VERSION ""

NS_ :

BS_:

BU_: PowertrainControlModule AtmosphericSensor SafetyRestraintSystem2 Aftertreatment_2_GasOutlet Aftertreatment_2_GasIntake DieselParticulateFilterControl Turbocharger SafetyRestraintSystem1 CabDisplay2 Aftertreatment_1_GasOutlet Aftertreatment_1_GasIntake OnBoardDataLogger OffBoardDiagnosticTool2 OffBoardDiagnosticTool1 FileServer ParkingBrakeController SeatController2 FanDriveController SteeringColumnUnit CommunicationUnitRadio CommunicationUnitSatellite CommunicationUnitCellular PropulsionBatteryCharger ChassisController2 ChassisController1 EngineValveControl AuxiliaryHeater2 AuxiliaryHeater1 ClutchUnit RampControl InformationSystem1 SuspensionSystemController2 OilSensor VehicleDynamicStability ExhaustEmissionController TransmissionDisplay2 TransmissionDisplay1 ClimateControl2 WaterPumpController RearAxleSteeringController LightingOperatorControl SeatController1 IgnitionController2 IgnitionController1 TirePressureController CabController2 CabController1 PneumaticSystemController SuspensionSystemController1 HydraulicPumpController EnduranceBrakingSystem RetarderExhaustEngine2 OnBoardDiagnosticUnit HeadwayController RetarderExhaustEngine1 CabDisplay1 ManagementComputer VirtualTerminal OffVehicleGateway PowerTakeOffFront HitchControl AuxiliaryValveControl BodyController TractorTrailerBridge1 StarterSystem ElectricalSystem VehicleSecurity VehicleNavigation AerodynamicControl ElectricalChargingSystem ClimateControl1 TripRecorder InstrumentCluster SuspensionDriveAxle2 SuspensionDriveAxle1 SuspensionSteerAxle SteeringController FuelSystem CruiseControl RetarderDriveline RetarderEngine BrakesDriveAxle2 BrakesDriveAxle1 BrakesSystemController BrakesSteerAxle AxleDrive2 AxleDrive1 AxleSteering PowerTakeOff ShiftConsoleSecondary ShiftConsolePrimary Transmission2 Transmission1 Engine2 Engine1

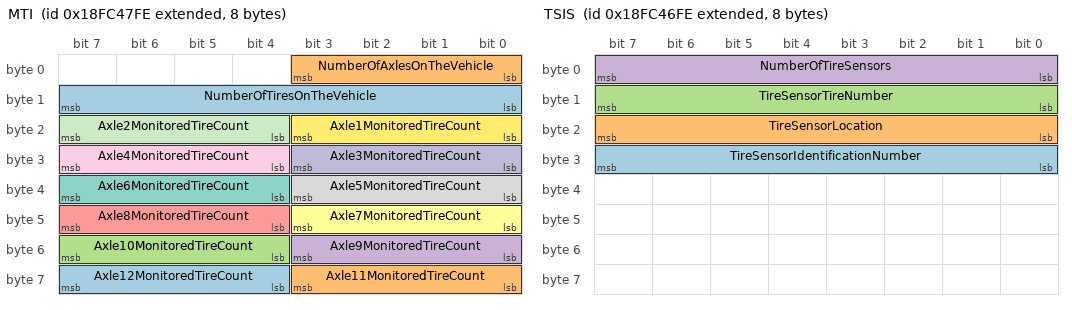
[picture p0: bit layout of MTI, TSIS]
BO_ 2566670334 MTI: 8 Vector__XXX
 SG_ Axle12MonitoredTireCount : 60|4@1+ (1,0) [0|13] "" Vector__XXX
 SG_ Axle11MonitoredTireCount : 56|4@1+ (1,0) [0|13] "" Vector__XXX
 SG_ Axle10MonitoredTireCount : 52|4@1+ (1,0) [0|13] "" Vector__XXX
 SG_ Axle9MonitoredTireCount : 48|4@1+ (1,0) [0|13] "" Vector__XXX
 SG_ Axle8MonitoredTireCount : 44|4@1+ (1,0) [0|13] "" Vector__XXX
 SG_ Axle7MonitoredTireCount : 40|4@1+ (1,0) [0|13] "" Vector__XXX
 SG_ Axle6MonitoredTireCount : 36|4@1+ (1,0) [0|13] "" Vector__XXX
 SG_ Axle5MonitoredTireCount : 32|4@1+ (1,0) [0|13] "" Vector__XXX
 SG_ Axle4MonitoredTireCount : 28|4@1+ (1,0) [0|13] "" Vector__XXX
 SG_ Axle3MonitoredTireCount : 24|4@1+ (1,0) [0|13] "" Vector__XXX
 SG_ Axle2MonitoredTireCount : 20|4@1+ (1,0) [0|13] "" Vector__XXX
 SG_ Axle1MonitoredTireCount : 16|4@1+ (1,0) [0|13] "" Vector__XXX
 SG_ NumberOfTiresOnTheVehicle : 8|8@1+ (1,0) [0|250] "" Vector__XXX
 SG_ NumberOfAxlesOnTheVehicle : 0|4@1+ (1,0) [0|13] "" Vector__XXX

BO_ 2566670078 TSIS: 8 Vector__XXX
 SG_ TireSensorIdentificationNumber : 24|8@1+ (1,0) [0|255] "" Vector__XXX
 SG_ TireSensorLocation : 16|8@1+ (1,0) [0|255] "" Vector__XXX
 SG_ TireSensorTireNumber : 8|8@1+ (1,0) [0|250] "" Vector__XXX
 SG_ NumberOfTireSensors : 0|8@1+ (1,0) [0|250] "" Vector__XXX

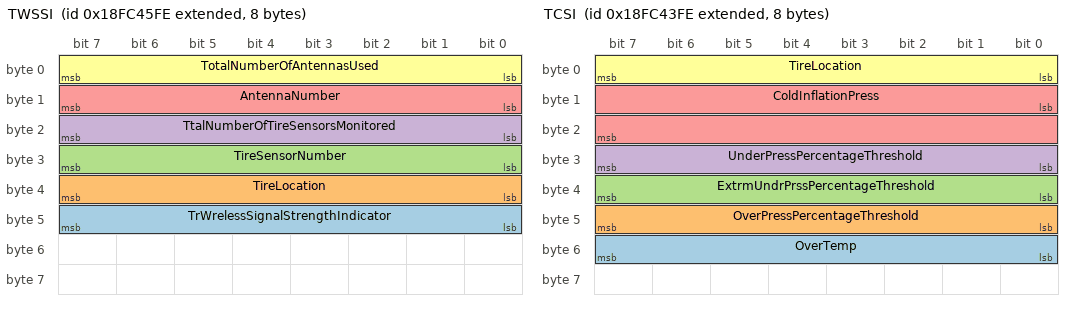
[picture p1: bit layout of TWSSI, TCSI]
BO_ 2566669822 TWSSI: 8 Vector__XXX
 SG_ TrWrelessSignalStrengthIndicator : 40|8@1+ (0.5,-125) [-125|0] "dBm" Vector__XXX
 SG_ TireLocation : 32|8@1+ (1,0) [0|0] "" Vector__XXX
 SG_ TireSensorNumber : 24|8@1+ (1,0) [0|250] "" Vector__XXX
 SG_ TtalNumberOfTireSensorsMonitored : 16|8@1+ (1,0) [0|250] "" Vector__XXX
 SG_ AntennaNumber : 8|8@1+ (1,0) [0|250] "" Vector__XXX
 SG_ TotalNumberOfAntennasUsed : 0|8@1+ (1,0) [0|250] "" Vector__XXX

BO_ 2566669310 TCSI: 8 Vector__XXX
 SG_ OverTemp : 48|8@1+ (1,-40) [-40|210] "캜" Vector__XXX
 SG_ OverPressPercentageThreshold : 40|8@1+ (0.5,0) [0|125] "%" Vector__XXX
 SG_ ExtrmUndrPrssPercentageThreshold : 32|8@1+ (0.5,0) [0|125] "%" Vector__XXX
 SG_ UnderPressPercentageThreshold : 24|8@1+ (0.5,0) [0|125] "%" Vector__XXX
 SG_ ColdInflationPress : 8|16@1+ (1,0) [0|64255] "kPa" Vector__XXX
 SG_ TireLocation : 0|8@1+ (1,0) [0|0] "" Vector__XXX

BO_ 2566669054 TIRE2: 8 Vector__XXX
 SG_ RequiredTirePress : 24|16@1+ (1,0) [0|64255] "kPa" Vector__XXX
 SG_ TirePress : 8|16@1+ (1,0) [0|64255] "kPa" Vector__XXX
 SG_ TireLocation : 0|8@1+ (1,0) [0|0] "" Vector__XXX

BO_ 2566668798 AF4: 8 Vector__XXX
 SG_ EngFl2InjctorMeteringRail1Press2 : 48|16@1+ (2,0) [0|128510] "kPa" Vector__XXX
 SG_ EngFel2InjectorMeteringRail2Temp : 40|8@1+ (1,-40) [-40|210] "캜" Vector__XXX
 SG_ EngFel2InjectorMeteringRail1Temp : 32|8@1+ (1,-40) [-40|210] "캜" Vector__XXX
 SG_ EngFl2InjectorMeteringRail2Press : 16|16@1+ (2,0) [0|128510] "kPa" Vector__XXX
 SG_ EngFl2InjectorMeteringRail1Press : 0|16@1+ (2,0) [0|128510] "kPa" Vector__XXX

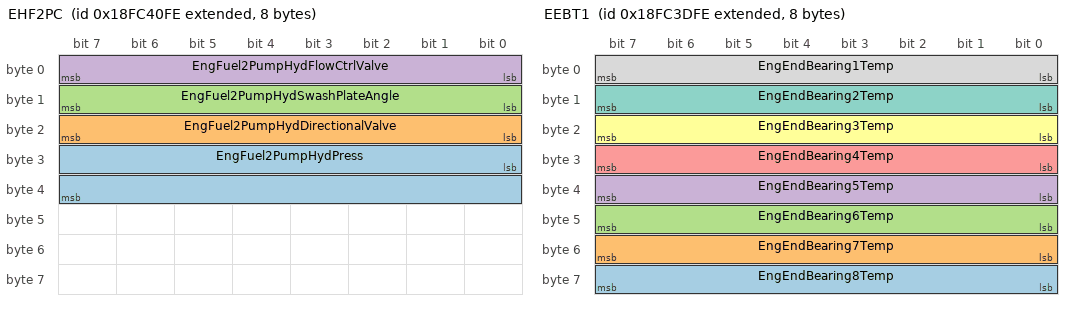
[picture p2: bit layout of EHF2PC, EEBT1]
BO_ 2566668542 EHF2PC: 8 Vector__XXX
 SG_ EngFuel2PumpHydPress : 24|16@1+ (2,0) [0|128510] "kPa" Vector__XXX
 SG_ EngFuel2PumpHydDirectionalValve : 16|8@1+ (0.4,0) [0|100] "%" Vector__XXX
 SG_ EngFuel2PumpHydSwashPlateAngle : 8|8@1+ (0.4,0) [0|100] "%" Vector__XXX
 SG_ EngFuel2PumpHydFlowCtrlValve : 0|8@1+ (0.4,0) [0|100] "%" Vector__XXX

BO_ 2566668286 ETCC2: 8 Vector__XXX
 SG_ EngStagedTurboSolenoidStatus : 0|8@1+ (0.4,0) [0|100] "%" Vector__XXX

BO_ 2566668030 HEDPI: 8 Vector__XXX
 SG_ HtExchngerDebrisPurgeApproaching : 2|2@1+ (1,0) [0|3] "" Vector__XXX
 SG_ HeatExchangerDebrisPurgeStatus : 0|2@1+ (1,0) [0|3] "" Vector__XXX

BO_ 2566667774 EEBT1: 8 Vector__XXX
 SG_ EngEndBearing8Temp : 56|8@1+ (1,-40) [-40|210] "캜" Vector__XXX
 SG_ EngEndBearing7Temp : 48|8@1+ (1,-40) [-40|210] "캜" Vector__XXX
 SG_ EngEndBearing6Temp : 40|8@1+ (1,-40) [-40|210] "캜" Vector__XXX
 SG_ EngEndBearing5Temp : 32|8@1+ (1,-40) [-40|210] "캜" Vector__XXX
 SG_ EngEndBearing4Temp : 24|8@1+ (1,-40) [-40|210] "캜" Vector__XXX
 SG_ EngEndBearing3Temp : 16|8@1+ (1,-40) [-40|210] "캜" Vector__XXX
 SG_ EngEndBearing2Temp : 8|8@1+ (1,-40) [-40|210] "캜" Vector__XXX
 SG_ EngEndBearing1Temp : 0|8@1+ (1,-40) [-40|210] "캜" Vector__XXX

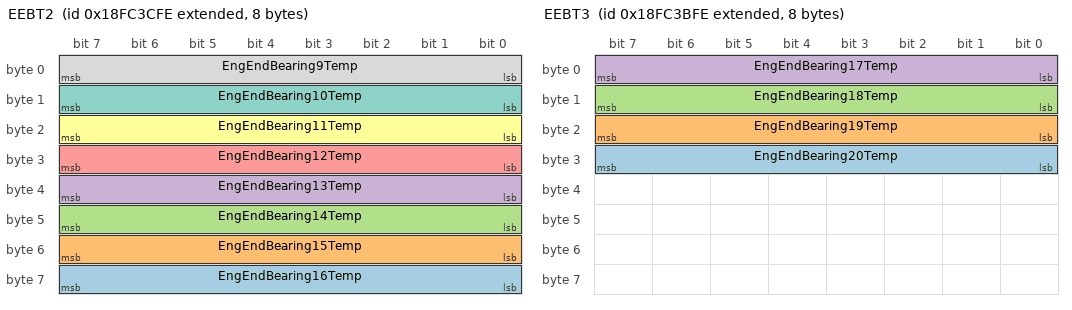
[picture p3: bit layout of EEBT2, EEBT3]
BO_ 2566667518 EEBT2: 8 Vector__XXX
 SG_ EngEndBearing16Temp : 56|8@1+ (1,-40) [-40|210] "캜" Vector__XXX
 SG_ EngEndBearing15Temp : 48|8@1+ (1,-40) [-40|210] "캜" Vector__XXX
 SG_ EngEndBearing14Temp : 40|8@1+ (1,-40) [-40|210] "캜" Vector__XXX
 SG_ EngEndBearing13Temp : 32|8@1+ (1,-40) [-40|210] "캜" Vector__XXX
 SG_ EngEndBearing12Temp : 24|8@1+ (1,-40) [-40|210] "캜" Vector__XXX
 SG_ EngEndBearing11Temp : 16|8@1+ (1,-40) [-40|210] "캜" Vector__XXX
 SG_ EngEndBearing10Temp : 8|8@1+ (1,-40) [-40|210] "캜" Vector__XXX
 SG_ EngEndBearing9Temp : 0|8@1+ (1,-40) [-40|210] "캜" Vector__XXX

BO_ 2566667262 EEBT3: 8 Vector__XXX
 SG_ EngEndBearing20Temp : 24|8@1+ (1,-40) [-40|210] "캜" Vector__XXX
 SG_ EngEndBearing19Temp : 16|8@1+ (1,-40) [-40|210] "캜" Vector__XXX
 SG_ EngEndBearing18Temp : 8|8@1+ (1,-40) [-40|210] "캜" Vector__XXX
 SG_ EngEndBearing17Temp : 0|8@1+ (1,-40) [-40|210] "캜" Vector__XXX

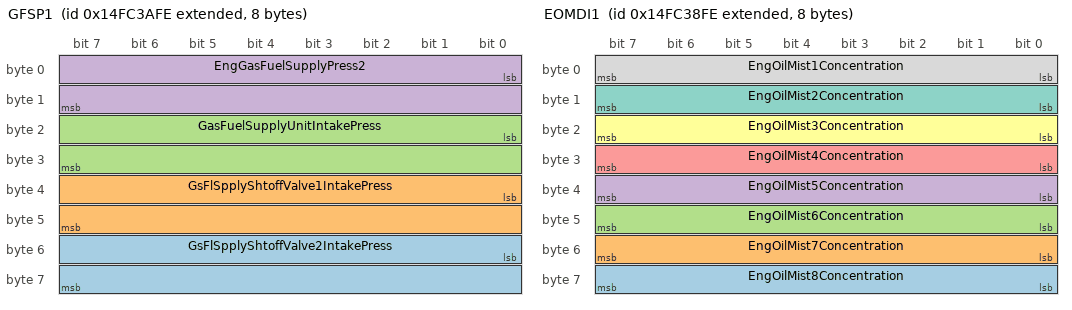
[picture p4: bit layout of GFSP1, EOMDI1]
BO_ 2499558142 GFSP1: 8 Vector__XXX
 SG_ GsFlSpplyShtoffValve2IntakePress : 48|16@1+ (0.5,0) [0|32127.5] "kPa" Vector__XXX
 SG_ GsFlSpplyShtoffValve1IntakePress : 32|16@1+ (0.5,0) [0|32127.5] "kPa" Vector__XXX
 SG_ GasFuelSupplyUnitIntakePress : 16|16@1+ (0.5,0) [0|32127.5] "kPa" Vector__XXX
 SG_ EngGasFuelSupplyPress2 : 0|16@1+ (0.5,0) [0|32127.5] "kPa" Vector__XXX

BO_ 2499557886 GFSP2: 8 Vector__XXX
 SG_ PlantInertGasSupplyOutletPress : 16|16@1+ (0.5,0) [0|32127.5] "kPa" Vector__XXX
 SG_ PlantGasFuelSupplyOutletPress : 0|16@1+ (0.5,0) [0|32127.5] "kPa" Vector__XXX

BO_ 2499557630 EOMDI1: 8 Vector__XXX
 SG_ EngOilMist8Concentration : 56|8@1+ (1,0) [0|250] "%" Vector__XXX
 SG_ EngOilMist7Concentration : 48|8@1+ (1,0) [0|250] "%" Vector__XXX
 SG_ EngOilMist6Concentration : 40|8@1+ (1,0) [0|250] "%" Vector__XXX
 SG_ EngOilMist5Concentration : 32|8@1+ (1,0) [0|250] "%" Vector__XXX
 SG_ EngOilMist4Concentration : 24|8@1+ (1,0) [0|250] "%" Vector__XXX
 SG_ EngOilMist3Concentration : 16|8@1+ (1,0) [0|250] "%" Vector__XXX
 SG_ EngOilMist2Concentration : 8|8@1+ (1,0) [0|250] "%" Vector__XXX
 SG_ EngOilMist1Concentration : 0|8@1+ (1,0) [0|250] "%" Vector__XXX

BO_ 2499557374 EOMDI2: 8 Vector__XXX
 SG_ EngOilMist10Concentration : 8|8@1+ (1,0) [0|250] "%" Vector__XXX
 SG_ EngOilMist9Concentration : 0|8@1+ (1,0) [0|250] "%" Vector__XXX

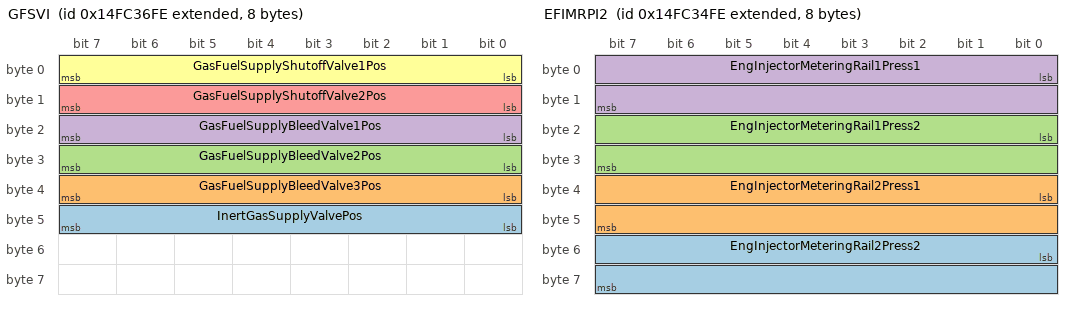
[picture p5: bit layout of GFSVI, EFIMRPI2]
BO_ 2499557118 GFSVI: 8 Vector__XXX
 SG_ InertGasSupplyValvePos : 40|8@1+ (0.4,0) [0|100] "%" Vector__XXX
 SG_ GasFuelSupplyBleedValve3Pos : 32|8@1+ (0.4,0) [0|100] "%" Vector__XXX
 SG_ GasFuelSupplyBleedValve2Pos : 24|8@1+ (0.4,0) [0|100] "%" Vector__XXX
 SG_ GasFuelSupplyBleedValve1Pos : 16|8@1+ (0.4,0) [0|100] "%" Vector__XXX
 SG_ GasFuelSupplyShutoffValve2Pos : 8|8@1+ (0.4,0) [0|100] "%" Vector__XXX
 SG_ GasFuelSupplyShutoffValve1Pos : 0|8@1+ (0.4,0) [0|100] "%" Vector__XXX

BO_ 2566665726 AT2P1I: 8 Vector__XXX
 SG_ TwoMotorSpd : 8|16@1+ (0.5,0) [0|32127.5] "rpm" Vector__XXX
 SG_ Htr : 0|8@1+ (0.4,0) [0|100] "%" Vector__XXX

BO_ 2499556606 EFIMRPI2: 8 Vector__XXX
 SG_ EngInjectorMeteringRail2Press2 : 48|16@1+ (5,0) [0|321275] "kPa" Vector__XXX
 SG_ EngInjectorMeteringRail2Press1 : 32|16@1+ (5,0) [0|321275] "kPa" Vector__XXX
 SG_ EngInjectorMeteringRail1Press2 : 16|16@1+ (5,0) [0|321275] "kPa" Vector__XXX
 SG_ EngInjectorMeteringRail1Press1 : 0|16@1+ (5,0) [0|321275] "kPa" Vector__XXX

BO_ 2499556350 EFIMRPI3: 8 Vector__XXX
 SG_ EngInjctrMtringRail2DesiredPress : 16|16@1+ (5,0) [0|321275] "kPa" Vector__XXX
 SG_ EngInjctrMtringRail1DesiredPress : 0|16@1+ (5,0) [0|321275] "kPa" Vector__XXX

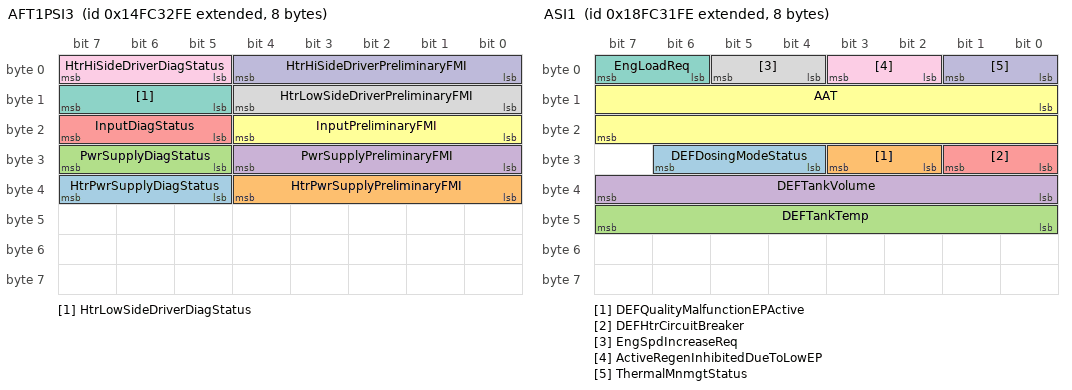
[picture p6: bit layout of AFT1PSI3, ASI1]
BO_ 2499556094 AFT1PSI3: 8 Vector__XXX
 SG_ HtrPwrSupplyDiagStatus : 37|3@1+ (1,0) [0|7] "" Vector__XXX
 SG_ HtrPwrSupplyPreliminaryFMI : 32|5@1+ (1,0) [0|31] "" Vector__XXX
 SG_ PwrSupplyDiagStatus : 29|3@1+ (1,0) [0|7] "" Vector__XXX
 SG_ PwrSupplyPreliminaryFMI : 24|5@1+ (1,0) [0|31] "" Vector__XXX
 SG_ InputDiagStatus : 21|3@1+ (1,0) [0|7] "" Vector__XXX
 SG_ InputPreliminaryFMI : 16|5@1+ (1,0) [0|31] "" Vector__XXX
 SG_ HtrLowSideDriverDiagStatus : 13|3@1+ (1,0) [0|7] "" Vector__XXX
 SG_ HtrLowSideDriverPreliminaryFMI : 8|5@1+ (1,0) [0|31] "" Vector__XXX
 SG_ HtrHiSideDriverDiagStatus : 5|3@1+ (1,0) [0|7] "" Vector__XXX
 SG_ HtrHiSideDriverPreliminaryFMI : 0|5@1+ (1,0) [0|31] "" Vector__XXX

BO_ 2566664702 ASI1: 8 Vector__XXX
 SG_ DEFDosingModeStatus : 28|3@1+ (1,0) [0|7] "" Vector__XXX
 SG_ DEFQualityMalfunctionEPActive : 26|2@1+ (1,0) [0|3] "" Vector__XXX
 SG_ DEFTankTemp : 40|8@1+ (1,-40) [-40|210] "캜" Vector__XXX
 SG_ DEFTankVolume : 32|8@1+ (0.4,0) [0|100] "%" Vector__XXX
 SG_ DEFHtrCircuitBreaker : 24|2@1+ (1,0) [0|3] "" Vector__XXX
 SG_ AAT : 8|16@1+ (0.03125,-273) [-273|1734.96875] "캜" Vector__XXX
 SG_ EngLoadReq : 6|2@1+ (1,0) [0|3] "" Vector__XXX
 SG_ EngSpdIncreaseReq : 4|2@1+ (1,0) [0|3] "" Vector__XXX
 SG_ ActiveRegenInhibitedDueToLowEP : 2|2@1+ (1,0) [0|3] "" Vector__XXX
 SG_ ThermalMnmgtStatus : 0|2@1+ (1,0) [0|3] "" Vector__XXX

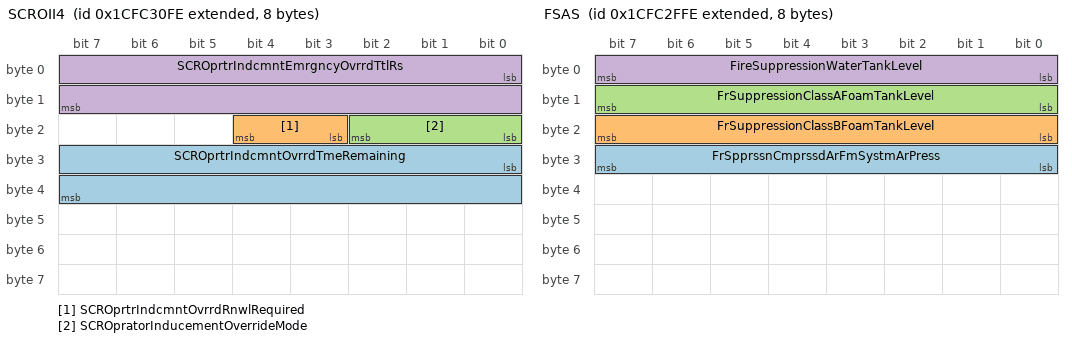
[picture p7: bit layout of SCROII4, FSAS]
BO_ 2633773310 SCROII4: 8 Vector__XXX
 SG_ SCROprtrIndcmntOvrrdTmeRemaining : 24|16@1+ (1,0) [0|64255] "min" Vector__XXX
 SG_ SCROprtrIndcmntOvrrdRnwlRequired : 19|2@1+ (1,0) [0|3] "" Vector__XXX
 SG_ SCROpratorInducementOverrideMode : 16|3@1+ (1,0) [0|7] "" Vector__XXX
 SG_ SCROprtrIndcmntEmrgncyOvrrdTtlRs : 0|16@1+ (1,0) [0|64255] "" Vector__XXX

BO_ 2633773054 FSAS: 8 Vector__XXX
 SG_ FrSpprssnCmprssdArFmSystmArPress : 24|8@1+ (8,0) [0|2000] "kPa" Vector__XXX
 SG_ FrSuppressionClassBFoamTankLevel : 16|8@1+ (0.4,0) [0|100] "%" Vector__XXX
 SG_ FrSuppressionClassAFoamTankLevel : 8|8@1+ (0.4,0) [0|100] "%" Vector__XXX
 SG_ FireSuppressionWaterTankLevel : 0|8@1+ (0.4,0) [0|100] "%" Vector__XXX

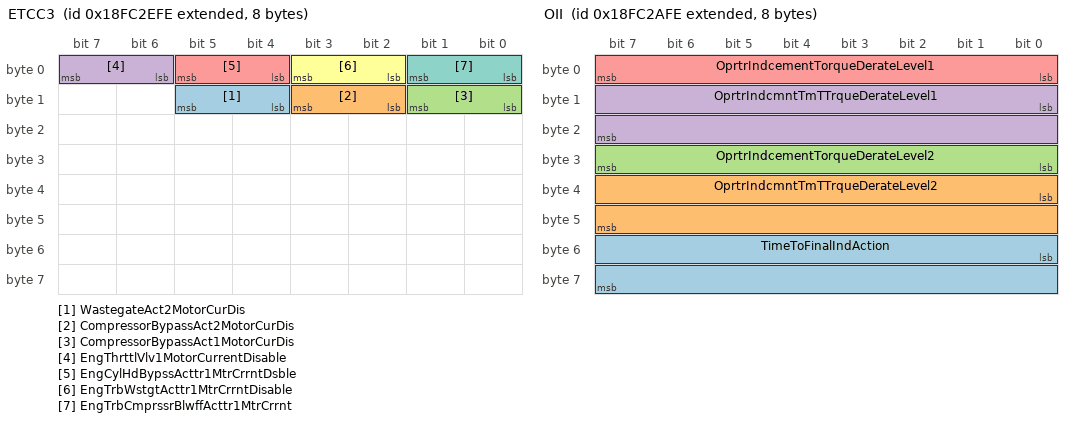
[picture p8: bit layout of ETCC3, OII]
BO_ 2566663934 ETCC3: 8 Vector__XXX
 SG_ WastegateAct2MotorCurDis : 12|2@1+ (1,0) [0|3] "" Vector__XXX
 SG_ CompressorBypassAct2MotorCurDis : 10|2@1+ (1,0) [0|3] "" Vector__XXX
 SG_ CompressorBypassAct1MotorCurDis : 8|2@1+ (1,0) [0|3] "" Vector__XXX
 SG_ EngThrttlVlv1MotorCurrentDisable : 6|2@1+ (1,0) [0|3] "" Vector__XXX
 SG_ EngCylHdBypssActtr1MtrCrrntDsble : 4|2@1+ (1,0) [0|3] "" Vector__XXX
 SG_ EngTrbWstgtActtr1MtrCrrntDisable : 2|2@1+ (1,0) [0|3] "" Vector__XXX
 SG_ EngTrbCmprssrBlwffActtr1MtrCrrnt : 0|2@1+ (1,0) [0|3] "" Vector__XXX

BO_ 2566663678 AF5: 8 Vector__XXX
 SG_ EngFl2InjectorMeteringRail1Temp2 : 32|8@1+ (1,-40) [-40|210] "캜" Vector__XXX
 SG_ LNGTank2VaporPress : 16|16@1+ (0.1,0) [0|6425.5] "kPa" Vector__XXX
 SG_ LNGTank1VaporPress : 0|16@1+ (0.1,0) [0|6425.5] "kPa" Vector__XXX

BO_ 2566663422 BCLC: 8 Vector__XXX
 SG_ TrlrBrkClprLnngClranceAxle5Right : 38|2@1+ (1,0) [0|3] "" Vector__XXX
 SG_ TrlrBrkClprLnngClaranceAxle5Left : 36|2@1+ (1,0) [0|3] "" Vector__XXX
 SG_ TrlrBrkClprLnngClranceAxle4Right : 34|2@1+ (1,0) [0|3] "" Vector__XXX
 SG_ TrlrBrkClprLnngClaranceAxle4Left : 32|2@1+ (1,0) [0|3] "" Vector__XXX
 SG_ TrlrBrkClprLnngClranceAxle3Right : 30|2@1+ (1,0) [0|3] "" Vector__XXX
 SG_ TrlrBrkClprLnngClaranceAxle3Left : 28|2@1+ (1,0) [0|3] "" Vector__XXX
 SG_ TrlrBrkClprLnngClranceAxle2Right : 26|2@1+ (1,0) [0|3] "" Vector__XXX
 SG_ TrlrBrkClprLnngClaranceAxle2Left : 24|2@1+ (1,0) [0|3] "" Vector__XXX
 SG_ TrlrBrkClprLnngClranceAxle1Right : 22|2@1+ (1,0) [0|3] "" Vector__XXX
 SG_ TrlrBrkClprLnngClaranceAxle1Left : 20|2@1+ (1,0) [0|3] "" Vector__XXX
 SG_ TrctrBrkClprLnngClrnceAxle5Right : 18|2@1+ (1,0) [0|3] "" Vector__XXX
 SG_ TrctrBrkClprLnngClranceAxle5Left : 16|2@1+ (1,0) [0|3] "" Vector__XXX
 SG_ TrctrBrkClprLnngClrnceAxle4Right : 14|2@1+ (1,0) [0|3] "" Vector__XXX
 SG_ TrctrBrkClprLnngClranceAxle4Left : 12|2@1+ (1,0) [0|3] "" Vector__XXX
 SG_ TrctrBrkClprLnngClrnceAxle3Right : 10|2@1+ (1,0) [0|3] "" Vector__XXX
 SG_ TrctrBrkClprLnngClranceAxle3Left : 8|2@1+ (1,0) [0|3] "" Vector__XXX
 SG_ TrctrBrkClprLnngClrnceAxle2Right : 6|2@1+ (1,0) [0|3] "" Vector__XXX
 SG_ TrctrBrkClprLnngClranceAxle2Left : 4|2@1+ (1,0) [0|3] "" Vector__XXX
 SG_ TrctrBrkClprLnngClrnceAxle1Right : 2|2@1+ (1,0) [0|3] "" Vector__XXX
 SG_ TrctrBrkClprLnngClranceAxle1Left : 0|2@1+ (1,0) [0|3] "" Vector__XXX

BO_ 2566663166 CCVS4: 8 Vector__XXX
 SG_ EngExtlIdleReqFeedback : 32|2@1+ (1,0) [0|3] "" Vector__XXX
 SG_ CruiseCtrlAdjustedMaxSpeed : 16|16@1+ (0.00390625,0) [0|250.996] "km/h" Vector__XXX
 SG_ AppliedVehicleSpeedLimit : 0|16@1+ (0.00390625,0) [0|250.996] "km/h" Vector__XXX

BO_ 2566662910 OII: 8 Vector__XXX
 SG_ TimeToFinalIndAction : 48|16@1+ (1,0) [0|64255] "min" Vector__XXX
 SG_ OprtrIndcmntTmTTrqueDerateLevel2 : 32|16@1+ (1,0) [0|64255] "min" Vector__XXX
 SG_ OprtrIndcementTorqueDerateLevel2 : 24|8@1+ (1,0) [0|250] "%" Vector__XXX
 SG_ OprtrIndcmntTmTTrqueDerateLevel1 : 8|16@1+ (1,0) [0|64255] "min" Vector__XXX
 SG_ OprtrIndcementTorqueDerateLevel1 : 0|8@1+ (1,0) [0|250] "%" Vector__XXX

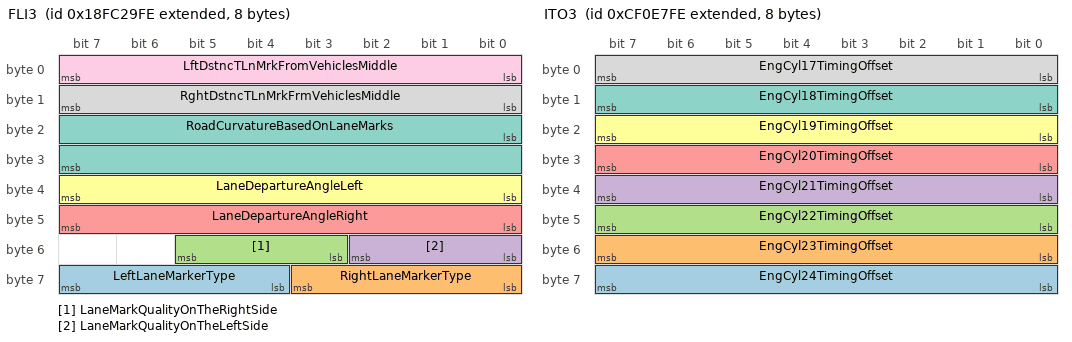
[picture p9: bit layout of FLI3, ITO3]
BO_ 2566662654 FLI3: 8 Vector__XXX
 SG_ LeftLaneMarkerType : 60|4@1+ (1,0) [0|15] "" Vector__XXX
 SG_ RightLaneMarkerType : 56|4@1+ (1,0) [0|15] "" Vector__XXX
 SG_ LaneMarkQualityOnTheRightSide : 51|3@1+ (1,0) [0|7] "" Vector__XXX
 SG_ LaneMarkQualityOnTheLeftSide : 48|3@1+ (1,0) [0|7] "" Vector__XXX
 SG_ LaneDepartureAngleRight : 40|8@1+ (0.1,-12.5) [-12.5|12.5] "deg" Vector__XXX
 SG_ LaneDepartureAngleLeft : 32|8@1+ (0.1,-12.5) [-12.5|12.5] "deg" Vector__XXX
 SG_ RoadCurvatureBasedOnLaneMarks : 16|16@1+ (0.0078125,-250) [-250|251.992] "1/km" Vector__XXX
 SG_ RghtDstncTLnMrkFrmVehiclesMiddle : 8|8@1+ (0.02,0) [0|5] "m" Vector__XXX
 SG_ LftDstncTLnMrkFromVehiclesMiddle : 0|8@1+ (0.02,0) [0|5] "m" Vector__XXX

BO_ 2566662142 A1DEFI2: 8 Vector__XXX
 SG_ Ctrl2Temp : 8|8@1+ (1,-40) [-40|210] "캜" Vector__XXX
 SG_ Ctrl1Temp : 0|8@1+ (1,-40) [-40|210] "캜" Vector__XXX

BO_ 2566661630 AT1T1I2: 8 Vector__XXX
 SG_ Htr2 : 16|8@1+ (0.4,0) [0|100] "%" Vector__XXX
 SG_ Temp2 : 8|8@1+ (1,-40) [-40|210] "캜" Vector__XXX
 SG_ Volume2 : 0|8@1+ (0.4,0) [0|100] "%" Vector__XXX

BO_ 2566661374 AT2T1I2: 8 Vector__XXX
 SG_ Htr2 : 16|8@1+ (0.4,0) [0|100] "%" Vector__XXX
 SG_ Temp2 : 8|8@1+ (1,-40) [-40|210] "캜" Vector__XXX
 SG_ Volume2 : 0|8@1+ (0.4,0) [0|100] "%" Vector__XXX

BO_ 2364598270 ITO3: 8 Vector__XXX
 SG_ EngCyl24TimingOffset : 56|8@1+ (0.1,-12.5) [-12.5|12.5] "deg" Vector__XXX
 SG_ EngCyl23TimingOffset : 48|8@1+ (0.1,-12.5) [-12.5|12.5] "deg" Vector__XXX
 SG_ EngCyl22TimingOffset : 40|8@1+ (0.1,-12.5) [-12.5|12.5] "deg" Vector__XXX
 SG_ EngCyl21TimingOffset : 32|8@1+ (0.1,-12.5) [-12.5|12.5] "deg" Vector__XXX
 SG_ EngCyl20TimingOffset : 24|8@1+ (0.1,-12.5) [-12.5|12.5] "deg" Vector__XXX
 SG_ EngCyl19TimingOffset : 16|8@1+ (0.1,-12.5) [-12.5|12.5] "deg" Vector__XXX
 SG_ EngCyl18TimingOffset : 8|8@1+ (0.1,-12.5) [-12.5|12.5] "deg" Vector__XXX
 SG_ EngCyl17TimingOffset : 0|8@1+ (0.1,-12.5) [-12.5|12.5] "deg" Vector__XXX

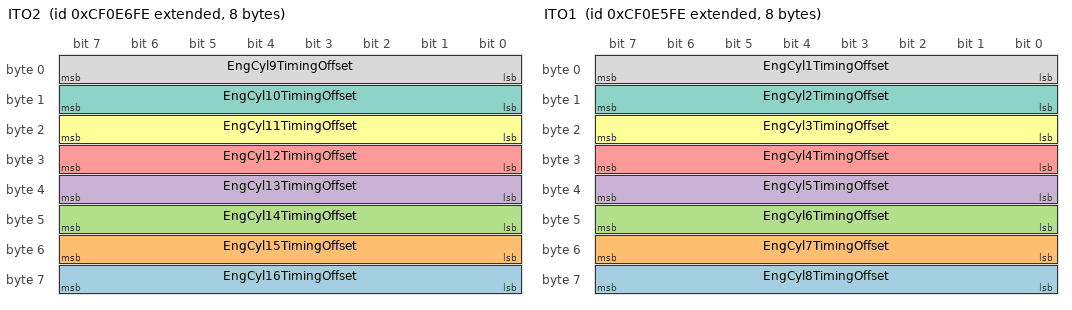
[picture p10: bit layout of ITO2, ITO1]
BO_ 2364598014 ITO2: 8 Vector__XXX
 SG_ EngCyl16TimingOffset : 56|8@1+ (0.1,-12.5) [-12.5|12.5] "deg" Vector__XXX
 SG_ EngCyl15TimingOffset : 48|8@1+ (0.1,-12.5) [-12.5|12.5] "deg" Vector__XXX
 SG_ EngCyl14TimingOffset : 40|8@1+ (0.1,-12.5) [-12.5|12.5] "deg" Vector__XXX
 SG_ EngCyl13TimingOffset : 32|8@1+ (0.1,-12.5) [-12.5|12.5] "deg" Vector__XXX
 SG_ EngCyl12TimingOffset : 24|8@1+ (0.1,-12.5) [-12.5|12.5] "deg" Vector__XXX
 SG_ EngCyl11TimingOffset : 16|8@1+ (0.1,-12.5) [-12.5|12.5] "deg" Vector__XXX
 SG_ EngCyl10TimingOffset : 8|8@1+ (0.1,-12.5) [-12.5|12.5] "deg" Vector__XXX
 SG_ EngCyl9TimingOffset : 0|8@1+ (0.1,-12.5) [-12.5|12.5] "deg" Vector__XXX

BO_ 2364597758 ITO1: 8 Vector__XXX
 SG_ EngCyl8TimingOffset : 56|8@1+ (0.1,-12.5) [-12.5|12.5] "deg" Vector__XXX
 SG_ EngCyl7TimingOffset : 48|8@1+ (0.1,-12.5) [-12.5|12.5] "deg" Vector__XXX
 SG_ EngCyl6TimingOffset : 40|8@1+ (0.1,-12.5) [-12.5|12.5] "deg" Vector__XXX
 SG_ EngCyl5TimingOffset : 32|8@1+ (0.1,-12.5) [-12.5|12.5] "deg" Vector__XXX
 SG_ EngCyl4TimingOffset : 24|8@1+ (0.1,-12.5) [-12.5|12.5] "deg" Vector__XXX
 SG_ EngCyl3TimingOffset : 16|8@1+ (0.1,-12.5) [-12.5|12.5] "deg" Vector__XXX
 SG_ EngCyl2TimingOffset : 8|8@1+ (0.1,-12.5) [-12.5|12.5] "deg" Vector__XXX
 SG_ EngCyl1TimingOffset : 0|8@1+ (0.1,-12.5) [-12.5|12.5] "deg" Vector__XXX

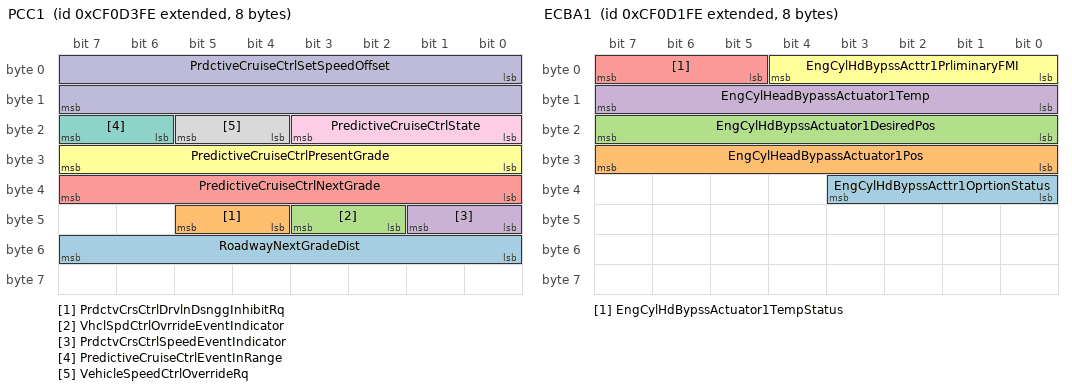
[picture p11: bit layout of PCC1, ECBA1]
BO_ 2364593150 PCC1: 8 Vector__XXX
 SG_ RoadwayNextGradeDist : 48|8@1+ (25,0) [0|6250] "m" Vector__XXX
 SG_ PrdctvCrsCtrlDrvlnDsnggInhibitRq : 44|2@1+ (1,0) [0|3] "" Vector__XXX
 SG_ VhclSpdCtrlOvrrideEventIndicator : 42|2@1+ (1,0) [0|3] "" Vector__XXX
 SG_ PrdctvCrsCtrlSpeedEventIndicator : 40|2@1+ (1,0) [0|3] "" Vector__XXX
 SG_ PredictiveCruiseCtrlNextGrade : 32|8@1+ (0.125,-16) [-16|15.25] "%" Vector__XXX
 SG_ PredictiveCruiseCtrlPresentGrade : 24|8@1+ (0.125,-16) [-16|15.25] "%" Vector__XXX
 SG_ PredictiveCruiseCtrlEventInRange : 22|2@1+ (1,0) [0|3] "" Vector__XXX
 SG_ VehicleSpeedCtrlOverrideRq : 20|2@1+ (1,0) [0|3] "" Vector__XXX
 SG_ PredictiveCruiseCtrlState : 16|4@1+ (1,0) [0|15] "" Vector__XXX
 SG_ PrdctiveCruiseCtrlSetSpeedOffset : 0|16@1+ (0.00390625,-125) [-125|125.996] "km/h" Vector__XXX

BO_ 2364592894 EEC18: 8 Vector__XXX
 SG_ ExhGasRestrictionVlvPos : 32|16@1+ (0.0025,0) [0|160.6375] "%" Vector__XXX
 SG_ InAirSourceVlv : 16|2@1+ (1,0) [0|3] "" Vector__XXX
 SG_ EngCylHeadBypassActuator1Cmd : 0|16@1+ (0.0025,0) [0|160.6375] "%" Vector__XXX

BO_ 2364592638 ECBA1: 8 Vector__XXX
 SG_ EngCylHdBypssActtr1OprtionStatus : 32|4@1+ (1,0) [0|15] "" Vector__XXX
 SG_ EngCylHeadBypassActuator1Pos : 24|8@1+ (0.4,0) [0|100] "%" Vector__XXX
 SG_ EngCylHdBypssActuator1DesiredPos : 16|8@1+ (0.4,0) [0|100] "%" Vector__XXX
 SG_ EngCylHeadBypassActuator1Temp : 8|8@1+ (1,-40) [-40|210] "캜" Vector__XXX
 SG_ EngCylHdBypssActuator1TempStatus : 5|3@1+ (1,0) [0|7] "" Vector__XXX
 SG_ EngCylHdBypssActtr1PrliminaryFMI : 0|5@1+ (1,0) [0|31] "" Vector__XXX

BO_ 2364592382 ECCR: 8 Vector__XXX
 SG_ EngCyl24ExcludeFromCombustionRq : 54|2@1+ (1,0) [0|3] "" Vector__XXX
 SG_ EngCyl23ExcludeFromCombustionRq : 52|2@1+ (1,0) [0|3] "" Vector__XXX
 SG_ EngCyl22ExcludeFromCombustionRq : 50|2@1+ (1,0) [0|3] "" Vector__XXX
 SG_ EngCyl21ExcludeFromCombustionRq : 48|2@1+ (1,0) [0|3] "" Vector__XXX
 SG_ EngCyl20ExcludeFromCombustionRq : 46|2@1+ (1,0) [0|3] "" Vector__XXX
 SG_ EngCyl19ExcludeFromCombustionRq : 44|2@1+ (1,0) [0|3] "" Vector__XXX
 SG_ EngCyl18ExcludeFromCombustionRq : 42|2@1+ (1,0) [0|3] "" Vector__XXX
 SG_ EngCyl17ExcludeFromCombustionRq : 40|2@1+ (1,0) [0|3] "" Vector__XXX
 SG_ EngCyl16ExcludeFromCombustionRq : 38|2@1+ (1,0) [0|3] "" Vector__XXX
 SG_ EngCyl15ExcludeFromCombustionRq : 36|2@1+ (1,0) [0|3] "" Vector__XXX
 SG_ EngCyl14ExcludeFromCombustionRq : 34|2@1+ (1,0) [0|3] "" Vector__XXX
 SG_ EngCyl13ExcludeFromCombustionRq : 32|2@1+ (1,0) [0|3] "" Vector__XXX
 SG_ EngCyl12ExcludeFromCombustionRq : 30|2@1+ (1,0) [0|3] "" Vector__XXX
 SG_ EngCyl11ExcludeFromCombustionRq : 28|2@1+ (1,0) [0|3] "" Vector__XXX
 SG_ EngCyl10ExcludeFromCombustionRq : 26|2@1+ (1,0) [0|3] "" Vector__XXX
 SG_ EngCyl9ExcludeFromCombustionRq : 24|2@1+ (1,0) [0|3] "" Vector__XXX
 SG_ EngCyl8ExcludeFromCombustionRq : 22|2@1+ (1,0) [0|3] "" Vector__XXX
 SG_ EngCyl7ExcludeFromCombustionRq : 20|2@1+ (1,0) [0|3] "" Vector__XXX
 SG_ EngCyl6ExcludeFromCombustionRq : 18|2@1+ (1,0) [0|3] "" Vector__XXX
 SG_ EngCyl5ExcludeFromCombustionRq : 16|2@1+ (1,0) [0|3] "" Vector__XXX
 SG_ EngCyl4ExcludeFromCombustionRq : 14|2@1+ (1,0) [0|3] "" Vector__XXX
 SG_ EngCyl3ExcludeFromCombustionRq : 12|2@1+ (1,0) [0|3] "" Vector__XXX
 SG_ EngCyl2ExcludeFromCombustionRq : 10|2@1+ (1,0) [0|3] "" Vector__XXX
 SG_ EngCyl1ExcludeFromCombustionRq : 8|2@1+ (1,0) [0|3] "" Vector__XXX
 SG_ NmbrOfEngCylndrsTExcldFrmCmbston : 0|8@1+ (1,0) [0|24] "" Vector__XXX

BO_ 2364567294 FPAC: 8 Vector__XXX
 SG_ EngFlInjctnPump2FuelCtrlValveCmd : 16|16@1+ (0.0025,0) [0|100] "%" Vector__XXX
 SG_ EngFlInjctnPump1FuelCtrlValveCmd : 0|16@1+ (0.0025,0) [0|100] "%" Vector__XXX

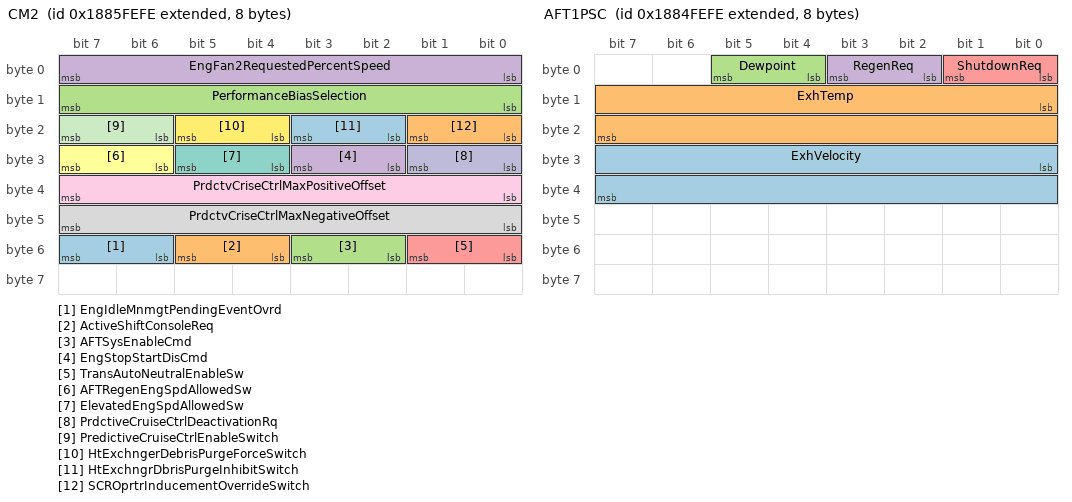
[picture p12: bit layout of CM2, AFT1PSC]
BO_ 2558918398 CM2: 8 Vector__XXX
 SG_ EngIdleMnmgtPendingEventOvrd : 54|2@1+ (1,0) [0|3] "" Vector__XXX
 SG_ ActiveShiftConsoleReq : 52|2@1+ (1,0) [0|3] "" Vector__XXX
 SG_ AFTSysEnableCmd : 50|2@1+ (1,0) [0|3] "" Vector__XXX
 SG_ EngStopStartDisCmd : 26|2@1+ (1,0) [0|3] "" Vector__XXX
 SG_ TransAutoNeutralEnableSw : 48|2@1+ (1,0) [0|3] "" Vector__XXX
 SG_ AFTRegenEngSpdAllowedSw : 30|2@1+ (1,0) [0|3] "" Vector__XXX
 SG_ ElevatedEngSpdAllowedSw : 28|2@1+ (1,0) [0|3] "" Vector__XXX
 SG_ PrdctvCriseCtrlMaxNegativeOffset : 40|8@1+ (0.125,-31.25) [-31.25|0] "km/h" Vector__XXX
 SG_ PrdctvCriseCtrlMaxPositiveOffset : 32|8@1+ (0.125,0) [0|31.25] "km/h" Vector__XXX
 SG_ PrdctiveCruiseCtrlDeactivationRq : 24|2@1+ (1,0) [0|3] "" Vector__XXX
 SG_ PredictiveCruiseCtrlEnableSwitch : 22|2@1+ (1,0) [0|3] "" Vector__XXX
 SG_ HtExchngerDebrisPurgeForceSwitch : 20|2@1+ (1,0) [0|3] "" Vector__XXX
 SG_ HtExchngrDbrisPurgeInhibitSwitch : 18|2@1+ (1,0) [0|3] "" Vector__XXX
 SG_ SCROprtrInducementOverrideSwitch : 16|2@1+ (1,0) [0|3] "" Vector__XXX
 SG_ PerformanceBiasSelection : 8|8@1+ (0.4,0) [0|100] "%" Vector__XXX
 SG_ EngFan2RequestedPercentSpeed : 0|8@1+ (0.4,0) [0|100] "%" Vector__XXX

BO_ 2558852862 AFT1PSC: 8 Vector__XXX
 SG_ ExhVelocity : 24|16@1+ (0.00390625,0) [0|250.996] "km/h" Vector__XXX
 SG_ ExhTemp : 8|16@1+ (0.03125,-273) [-273|1734.96875] "캜" Vector__XXX
 SG_ Dewpoint : 4|2@1+ (1,0) [0|3] "" Vector__XXX
 SG_ RegenReq : 2|2@1+ (1,0) [0|3] "" Vector__XXX
 SG_ ShutdownReq : 0|2@1+ (1,0) [0|3] "" Vector__XXX

BO_ 2558787326 PCIC: 8 Vector__XXX
 SG_ PayloadCorrectionFactorCmd : 24|8@1+ (1,-125) [-125|125] "%" Vector__XXX
 SG_ PayloadCalibCommandedWeight : 8|16@1+ (2,0) [0|128510] "kg" Vector__XXX
 SG_ PayloadCalibSetPointCmd : 0|4@1+ (1,0) [0|15] "" Vector__XXX

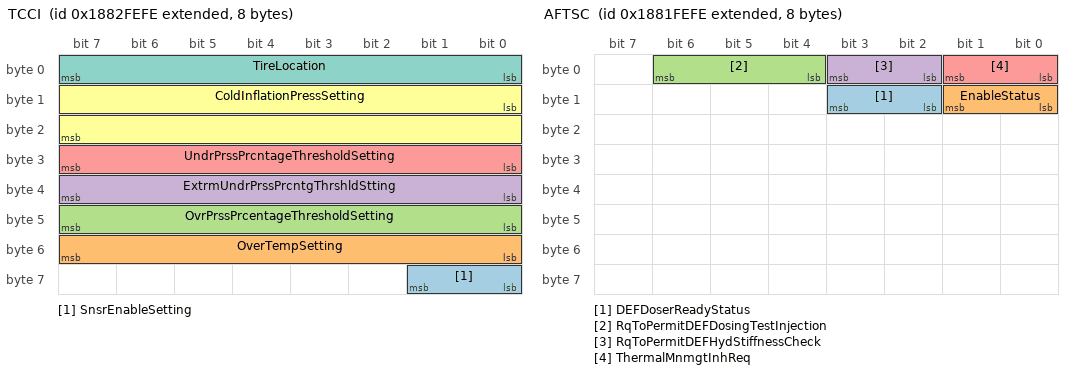
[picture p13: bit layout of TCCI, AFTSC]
BO_ 2558721790 TCCI: 8 Vector__XXX
 SG_ SnsrEnableSetting : 56|2@1+ (1,0) [0|3] "" Vector__XXX
 SG_ OverTempSetting : 48|8@1+ (1,-40) [-40|210] "캜" Vector__XXX
 SG_ OvrPrssPrcentageThresholdSetting : 40|8@1+ (0.5,0) [0|125] "%" Vector__XXX
 SG_ ExtrmUndrPrssPrcntgThrshldStting : 32|8@1+ (0.5,0) [0|125] "%" Vector__XXX
 SG_ UndrPrssPrcntageThresholdSetting : 24|8@1+ (0.5,0) [0|125] "%" Vector__XXX
 SG_ ColdInflationPressSetting : 8|16@1+ (1,0) [0|64255] "kPa" Vector__XXX
 SG_ TireLocation : 0|8@1+ (1,0) [0|0] "" Vector__XXX

BO_ 2558656254 AFTSC: 8 Vector__XXX
 SG_ DEFDoserReadyStatus : 10|2@1+ (1,0) [0|3] "" Vector__XXX
 SG_ EnableStatus : 8|2@1+ (1,0) [0|3] "" Vector__XXX
 SG_ RqToPermitDEFDosingTestInjection : 4|3@1+ (1,0) [0|7] "" Vector__XXX
 SG_ RqToPermitDEFHydStiffnessCheck : 2|2@1+ (1,0) [0|3] "" Vector__XXX
 SG_ ThermalMnmgtInhReq : 0|2@1+ (1,0) [0|3] "" Vector__XXX

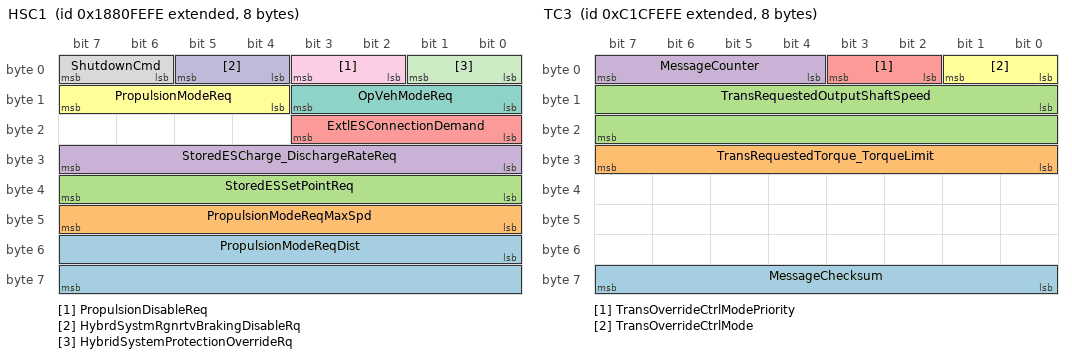
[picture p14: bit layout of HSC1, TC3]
BO_ 2558590718 HSC1: 8 Vector__XXX
 SG_ PropulsionModeReqDist : 48|16@1+ (0.03125,0) [0|2007.96875] "km" Vector__XXX
 SG_ PropulsionModeReqMaxSpd : 40|8@1+ (1,0) [0|250] "km/h" Vector__XXX
 SG_ StoredESSetPointReq : 32|8@1+ (0.4,0) [0|100] "%" Vector__XXX
 SG_ StoredESCharge_DischargeRateReq : 24|8@1+ (0.4,0) [0|100] "%" Vector__XXX
 SG_ ExtlESConnectionDemand : 16|4@1+ (1,0) [0|15] "" Vector__XXX
 SG_ PropulsionModeReq : 12|4@1+ (1,0) [0|15] "" Vector__XXX
 SG_ OpVehModeReq : 8|4@1+ (1,0) [0|15] "" Vector__XXX
 SG_ ShutdownCmd : 6|2@1+ (1,0) [0|3] "" Vector__XXX
 SG_ PropulsionDisableReq : 2|2@1+ (1,0) [0|3] "" Vector__XXX
 SG_ HybrdSystmRgnrtvBrakingDisableRq : 4|2@1+ (1,0) [0|3] "" Vector__XXX
 SG_ HybridSystemProtectionOverrideRq : 0|2@1+ (1,0) [0|3] "" Vector__XXX

BO_ 2350776062 EIC: 8 Vector__XXX
 SG_ EngTimingAdvance : 0|16@1+ (0.0078125,-200) [-200|301.99] "deg" Vector__XXX

BO_ 2350710526 TC3: 8 Vector__XXX
 SG_ MessageChecksum : 56|8@1+ (1,0) [0|255] "" Vector__XXX
 SG_ TransRequestedTorque_TorqueLimit : 24|8@1+ (1,-125) [-125|125] "%" Vector__XXX
 SG_ TransRequestedOutputShaftSpeed : 8|16@1+ (0.25,-8031.75) [-8031.375|8031.375] "rpm" Vector__XXX
 SG_ MessageCounter : 4|4@1+ (1,0) [0|15] "" Vector__XXX
 SG_ TransOverrideCtrlModePriority : 2|2@1+ (1,0) [0|3] "" Vector__XXX
 SG_ TransOverrideCtrlMode : 0|2@1+ (1,0) [0|3] "" Vector__XXX

BO_ 2582642430 PropA2: 8 Vector__XXX
 SG_ ManufacturerSpecificInformation : 0|64@1+ (1,0) [0|0] "" Vector__XXX

BO_ 2566836734 DM09: 8 Vector__XXX

BO_ 2566801918 GBSD: 8 Vector__XXX
 SG_ GroundBasedDirection : 56|2@1+ (1,0) [0|0] "" Vector__XXX
 SG_ GroundBasedImplementDistance : 16|32@1+ (1,0) [0|0] "" Vector__XXX
 SG_ GroundBasedImplementSpeed : 0|16@1+ (1,0) [0|0] "" Vector__XXX

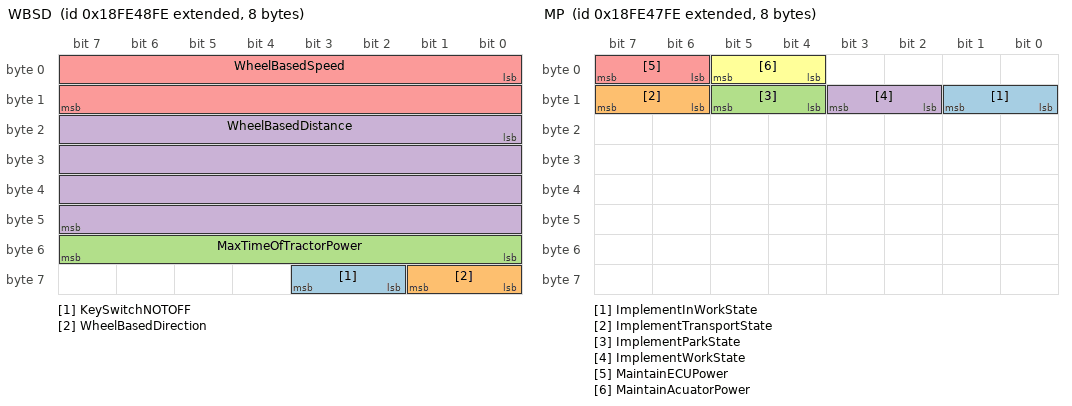
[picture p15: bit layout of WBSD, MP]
BO_ 2566801662 WBSD: 8 Vector__XXX
 SG_ KeySwitchNOTOFF : 58|2@1+ (1,0) [0|0] "" Vector__XXX
 SG_ WheelBasedDirection : 56|2@1+ (1,0) [0|0] "" Vector__XXX
 SG_ MaxTimeOfTractorPower : 48|8@1+ (1,0) [0|0] "" Vector__XXX
 SG_ WheelBasedDistance : 16|32@1+ (1,0) [0|0] "" Vector__XXX
 SG_ WheelBasedSpeed : 0|16@1+ (1,0) [0|0] "" Vector__XXX

BO_ 2566801406 MP: 8 Vector__XXX
 SG_ ImplementInWorkState : 8|2@1+ (1,0) [0|0] "" Vector__XXX
 SG_ ImplementTransportState : 14|2@1+ (1,0) [0|0] "" Vector__XXX
 SG_ ImplementParkState : 12|2@1+ (1,0) [0|0] "" Vector__XXX
 SG_ ImplementWorkState : 10|2@1+ (1,0) [0|0] "" Vector__XXX
 SG_ MaintainECUPower : 6|2@1+ (1,0) [0|0] "" Vector__XXX
 SG_ MaintainAcuatorPower : 4|2@1+ (1,0) [0|0] "" Vector__XXX

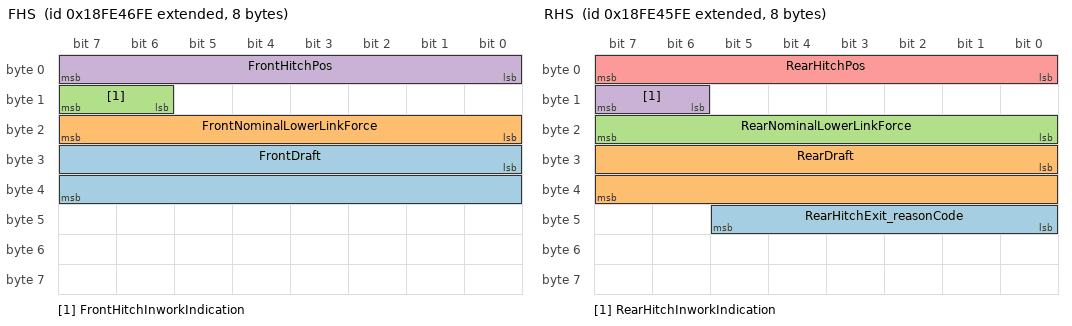
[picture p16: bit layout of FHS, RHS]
BO_ 2566801150 FHS: 8 Vector__XXX
 SG_ FrontDraft : 24|16@1+ (1,0) [0|0] "" Vector__XXX
 SG_ FrontNominalLowerLinkForce : 16|8@1+ (1,0) [0|0] "" Vector__XXX
 SG_ FrontHitchInworkIndication : 14|2@1+ (1,0) [0|0] "" Vector__XXX
 SG_ FrontHitchPos : 0|8@1+ (1,0) [0|0] "" Vector__XXX

BO_ 2566800894 RHS: 8 Vector__XXX
 SG_ RearHitchExit_reasonCode : 40|6@1+ (1,0) [0|0] "" Vector__XXX
 SG_ RearDraft : 24|16@1+ (1,0) [0|0] "" Vector__XXX
 SG_ RearNominalLowerLinkForce : 16|8@1+ (1,0) [0|0] "" Vector__XXX
 SG_ RearHitchInworkIndication : 14|2@1+ (1,0) [0|0] "" Vector__XXX
 SG_ RearHitchPos : 0|8@1+ (1,0) [0|0] "" Vector__XXX

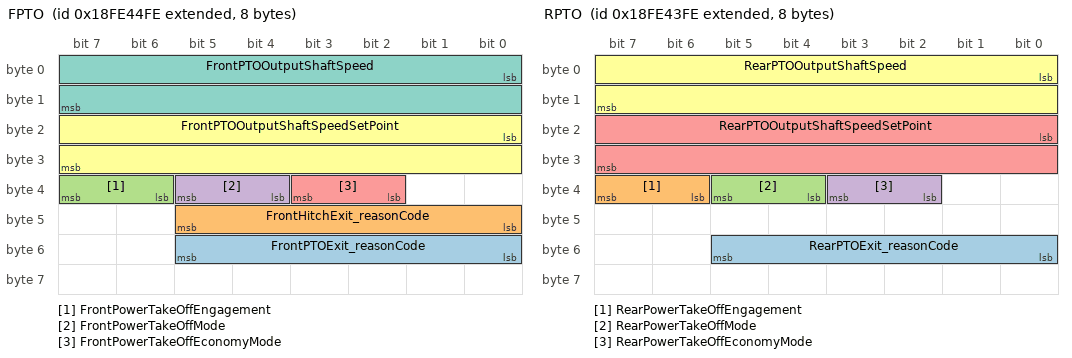
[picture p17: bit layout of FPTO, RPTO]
BO_ 2566800638 FPTO: 8 Vector__XXX
 SG_ FrontPTOExit_reasonCode : 48|6@1+ (1,0) [0|0] "" Vector__XXX
 SG_ FrontHitchExit_reasonCode : 40|6@1+ (1,0) [0|0] "" Vector__XXX
 SG_ FrontPowerTakeOffEngagement : 38|2@1+ (1,0) [0|0] "" Vector__XXX
 SG_ FrontPowerTakeOffMode : 36|2@1+ (1,0) [0|0] "" Vector__XXX
 SG_ FrontPowerTakeOffEconomyMode : 34|2@1+ (1,0) [0|0] "" Vector__XXX
 SG_ FrontPTOOutputShaftSpeedSetPoint : 16|16@1+ (1,0) [0|0] "" Vector__XXX
 SG_ FrontPTOOutputShaftSpeed : 0|16@1+ (1,0) [0|0] "" Vector__XXX

BO_ 2566800382 RPTO: 8 Vector__XXX
 SG_ RearPTOExit_reasonCode : 48|6@1+ (1,0) [0|0] "" Vector__XXX
 SG_ RearPowerTakeOffEngagement : 38|2@1+ (1,0) [0|0] "" Vector__XXX
 SG_ RearPowerTakeOffMode : 36|2@1+ (1,0) [0|0] "" Vector__XXX
 SG_ RearPowerTakeOffEconomyMode : 34|2@1+ (1,0) [0|0] "" Vector__XXX
 SG_ RearPTOOutputShaftSpeedSetPoint : 16|16@1+ (1,0) [0|0] "" Vector__XXX
 SG_ RearPTOOutputShaftSpeed : 0|16@1+ (1,0) [0|0] "" Vector__XXX

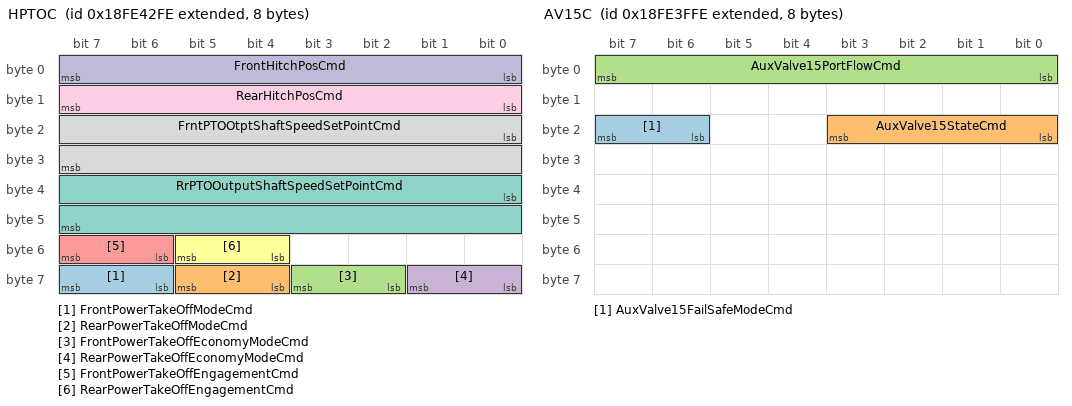
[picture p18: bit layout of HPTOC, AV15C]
BO_ 2566800126 HPTOC: 8 Vector__XXX
 SG_ FrontPowerTakeOffModeCmd : 62|2@1+ (1,0) [0|0] "" Vector__XXX
 SG_ RearPowerTakeOffModeCmd : 60|2@1+ (1,0) [0|0] "" Vector__XXX
 SG_ FrontPowerTakeOffEconomyModeCmd : 58|2@1+ (1,0) [0|0] "" Vector__XXX
 SG_ RearPowerTakeOffEconomyModeCmd : 56|2@1+ (1,0) [0|0] "" Vector__XXX
 SG_ FrontPowerTakeOffEngagementCmd : 54|2@1+ (1,0) [0|0] "" Vector__XXX
 SG_ RearPowerTakeOffEngagementCmd : 52|2@1+ (1,0) [0|0] "" Vector__XXX
 SG_ RrPTOOutputShaftSpeedSetPointCmd : 32|16@1+ (1,0) [0|0] "" Vector__XXX
 SG_ FrntPTOOtptShaftSpeedSetPointCmd : 16|16@1+ (1,0) [0|0] "" Vector__XXX
 SG_ RearHitchPosCmd : 8|8@1+ (1,0) [0|0] "" Vector__XXX
 SG_ FrontHitchPosCmd : 0|8@1+ (1,0) [0|0] "" Vector__XXX

BO_ 2566799358 AV15C: 8 Vector__XXX
 SG_ AuxValve15FailSafeModeCmd : 22|2@1+ (1,0) [0|0] "" Vector__XXX
 SG_ AuxValve15StateCmd : 16|4@1+ (1,0) [0|0] "" Vector__XXX
 SG_ AuxValve15PortFlowCmd : 0|8@1+ (1,0) [0|0] "" Vector__XXX

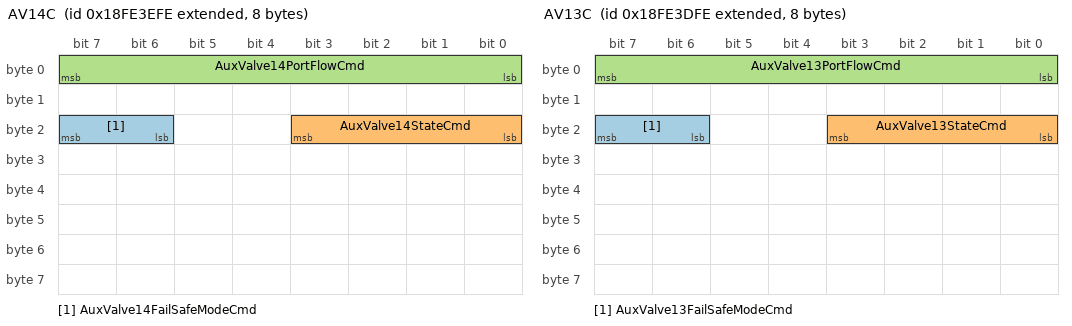
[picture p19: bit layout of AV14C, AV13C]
BO_ 2566799102 AV14C: 8 Vector__XXX
 SG_ AuxValve14FailSafeModeCmd : 22|2@1+ (1,0) [0|0] "" Vector__XXX
 SG_ AuxValve14StateCmd : 16|4@1+ (1,0) [0|0] "" Vector__XXX
 SG_ AuxValve14PortFlowCmd : 0|8@1+ (1,0) [0|0] "" Vector__XXX

BO_ 2566798846 AV13C: 8 Vector__XXX
 SG_ AuxValve13FailSafeModeCmd : 22|2@1+ (1,0) [0|0] "" Vector__XXX
 SG_ AuxValve13StateCmd : 16|4@1+ (1,0) [0|0] "" Vector__XXX
 SG_ AuxValve13PortFlowCmd : 0|8@1+ (1,0) [0|0] "" Vector__XXX

BO_ 2566798590 AV12C: 8 Vector__XXX
 SG_ AuxValve12FailSafeModeCmd : 22|2@1+ (1,0) [0|0] "" Vector__XXX
 SG_ AuxValve12StateCmd : 16|4@1+ (1,0) [0|0] "" Vector__XXX
 SG_ AuxValve12PortFlowCmd : 0|8@1+ (1,0) [0|0] "" Vector__XXX

BO_ 2566798334 AV11C: 8 Vector__XXX
 SG_ AuxValve11FailSafeModeCmd : 22|2@1+ (1,0) [0|0] "" Vector__XXX
 SG_ AuxValve11StateCmd : 16|4@1+ (1,0) [0|0] "" Vector__XXX
 SG_ AuxValve11PortFlowCmd : 0|8@1+ (1,0) [0|0] "" Vector__XXX

BO_ 2566798078 AV10C: 8 Vector__XXX
 SG_ AuxValve10FailSafeModeCmd : 22|2@1+ (1,0) [0|0] "" Vector__XXX
 SG_ AuxValve10StateCmd : 16|4@1+ (1,0) [0|0] "" Vector__XXX
 SG_ AuxValve10PortFlowCmd : 0|8@1+ (1,0) [0|0] "" Vector__XXX

BO_ 2566797822 AV09C: 8 Vector__XXX
 SG_ AuxValve9FailSafeModeCmd : 22|2@1+ (1,0) [0|0] "" Vector__XXX
 SG_ AuxValve9StateCmd : 16|4@1+ (1,0) [0|0] "" Vector__XXX
 SG_ AuxValve9PortFlowCmd : 0|8@1+ (1,0) [0|0] "" Vector__XXX

BO_ 2566797566 AV08C: 8 Vector__XXX
 SG_ AuxValve8FailSafeModeCmd : 22|2@1+ (1,0) [0|0] "" Vector__XXX
 SG_ AuxValve8StateCmd : 16|4@1+ (1,0) [0|0] "" Vector__XXX
 SG_ AuxValve8PortFlowCmd : 0|8@1+ (1,0) [0|0] "" Vector__XXX

CM_ BO_ 2566670334 "Monitored Tire Information
Used by the tire monitoring system to report the number of tires, number of axles and number of tires on each axle it is monitoring on a specific vehicle. The axle number increments from front to rear of the vehicle per ...";
CM_ SG_ 2566670334 Axle12MonitoredTireCount "The number of tires on Axle 12 which are monitored by the tire monitor controller. The axle number increments from front to rear of the vehicle when facing the vehicle in the forward vehicle travel orientation. If the axle is not monitored by the ...";
CM_ SG_ 2566670334 Axle11MonitoredTireCount "The number of tires on Axle 11 which are monitored by the tire monitor controller. The axle number increments from front to rear of the vehicle when facing the vehicle in the forward vehicle travel orientation. If the axle is not monitored by the ...";
CM_ SG_ 2566670334 Axle10MonitoredTireCount "The number of tires on Axle 10 which are monitored by the tire monitor controller. The axle number increments from front to rear of the vehicle when facing the vehicle in the forward vehicle travel orientation. If the axle is not monitored by the ...";
CM_ SG_ 2566670334 Axle9MonitoredTireCount "The number of tires on Axle 9 which are monitored by the tire monitor controller. The axle number increments from front to rear of the vehicle when facing the vehicle in the forward vehicle travel orientation. If the axle is not monitored by the ...";
CM_ SG_ 2566670334 Axle8MonitoredTireCount "The number of tires on Axle 8 which are monitored by the tire monitor controller. The axle number increments from front to rear of the vehicle when facing the vehicle in the forward vehicle travel orientation. If the axle is not monitored by the ...";
CM_ SG_ 2566670334 Axle7MonitoredTireCount "The number of tires on Axle 7 which are monitored by the tire monitor controller. The axle number increments from front to rear of the vehicle when facing the vehicle in the forward vehicle travel orientation. If the axle is not monitored by the ...";
CM_ SG_ 2566670334 Axle6MonitoredTireCount "The number of tires on Axle 6 which are monitored by the tire monitor controller. The axle number increments from front to rear of the vehicle when facing the vehicle in the forward vehicle travel orientation. If the axle is not monitored by the ...";
CM_ SG_ 2566670334 Axle5MonitoredTireCount "The number of tires on Axle 5 which are monitored by the tire monitor controller. The axle number increments from front to rear of the vehicle when facing the vehicle in the forward vehicle travel orientation. If the axle is not monitored by the ...";
CM_ SG_ 2566670334 Axle4MonitoredTireCount "The number of tires on Axle 4 which are monitored by the tire monitor controller. The axle number increments from front to rear of the vehicle when facing the vehicle in the forward vehicle travel orientation. If the axle is not monitored by the ...";
CM_ SG_ 2566670334 Axle3MonitoredTireCount "The number of tires on Axle 3 which are monitored by the tire monitor controller. The axle number increments from front to rear of the vehicle when facing the vehicle in the forward vehicle travel orientation. If the axle is not monitored by the ...";
CM_ SG_ 2566670334 Axle2MonitoredTireCount "The number of tires on Axle 2 which are monitored by the tire monitor controller. The axle number increments from front to rear of the vehicle when facing the vehicle in the forward vehicle travel orientation. If the axle is not monitored by the ...";
CM_ SG_ 2566670334 Axle1MonitoredTireCount "The number of tires on Axle 1 which are monitored by the tire monitor controller. The axle number increments from front to rear of the vehicle when facing the vehicle in the forward vehicle travel orientation. If the axle is not monitored by the ...";
CM_ SG_ 2566670334 NumberOfTiresOnTheVehicle "The total number of tires monitored for tire parameters. A maximum of 250 tires is defined.";
CM_ SG_ 2566670334 NumberOfAxlesOnTheVehicle "The number of axles monitored for tire parameters. A maximum of 12 axles is defined.";
CM_ BO_ 2566670078 "Tire Sensor Identification Status
The tire sensor identification number for each monitored tire.
Since there are multiple tire sensors to report, the message format will be a,b,c,d,b,c,d,b,c,d,b,c,d,...etc. where
a = Number of Tire Sensors
b = ...";
CM_ SG_ 2566670078 TireSensorIdentificationNumber "The identification number of the tire specified in the tire number (SPN 6964) or tire location (SPN 6965).";
CM_ SG_ 2566670078 TireSensorLocation "The location of monitored tire that corresponds with the Tire Sensor Identification Number (SPN 6966). In order to specify the monitored tire by tire number, use the Tire Number SPN 6964.
The high order 4 bits indicate the vehicle axle position of ...";
CM_ SG_ 2566670078 TireSensorTireNumber "The number of the monitored tire that corresponds with the Tire Sensor Identification Number (SPN 6966).  In order to specify the monitored tire by location, use the Tire Location SPN 6965.

The value 0xFF indicates this SPN is not used.";
CM_ SG_ 2566670078 NumberOfTireSensors "Total count of monitored tire sensor identification numbers represented in this instance of the parameter group.";
CM_ BO_ 2566669822 "Tire Wireless Signal Strength Indicator
The tire wireless signal strength indicator for each monitored tire. If there are multiple tire sensors with multiple antennas to report, the message format will be ...";
CM_ SG_ 2566669822 TrWrelessSignalStrengthIndicator "The wireless signal strength between the tire pressure sensor and the specified antenna, for the tire specified in the tire sensor number or tire sensor Location.";
CM_ SG_ 2566669822 TireLocation "The location of monitored tire on the vehicle.
The high order 4 bits indicate the vehicle axle position of the tire sensor, counting front to back on the vehicle, with the value 0 representing the front axle on the vehicle.
The low order 4 bits ...";
CM_ SG_ 2566669822 TireSensorNumber "The number of the monitored tire sensor that corresponds with the tire wireless signal strength indicator. The location of the numbered tire is reported in the tire sensor location SPN (SPN 6965). The value 0xFF indicates this SPN is not used.";
CM_ SG_ 2566669822 TtalNumberOfTireSensorsMonitored "Total number of tire sensors monitored for the specified antenna in this instance of the parameter group.";
CM_ SG_ 2566669822 AntennaNumber "Number of the antenna used to communicate signal strength of a group of sensors.  If a single antenna is used this will default to 0x01. When multiple antennas are used, the first antenna will have a value of 1, 2nd antenna will be 2, 3rd antenna ...";
CM_ SG_ 2566669822 TotalNumberOfAntennasUsed "Total count of antennas used in the specified vehicle system.";
CM_ BO_ 2566669310 "Tire Configuration Status Information
Details the attributes for the tire monitoring configuration status of the tires.
NOTE � Multiple instances of this message will be required to transmit data for all tire locations.  When reporting data for ...";
CM_ SG_ 2566669310 OverTemp "The temperature above which the over temperature alert will trigger.";
CM_ SG_ 2566669310 OverPressPercentageThreshold "The percentage deviation from the set cold inflation pressure, for the over tire pressure alert.";
CM_ SG_ 2566669310 ExtrmUndrPrssPercentageThreshold "The percentage deviation from the set cold inflation pressure, for the extreme under tire pressure alert.";
CM_ SG_ 2566669310 UnderPressPercentageThreshold "The percentage deviation from the set cold inflation pressure, for the under tire pressure alert.";
CM_ SG_ 2566669310 ColdInflationPress "The cold inflation pressure of the tire. Cold inflation pressure is the default/reference inflation pressure suggested by the manufacturer for a specific tire.";
CM_ SG_ 2566669310 TireLocation "The location of monitored tire on the vehicle.
The high order 4 bits indicate the vehicle axle position of the tire sensor, counting front to back on the vehicle, with the value 0 representing the front axle on the vehicle.
The low order 4 bits ...";
CM_ BO_ 2566669054 "Tire Condition Message 2
Tire Condition Message 2
NOTE � Multiple instances of this message will be required to transmit data for all tire locations.  When reporting data for multiple tire locations, each successive message, which provides data ...";
CM_ SG_ 2566669054 RequiredTirePress "The required tire pressure at which air is contained in cavity formed by tire and rim.

This pressure of the tire is compensated to meet the specific physical environmental conditions (temperature) of the vehicle.";
CM_ SG_ 2566669054 TirePress "Pressure at which air is contained in cavity formed by tire and rim. See SPN 241 for alternate tire pressure with a lower range and coarser resolution.";
CM_ SG_ 2566669054 TireLocation "Identifies which tire is associated with the parametric data in PGN 64578. Refer to SPN 929 for further details and examples. The low order 4 bits represent a position number, counting left to right when facing in the direction of normal vehicle ...";
CM_ BO_ 2566668798 "Alternate Fuel 4";
CM_ SG_ 2566668798 EngFl2InjctorMeteringRail1Press2 "The second pressure of fuel 2 measured by first rail pressure sensor in the primary, or first, metering rail as delivered from the supply pump to the injector metering intake.";
CM_ SG_ 2566668798 EngFel2InjectorMeteringRail2Temp "The temperature of fuel 2 measured by first rail temperature sensor in the metering rail 2 as delivered from the supply pump to the injector metering intake.";
CM_ SG_ 2566668798 EngFel2InjectorMeteringRail1Temp "The temperature of fuel 2 measured by first rail temperature sensor in the primary, or first, metering rail as delivered from the supply pump to the injector metering intake.";
CM_ SG_ 2566668798 EngFl2InjectorMeteringRail2Press "The pressure of fuel 2 measured by first rail pressure sensor in the metering rail 2 as delivered from the supply pump to the injector metering intake.";
CM_ SG_ 2566668798 EngFl2InjectorMeteringRail1Press "The pressure of fuel 2 measured by first rail pressure sensor in the primary, or first, metering rail as delivered from the supply pump to the injector metering intake.";
CM_ BO_ 2566668542 "Engine Hydraulic Fuel 2 Pump Status
Hydraulically driven engine fuel 2 pump messages.";
CM_ SG_ 2566668542 EngFuel2PumpHydPress "Hydraulic pressure in the lines of the hydraulically driven fuel 2 pump.";
CM_ SG_ 2566668542 EngFuel2PumpHydDirectionalValve "Position of hydraulic directional valve to control application of hydraulic oil flow.  0% is no flow to the appliance; 100% is full flow to the appliance.";
CM_ SG_ 2566668542 EngFuel2PumpHydSwashPlateAngle "Position of hydraulic swash plate angle within hydraulic pump.  0% represents the lowest possible flow, 100% represents the maximum flow.";
CM_ SG_ 2566668542 EngFuel2PumpHydFlowCtrlValve "Position of hydraulic pump flow control valve opening; 0% = fully closed, 100% = fully open.";
CM_ BO_ 2566668286 "Engine Turbocharger Control 2
This PGN contains information on turbocharger commands.";
CM_ SG_ 2566668286 EngStagedTurboSolenoidStatus "Current state of the staged turbocharger solenoid, normalized to percent, 0% represents not actuated and 100% represents fully actuated.";
CM_ BO_ 2566668030 "Heat Exchanger Debris Purge Information
Contains information about purging debris from the heat exchanger.";
CM_ SG_ 2566668030 HtExchngerDebrisPurgeApproaching "Status signal which indicates that purging the debris from the heat exchanger is imminent.

00     Not approaching
01     Approaching
10     SAE reserved
11     Not available";
CM_ SG_ 2566668030 HeatExchangerDebrisPurgeStatus "Indicates whether the system is currently purging debris from the heat exchanger.

00    Inactive
01    Active
10    SAE reserved
11    Not available";
CM_ BO_ 2566667774 "Engine End Bearing Temperature 1
Used to transmit temperature values at end bearings for connecting rods in the engine cylinder";
CM_ SG_ 2566667774 EngEndBearing8Temp "Temperature of end bearing of the connecting rod for cylinder 8 on the engine";
CM_ SG_ 2566667774 EngEndBearing7Temp "Temperature of end bearing of the connecting rod for cylinder 7 on the engine";
CM_ SG_ 2566667774 EngEndBearing6Temp "Temperature of end bearing of the connecting rod for cylinder 6 on the engine";
CM_ SG_ 2566667774 EngEndBearing5Temp "Temperature of end bearing of the connecting rod for cylinder 5 on the engine";
CM_ SG_ 2566667774 EngEndBearing4Temp "Temperature of end bearing of the connecting rod for cylinder 4 on the engine";
CM_ SG_ 2566667774 EngEndBearing3Temp "Temperature of end bearing of the connecting rod for cylinder 3 on the engine";
CM_ SG_ 2566667774 EngEndBearing2Temp "Temperature of end bearing of the connecting rod for cylinder 2 on the engine";
CM_ SG_ 2566667774 EngEndBearing1Temp "Temperature of end bearing of the connecting rod for cylinder 1 on the engine";
CM_ BO_ 2566667518 "Engine End Bearing Temperature 2
Used to transmit temperature values at end bearings for connecting rods in the engine cylinder";
CM_ SG_ 2566667518 EngEndBearing16Temp "Temperature of end bearing of the connecting rod for cylinder 16 on the engine";
CM_ SG_ 2566667518 EngEndBearing15Temp "Temperature of end bearing of the connecting rod for cylinder 15 on the engine";
CM_ SG_ 2566667518 EngEndBearing14Temp "Temperature of end bearing of the connecting rod for cylinder 14 on the engine";
CM_ SG_ 2566667518 EngEndBearing13Temp "Temperature of end bearing of the connecting rod for cylinder 13 on the engine";
CM_ SG_ 2566667518 EngEndBearing12Temp "Temperature of end bearing of the connecting rod for cylinder 12 on the engine";
CM_ SG_ 2566667518 EngEndBearing11Temp "Temperature of end bearing of the connecting rod for cylinder 11 on the engine";
CM_ SG_ 2566667518 EngEndBearing10Temp "Temperature of end bearing of the connecting rod for cylinder 10 on the engine";
CM_ SG_ 2566667518 EngEndBearing9Temp "Temperature of end bearing of the connecting rod for cylinder 9 on the engine";
CM_ BO_ 2566667262 "Engine End Bearing Temperature 3
Used to transmit temperature values at end bearings for connecting rods in the engine cylinder";
CM_ SG_ 2566667262 EngEndBearing20Temp "Temperature of end bearing of the connecting rod for cylinder 20 on the engine";
CM_ SG_ 2566667262 EngEndBearing19Temp "Temperature of end bearing of the connecting rod for cylinder 19 on the engine";
CM_ SG_ 2566667262 EngEndBearing18Temp "Temperature of end bearing of the connecting rod for cylinder 18 on the engine";
CM_ SG_ 2566667262 EngEndBearing17Temp "Temperature of end bearing of the connecting rod for cylinder 17 on the engine";
CM_ BO_ 2499558142 "Gaseous Fuel Supply Pressure 1
Used to transmit information on pressures at various points of Gaseous fuel supplied to the engine.";
CM_ SG_ 2499558142 GsFlSpplyShtoffValve2IntakePress "Pressure of gaseous fuel supply measured at shutoff valve 2 in gaseous fuel supply unit. Shutoff valves are used to regulate gaseous fuel supply to engine.";
CM_ SG_ 2499558142 GsFlSpplyShtoffValve1IntakePress "Pressure of gaseous fuel supply measured at shutoff valve 1 in gaseous fuel supply unit. Shutoff valves are used to regulate gaseous fuel supply to engine.";
CM_ SG_ 2499558142 GasFuelSupplyUnitIntakePress "Pressure of gaseous fuel supply measured at the intake of gaseous fuel supply unit. Gaseous fuel valve unit contains block and bleed valves to regulate the flow of gaseous fuel from the plant to engine.

Gas Supply Unit Intake Pressure";
CM_ SG_ 2499558142 EngGasFuelSupplyPress2 "Second gage pressure measurement of gaseous fuel supply to fuel metering device. If only one sensor is used for gas supply pressure measurement, use SPN 159 instead.";
CM_ BO_ 2499557886 "Gaseous Fuel Supply Pressure 2
Used to transmit information on pressures at various points of Gaseous fuel supplied to the engine.";
CM_ SG_ 2499557886 PlantInertGasSupplyOutletPress "Pressure of the purge gas supplied to the engine. Inert gas is used to remove gaseous fuel build-up in the engines and in the fuel supply lines when gaseous fuel is not in operation.";
CM_ SG_ 2499557886 PlantGasFuelSupplyOutletPress "Pressure of the gaseous fuel supplied from the plant room for one or more engines.  Based on the application, plant room will contain fuel tank for gas, vaporizer and heater and cooler compartments.";
CM_ BO_ 2499557630 "Engine Oil Mist Detection Information 1
Used to transmit oil mist information determined by the engine monitoring system";
CM_ SG_ 2499557630 EngOilMist8Concentration "Percentage of detected oil mist in compartment 8 compared to the lower explosion limit (LEL). 100% means the measured value is on the lower explosion limit,whereas 0% means no detected oil mist in the air.";
CM_ SG_ 2499557630 EngOilMist7Concentration "Percentage of detected oil mist in compartment 7 compared to the lower explosion limit (LEL). 100% means the measured value is on the lower explosion limit,whereas 0% means no detected oil mist in the air.";
CM_ SG_ 2499557630 EngOilMist6Concentration "Percentage of detected oil mist in compartment 6 compared to the lower explosion limit (LEL). 100% means the measured value is on the lower explosion limit,whereas 0% means no detected oil mist in the air.";
CM_ SG_ 2499557630 EngOilMist5Concentration "Percentage of detected oil mist in compartment 5 compared to the lower explosion limit (LEL). 100% means the measured value is on the lower explosion limit,whereas 0% means no detected oil mist in the air.";
CM_ SG_ 2499557630 EngOilMist4Concentration "Percentage of detected oil mist in compartment 4 compared to the lower explosion limit (LEL). 100% means the measured value is on the lower explosion limit,whereas 0% means no detected oil mist in the air.";
CM_ SG_ 2499557630 EngOilMist3Concentration "Percentage of detected oil mist in compartment 3 compared to the lower explosion limit (LEL). 100% means the measured value is on the lower explosion limit,whereas 0% means no detected oil mist in the air.";
CM_ SG_ 2499557630 EngOilMist2Concentration "Percentage of detected oil mist in compartment 2 compared to the lower explosion limit (LEL). 100% means the measured value is on the lower explosion limit,whereas 0% means no detected oil mist in the air.";
CM_ SG_ 2499557630 EngOilMist1Concentration "Percentage of detected oil mist in compartment 1 compared to the lower explosion limit (LEL). 100% means the measured value is on the lower explosion limit, whereas 0% means no detected oil mist in the air. This measurement is typically taken in ...";
CM_ BO_ 2499557374 "Engine Oil Mist Detection Information 2
Used to transmit oil mist information determined by the engine monitoring system";
CM_ SG_ 2499557374 EngOilMist10Concentration "Percentage of detected oil mist in compartment 10 compared to the lower explosion limit (LEL). 100% means the measured value is on the lower explosion limit,whereas 0% means no detected oil mist in the air.";
CM_ SG_ 2499557374 EngOilMist9Concentration "Percentage of detected oil mist in compartment 9 compared to the lower explosion limit (LEL). 100% means the measured value is on the lower explosion limit,whereas 0% means no detected oil mist in the air.";
CM_ BO_ 2499557118 "Gaseous Fuel Supply Valve Information
Used to transmit information on valves on the gaseous fuel supply lines.";
CM_ SG_ 2499557118 InertGasSupplyValvePos "Position of inert gas supply valve used to control the flow of inert gas into the engine to purge the system.

0% represents valve fully closed and 100% represents valve fully open.";
CM_ SG_ 2499557118 GasFuelSupplyBleedValve3Pos "Position of bleed valve 3, which is used to control the flow of gaseous fuel through the fuel supply unit. 0% represents valve fully closed and 100% represents valve fully open.";
CM_ SG_ 2499557118 GasFuelSupplyBleedValve2Pos "Position of bleed valve 2, which is used to control the flow of gaseous fuel through the fuel supply unit. 0% represents valve fully closed and 100% represents valve fully open.";
CM_ SG_ 2499557118 GasFuelSupplyBleedValve1Pos "Position of bleed valve 1, which is used to control the flow of gaseous fuel through the fuel supply unit. 0% represents valve fully closed and 100% represents valve fully open.";
CM_ SG_ 2499557118 GasFuelSupplyShutoffValve2Pos "Position of shutoff valve 2, which is used to control the flow of gaseous fuel through the fuel supply unit. 0% represents valve fully closed and 100% represents valve fully open.";
CM_ SG_ 2499557118 GasFuelSupplyShutoffValve1Pos "Position of shutoff valve 1, which is used to control the flow of gaseous fuel through the fuel supply unit. 0% represents valve fully closed and 100% represents valve fully open.";
CM_ BO_ 2566665726 "Aftertreatment 2 Diesel Exhaust Fluid Pump 1 Information
Contains information on diesel exhaust fluid pumps for aftertreatment system 2.";
CM_ SG_ 2566665726 TwoMotorSpd "Rotational speed of the motor driving the second pump for the diesel exhaust fluid used in aftertreatment system 2 (exhaust bank 2).";
CM_ SG_ 2566665726 Htr "Percentage of heating applied to the aftertreatment 2 diesel exhaust fluid pump heater.  A value of 0% means no heating applied, a value of 100% means full heating applied. The diesel exhaust fluid pump heater warms the diesel exhaust fluid in the ...";
CM_ BO_ 2499556606 "Engine Fuel Injector Metering Rail Pressure Information 2
Transmits the rail pressure information as measured by different rail pressure sensors.";
CM_ SG_ 2499556606 EngInjectorMeteringRail2Press2 "The pressure of fuel measured by second rail pressure sensor in the metering rail 2 as delivered from the supply pump to the injector metering intake.";
CM_ SG_ 2499556606 EngInjectorMeteringRail2Press1 "The pressure of fuel measured by first rail pressure sensor in the metering rail 2 as delivered from the supply pump to the injector metering intake.";
CM_ SG_ 2499556606 EngInjectorMeteringRail1Press2 "The pressure of fuel measured by the second rail pressure sensor in the primary, or first, metering rail as delivered from the supply pump to the injector metering intake.";
CM_ SG_ 2499556606 EngInjectorMeteringRail1Press1 "The pressure of fuel measured by first rail pressure sensor in the primary, or first, metering rail as delivered from the supply pump to the injector metering intake.";
CM_ BO_ 2499556350 "Engine Fuel Injector Metering Rail Pressure Information 3
Transmits rail pressure information.";
CM_ SG_ 2499556350 EngInjctrMtringRail2DesiredPress "The desired pressure of fuel in metering rail 2 as delivered from the supply pump to the injector metering intake.";
CM_ SG_ 2499556350 EngInjctrMtringRail1DesiredPress "The desired pressure of fuel in the primary, or first, metering rail as delivered from the supply pump to the injector metering intake.";
CM_ BO_ 2499556094 "Aftertreatment 1 Particulate Sensor Information 3
This message contains information for the particulate sensor in bank 1 of a 2 bank system or the particulate sensor in a single bank system.";
CM_ SG_ 2499556094 HtrPwrSupplyDiagStatus "The value of this parameter is not retained when power is removed from the particulate sensor.
000 - Tests monitored continuously. There are no enable or pause conditions. See Aftertreatment 1 Particulate Sensor Heater Power Supply Preliminary FMI ...";
CM_ SG_ 2499556094 HtrPwrSupplyPreliminaryFMI "Used to identify the applicable J1939-73 FMI detected in the aftertreatment particulate sensor heater power supply by the manufacturer뭩 sensor control software in exhaust bank 1.  In the case of multiple failures the most severe is communicated.
A ...";
CM_ SG_ 2499556094 PwrSupplyDiagStatus "The value of this parameter is not retained when power is removed from the particulate sensor.
000 - Tests monitored continuously. There are no enable or pause conditions. See Aftertreatment 1 Particulate Sensor Power Supply Preliminary FMI (SPN ...";
CM_ SG_ 2499556094 PwrSupplyPreliminaryFMI "Used to identify the applicable J1939-73 FMI detected in the aftertreatment particulate sensor power supply by the manufacturer뭩 sensor control software in exhaust bank 1. In the case of multiple failures the most severe is communicated.
A value ...";
CM_ SG_ 2499556094 InputDiagStatus "The value of this parameter is not retained when power is removed from the particulate sensor.
000 - Tests monitored continuously. There are no enable or pause conditions. See Aftertreatment 1 Particulate Sensor Input Preliminary FMI (SPN 7325) for ...";
CM_ SG_ 2499556094 InputPreliminaryFMI "Used to identify the applicable J1939-73 FMI detected in the aftertreatment particulate sensor input by the manufacturer뭩 sensor control software in exhaust bank 1. In the case of multiple failures the most severe is communicated.
A value of 31 is ...";
CM_ SG_ 2499556094 HtrLowSideDriverDiagStatus "The value of this parameter is not retained when power is removed from the particulate sensor.
000 - Tests monitored continuously. There are no enable or pause conditions. See Aftertreatment 1 Particulate Sensor Heater Low Side Driver Preliminary ...";
CM_ SG_ 2499556094 HtrLowSideDriverPreliminaryFMI "Used to identify the applicable J1939-73 FMI detected in the aftertreatment particulate sensor heater high side driver by the manufacturer뭩 sensor control software in exhaust bank 1. In the case of multiple failures the most severe is communicated.
 ...";
CM_ SG_ 2499556094 HtrHiSideDriverDiagStatus "The value of this parameter is not retained when power is removed from the particulate sensor.
000 - Tests monitored continuously. There are no enable or pause conditions. See Aftertreatment 1 Particulate Sensor Heater High Side Driver Preliminary ...";
CM_ SG_ 2499556094 HtrHiSideDriverPreliminaryFMI "Used to identify the applicable J1939-73 FMI detected in the aftertreatment particulate sensor heater high side driver by the manufacturer뭩 sensor control software in exhaust bank 1. In the case of multiple failures the most severe is communicated.
 ...";
CM_ BO_ 2566664702 "Aftertreatment System Information 1
The state of the aftertreatment system.";
CM_ SG_ 2566664702 DEFDosingModeStatus "Indicates that the aftertreatment system is dosing in standard or reduced mode.
Standard indicates that the system will dose at maximum capacity where the reduced mode will dose at minimum capacity  (e.g., IMO 3 to IMO 2 in Marine Applications).
 ...";
CM_ SG_ 2566664702 DEFQualityMalfunctionEPActive "This parameter is used to notify the operator that a DEF Quality and DEF Level evaluation period, also known as a judgement period, is currently active.
The judgement period is required by the Japanese Ministry of Land, Interior, and Transport ...";
CM_ SG_ 2566664702 DEFTankTemp "The derived diesel exhaust fluid tank temperature in applications with multiple temperature sensors in a single tank. The SPN data will be derived from all temperature sensors in the tank.
Note: This SPN can be derived from any of the ...";
CM_ SG_ 2566664702 DEFTankVolume "The derived diesel exhaust fluid tank volume in applications with multiple level sensors in a single tank. The SPN data will be derived from all level sensors in the tank.
Note: This SPN can be derived from any of the aftertreatment tank level ...";
CM_ SG_ 2566664702 DEFHtrCircuitBreaker "The status of the circuit breaker that is used to heat the diesel exhaust fluid.

00 off
01 on
10 error
11 not available";
CM_ SG_ 2566664702 AAT "Temperature of ambient air near the aftertreatment components such as DEF tank and DEF lines.";
CM_ SG_ 2566664702 EngLoadReq "Indicates whether the aftertreatment desires engine load to be applied. This is meant to notify the operator that the aftertreatment is requesting engine load for thermal purposes.
The operator is expected to add load to the engine to satisfy this ...";
CM_ SG_ 2566664702 EngSpdIncreaseReq "Indicates whether the aftertreatment desires engine speed control in order to increase the engine speed. This is meant to notify the operator that the aftertreatment is requesting an increase in engine speed for thermal purposes.
The operator is ...";
CM_ SG_ 2566664702 ActiveRegenInhibitedDueToLowEP "The state of aftertreatment active regeneration inhibition due to low exhaust pressure.
Aftertreatment Regeneration is a process of increasing the temperature at the exhaust and thereby removing the deposits on aftertreatment components such as DPF ...";
CM_ SG_ 2566664702 ThermalMnmgtStatus "Indicates whether Aftertreatment Thermal Management process is active.
Aftertreatment Thermal Management indicates that the exhaust temperatures have been controlled for the normal functioning of the aftertreatment system - This is not just limited ...";
CM_ BO_ 2633773310 "SCR Operator Inducement Information 4
Contains parameters that are related to SCR inducement.";
CM_ SG_ 2633773310 SCROprtrIndcmntOvrrdTmeRemaining "Used to indicate the time remaining during an operator inducement override event.  When an operator inducement is active this parameter indicates the remaining time that the currently active operator inducement may be overridden.
See also SPN 6878 ...";
CM_ SG_ 2633773310 SCROprtrIndcmntOvrrdRnwlRequired "Indicates the required operator inducement override renewal state.

00 = Not Required
01 = Required
10 = Error
11 = Not Available";
CM_ SG_ 2633773310 SCROpratorInducementOverrideMode "Indicates the functional mode of SCR operator inducement override.
000          Not Available
001          Available - Not Active
010          Active
011          Active Extended
100          Expired
101-110  Not Defined
111          Not ...";
CM_ SG_ 2633773310 SCROprtrIndcmntEmrgncyOvrrdTtlRs "The total number of times the feature, which allows the operator to override the inducement strategies (as described in SPN 6880) during emergencies, such as hurricanes, has been reset.

This counter can not be reset.";
CM_ BO_ 2633773054 "Fire Suppression Agent Status
Represents the status of various agents used for fire
suppression and solutions.";
CM_ SG_ 2633773054 FrSpprssnCmprssdArFmSystmArPress "Compressed Air Foam System (CAFS) air compressor pressure.";
CM_ SG_ 2633773054 FrSuppressionClassBFoamTankLevel "Liquid level of the Class-B foam agent tank.";
CM_ SG_ 2633773054 FrSuppressionClassAFoamTankLevel "Liquid level of the Class-A foam agent tank.";
CM_ SG_ 2633773054 FireSuppressionWaterTankLevel "Liquid level of the fire apparatus water tank.";
CM_ BO_ 2566663934 "Engine Turbocharger Control 3
Contains command signals to Turbocharger Compressor Blowoff, Wastegate, Cylinder Head Bypass
and Throttle Valve actuators.";
CM_ SG_ 2566663934 WastegateAct2MotorCurDis "Command to disable power to motor in wastegate actuator 2 to prevent unnecessary load on the component.

00 - Do Not Disable
01 - Disable
10 - Reserved
11 - Don't Care/Take No Action";
CM_ SG_ 2566663934 CompressorBypassAct2MotorCurDis "Command to disable power to motor in bypass actuator 2 to prevent unnecessary load on the component.

00 - Do Not Disable
01 - Disable
10 - Reserved
11 - Don't Care/Take No Action";
CM_ SG_ 2566663934 CompressorBypassAct1MotorCurDis "Command to disable power to motor in bypass actuator 1 to prevent unnecessary load on the component.

00 - Do Not Disable
01 - Disable
10 - Reserved
11 - Don't Care/Take No Action";
CM_ SG_ 2566663934 EngThrttlVlv1MotorCurrentDisable "Command to disable power to motor in the actuator to prevent unnecessary load on the component.

00 - Do Not Disable
01 - Disable
10 - Reserved
11 - Don't Care/Take No Action";
CM_ SG_ 2566663934 EngCylHdBypssActtr1MtrCrrntDsble "Command to disable power to motor in the actuator to prevent unnecessary load on the component.

00 - Do Not Disable
01 - Disable
10 - Reserved
11 - Don't Care/Take No Action";
CM_ SG_ 2566663934 EngTrbWstgtActtr1MtrCrrntDisable "Command to disable power to motor in the actuator to prevent unnecessary load on the component.

00 - Do Not Disable
01 - Disable
10 - Reserved
11 - Don't Care/Take No Action";
CM_ SG_ 2566663934 EngTrbCmprssrBlwffActtr1MtrCrrnt "Command to disable power to motor in the actuator to prevent unnecessary load on the component.

00 - Do Not Disable
01 - Disable
10 - Reserved
11 - Don't Care/Take No Action";
CM_ BO_ 2566663678 "Alternate Fuel 5
Information on alternate fuel.";
CM_ SG_ 2566663678 EngFl2InjectorMeteringRail1Temp2 "The second temperature of fuel 2 measured by first rail temperature sensor in the primary, or first, metering rail as delivered from the supply pump to the injector metering intake.";
CM_ SG_ 2566663678 LNGTank2VaporPress "Gage pressure of the vapor in the second tank in a multi-tank system.";
CM_ SG_ 2566663678 LNGTank1VaporPress "Gage pressure of the vapor in the first tank in a multi-tank system (or unique tank if single-tank system).";
CM_ BO_ 2566663422 "Brake Caliper Lining Clearance
Refers to disc brake caliper lining clearance condition.";
CM_ SG_ 2566663422 TrlrBrkClprLnngClranceAxle5Right "Brake caliper lining clearance for right brake on trailer axle 5.

00 - Caliper lining clearance is adequate
01 - Caliper lining clearance is low
10 - Error
11 - Not available / not applicable";
CM_ SG_ 2566663422 TrlrBrkClprLnngClaranceAxle5Left "Brake caliper lining clearance for left brake on trailer axle 5.

00 - Caliper lining clearance is adequate
01 - Caliper lining clearance is low
10 - Error
11 - Not available / not applicable";
CM_ SG_ 2566663422 TrlrBrkClprLnngClranceAxle4Right "Brake caliper lining clearance for right brake on trailer axle 4.

00 - Caliper lining clearance is adequate
01 - Caliper lining clearance is low
10 - Error
11 - Not available / not applicable";
CM_ SG_ 2566663422 TrlrBrkClprLnngClaranceAxle4Left "Brake caliper lining clearance for left brake on trailer axle 4.

00 - Caliper lining clearance is adequate
01 - Caliper lining clearance is low
10 - Error
11 - Not available / not applicable";
CM_ SG_ 2566663422 TrlrBrkClprLnngClranceAxle3Right "Brake caliper lining clearance for right brake on trailer axle 3.

00 - Caliper lining clearance is adequate
01 - Caliper lining clearance is low
10 - Error
11 - Not available / not applicable";
CM_ SG_ 2566663422 TrlrBrkClprLnngClaranceAxle3Left "Brake caliper lining clearance for left brake on trailer axle 3.

00 - Caliper lining clearance is adequate
01 - Caliper lining clearance is low
10 - Error
11 - Not available / not applicable";
CM_ SG_ 2566663422 TrlrBrkClprLnngClranceAxle2Right "Brake caliper lining clearance for right brake on trailer axle 2.

00 - Caliper lining clearance is adequate
01 - Caliper lining clearance is low
10 - Error
11 - Not available / not applicable";
CM_ SG_ 2566663422 TrlrBrkClprLnngClaranceAxle2Left "Brake caliper lining clearance for left brake on trailer axle 2.

00 - Caliper lining clearance is adequate
01 - Caliper lining clearance is low
10 - Error
11 - Not available / not applicable";
CM_ SG_ 2566663422 TrlrBrkClprLnngClranceAxle1Right "Brake caliper lining clearance for right brake on trailer axle 1.

00 - Caliper lining clearance is adequate
01 - Caliper lining clearance is low
10 - Error
11 - Not available / not applicable";
CM_ SG_ 2566663422 TrlrBrkClprLnngClaranceAxle1Left "Brake caliper lining clearance for left brake on trailer axle 1.

00 - Caliper lining clearance is adequate
01 - Caliper lining clearance is low
10 - Error
11 - Not available / not applicable";
CM_ SG_ 2566663422 TrctrBrkClprLnngClrnceAxle5Right "Brake caliper lining clearance for right brake on tractor axle 5.

00 - Caliper lining clearance is adequate
01 - Caliper lining clearance is low
10 - Error
11 - Not available / not applicable";
CM_ SG_ 2566663422 TrctrBrkClprLnngClranceAxle5Left "Brake caliper lining clearance for left brake on tractor axle 5.

00 - Caliper lining clearance is adequate
01 - Caliper lining clearance is low
10 - Error
11 - Not available / not applicable";
CM_ SG_ 2566663422 TrctrBrkClprLnngClrnceAxle4Right "Brake caliper lining clearance for right brake on tractor axle 4.

00 - Caliper lining clearance is adequate
01 - Caliper lining clearance is low
10 - Error
11 - Not available / not applicable";
CM_ SG_ 2566663422 TrctrBrkClprLnngClranceAxle4Left "Brake caliper lining clearance for left brake on tractor axle 4.

00 - Caliper lining clearance is adequate
01 - Caliper lining clearance is low
10 - Error
11 - Not available / not applicable";
CM_ SG_ 2566663422 TrctrBrkClprLnngClrnceAxle3Right "Brake caliper lining clearance for right brake on tractor axle 3.

00 - Caliper lining clearance is adequate
01 - Caliper lining clearance is low
10 - Error
11 - Not available / not applicable";
CM_ SG_ 2566663422 TrctrBrkClprLnngClranceAxle3Left "Brake caliper lining clearance for left brake on tractor axle 3.

00 - Caliper lining clearance is adequate
01 - Caliper lining clearance is low
10 - Error
11 - Not available / not applicable";
CM_ SG_ 2566663422 TrctrBrkClprLnngClrnceAxle2Right "Brake caliper lining clearance for right brake on tractor axle 2.

00 - Caliper lining clearance is adequate
01 - Caliper lining clearance is low
10 - Error
11 - Not available / not applicable";
CM_ SG_ 2566663422 TrctrBrkClprLnngClranceAxle2Left "Brake caliper lining clearance for left brake on tractor axle 2.

00 - Caliper lining clearance is adequate
01 - Caliper lining clearance is low
10 - Error
11 - Not available / not applicable";
CM_ SG_ 2566663422 TrctrBrkClprLnngClrnceAxle1Right "Brake caliper lining clearance for right brake on tractor axle 1.

00 - Caliper lining clearance is adequate
01 - Caliper lining clearance is low
10 - Error
11 - Not available / not applicable";
CM_ SG_ 2566663422 TrctrBrkClprLnngClranceAxle1Left "Brake caliper lining clearance for left brake on tractor axle 1.

00 - Caliper lining clearance is adequate
01 - Caliper lining clearance is low
10 - Error
11 - Not available / not applicable";
CM_ BO_ 2566663166 "Cruise Control / Vehicle Speed 4
Cruise Control / Vehicle Speed 4";
CM_ SG_ 2566663166 EngExtlIdleReqFeedback "Indicates that the engine is altering the idle speed due to a request from an external source. 

00 - No Idle Alteration Active - standard idle speed
01 - Idle Alteration Active
10 - Error
11 - Not available";
CM_ SG_ 2566663166 CruiseCtrlAdjustedMaxSpeed "Present maximum vehicle velocity at which cruise can be set. This parameter is expected to change during run-time due to functionality that could influence the behavior of the cruise control algorithm. This functionality may include, but is not ...";
CM_ SG_ 2566663166 AppliedVehicleSpeedLimit "The vehicle speed limit in effect.

See SPN 2595 for alternate resolution.

Note:  If a maximum vehicle speed limit is not selected, then the first byte of this parameter will be equal to 0xFB.";
CM_ BO_ 2566662910 "Operator Inducement Information
Contains parameters related to operator inducement.";
CM_ SG_ 2566662910 TimeToFinalIndAction "Indicates the time until the inducement strategy enforces the final level of engine emissions operator inducement. The final level of inducement can include derating the engine, shutting down the engine, or restricting the engine to low idle.
When ...";
CM_ SG_ 2566662910 OprtrIndcmntTmTTrqueDerateLevel2 "This parameter provides the time until Operator Inducement Torque Derate Level 2 (SPN 7427) is activated.
When operator inducement is not active or if a second level of derate does not exist, then this parameter will be set to 0xFB00. For systems ...";
CM_ SG_ 2566662910 OprtrIndcementTorqueDerateLevel2 "This is the second torque derate that will be applied to the engine operation due to operator inducement. The torque derate level indicated in this parameter will be applied when the value in Operator Inducement Time to Torque Derate Level 2 (SPN ...";
CM_ SG_ 2566662910 OprtrIndcmntTmTTrqueDerateLevel1 "This parameter provides the time until Operator Inducement Torque Derate Level 1 (SPN 7425) is activated.
When operator inducement is not active, this parameter will be set to 0xFB00. For systems where SPN 5246 or SPN 5826 are supported, operator ...";
CM_ SG_ 2566662910 OprtrIndcementTorqueDerateLevel1 "This is the first torque derate that will be applied to the engine operation due to operator inducement.  The torque derate indicated in this parameter will be active when the value in Operator Inducement Time to Torque Derate Level 1 (SPN 7426) has ...";
CM_ BO_ 2566662654 "Forward Lane Image 3
Forward Lane Image message 3 for computing results outside the optical sensor (e.g., data fusion)";
CM_ SG_ 2566662654 LeftLaneMarkerType "Indicates the type of lane marker detected by the Forward Lane Imager on the left side.
0000 -  Processing or not identified
0001 -  Solid
0010 -  Road edge
0011 -  Dashed
0100 -  Double lane marker
0101 -  Raised lane marker (e.g. Bott's ...";
CM_ SG_ 2566662654 RightLaneMarkerType "Indicates the type of lane marker detected by the Forward Lane Imager on the right side.
0000 -  Processing or not identified
0001 -  Solid
0010 -  Road edge
0011 -  Dashed
0100 -  Double lane marker
0101 -  Raised lane marker (e.g. Bott's ...";
CM_ SG_ 2566662654 LaneMarkQualityOnTheRightSide "The quality of the nearest lane mark on the right side of the vehicle.
000 = no lane marks detected
001 = low reliablity of detected lane marks
010 = good reliablity of detected lane marks
011 = perfect recognition of lane marks
100 - 101 = ...";
CM_ SG_ 2566662654 LaneMarkQualityOnTheLeftSide "The quality of the nearest lane mark on the left side of the vehicle.
000 = no lane marks detected
001 = low reliablity of detected lane marks
010 = good reliablity of detected lane marks
011 = perfect recognition of lane marks
100 - 101 = ...";
CM_ SG_ 2566662654 LaneDepartureAngleRight "Angle between right lane mark and vehicle driving direction. The angle is positive while vehicle is moving towards the lane marks, and negative if not. Measured values outside the limits are represented by signal value 251.
Parameter specific ...";
CM_ SG_ 2566662654 LaneDepartureAngleLeft "Angle between left lane mark and vehicle driving direction. The angle is positive while vehicle is moving towards the lane marks, and negative if not. Measured values outside the limits are represented by signal value 251.
Parameter specific values ...";
CM_ SG_ 2566662654 RoadCurvatureBasedOnLaneMarks "The road curvature parameter is based on lane marks as measured by the FLI.  It is the mean value of the road curvature of the lane marks on the left and right side of the lane. In case one of the lane mark is not recognized anymore, the value is ...";
CM_ SG_ 2566662654 RghtDstncTLnMrkFrmVehiclesMiddle "Distance between middle of the vehicle front and the inner/left edge of the nearest lane mark on the right side as measured from the Forward Lane Imager. The value represents the lane width at camera position. Measured values greater than 5 m ...";
CM_ SG_ 2566662654 LftDstncTLnMrkFromVehiclesMiddle "Distance between middle of the vehicle front and the inner/right edge of the nearest lane mark on the left side as measured from the Forward Lane Imager. The value represents the lane width at camera position. Measured values greater than 5 m ...";
CM_ BO_ 2566662142 "Aftertreatment 1 Diesel Exhaust Fluid Information 2
Sensor Information which measures temperature, concentration, and conductivity of the diesel exhaust fluid of the aftertreatment 1 system.";
CM_ SG_ 2566662142 Ctrl2Temp "Temperature of the diesel exhaust fluid at the aftertreatment 1 diesel exhaust fluid controller 2.";
CM_ SG_ 2566662142 Ctrl1Temp "Temperature of the diesel exhaust fluid at the aftertreatment 1 diesel exhaust fluid controller.
For controllers that have more exhaust emissions control functions than only diesel exhaust fluid control, see SPN 5486 - exhaust emission control ECU ...";
CM_ BO_ 2566661630 "Aftertreatment 1 Diesel Exhaust Fluid Tank 1 Information 2
Contains information on various tank levels";
CM_ SG_ 2566661630 Htr2 "Percentage of heating applied to the second diesel exhaust fluid tank heater on aftertreatment 1. A value of 0% means no heating applied, a value of 100% means full heating applied. The diesel exhaust fluid tank heater warms the diesel exhaust fluid ...";
CM_ SG_ 2566661630 Temp2 "The second temperature of aftertreatment 1 diesel exhaust fluid in the storage tank.";
CM_ SG_ 2566661630 Volume2 "Second measurement of the ratio of volume of diesel exhaust fluid to the total volume of the diesel exhaust fluid storage container for aftertreatment system 1 (exhaust bank 1).  0% is empty and 100% is full.  See SPN 1761 and SPN 3517 for alternate ...";
CM_ BO_ 2566661374 "Aftertreatment 2 Diesel Exhaust Fluid Tank 1 Information 2
This message contains diesel exhaust fluid tank 1 information for aftertreatment system 2 (or bank 2).  The first tank for the aftertreatment sytem is primary reagent storage tank.";
CM_ SG_ 2566661374 Htr2 "Percentage of heating applied to the second diesel exhaust fluid tank heater on aftertreatment 2. A value of 0% means no heating applied, a value of 100% means full heating applied. The diesel exhaust fluid tank heater warms the diesel exhaust fluid ...";
CM_ SG_ 2566661374 Temp2 "The second temperature of aftertreatment 2 diesel exhaust fluid in the storage tank.";
CM_ SG_ 2566661374 Volume2 "Second measurement of the ratio of volume of diesel exhaust fluid to the total volume of the diesel exhaust fluid storage container for aftertreatment system 2 (exhaust bank 2).  0% is empty and 100% is full.  See SPN 4426 and SPN 4428 for alternate ...";
CM_ BO_ 2364598270 "Engine Ignition Timing Offset 3
This PGN contains timing offsets for cylinders 17-24.

These timing offsets are relative to the commanded engine timing advance (SPN 7355).";
CM_ SG_ 2364598270 EngCyl24TimingOffset "The ignition timing offset for Cylinder 24 from the engine timing advance (SPN 7355) as a command to the ignition control module. Positive values command an increasingly advanced timing.";
CM_ SG_ 2364598270 EngCyl23TimingOffset "The ignition timing offset for Cylinder 23 from the engine timing advance (SPN 7355) as a command to the ignition control module. Positive values command an increasingly advanced timing.";
CM_ SG_ 2364598270 EngCyl22TimingOffset "The ignition timing offset for Cylinder 22 from the engine timing advance (SPN 7355) as a command to the ignition control module. Positive values command an increasingly advanced timing.";
CM_ SG_ 2364598270 EngCyl21TimingOffset "The ignition timing offset for Cylinder 21 from the engine timing advance (SPN 7355) as a command to the ignition control module. Positive values command an increasingly advanced timing.";
CM_ SG_ 2364598270 EngCyl20TimingOffset "The ignition timing offset for Cylinder 20 from the engine timing advance (SPN 7355) as a command to the ignition control module. Positive values command an increasingly advanced timing.";
CM_ SG_ 2364598270 EngCyl19TimingOffset "The ignition timing offset for Cylinder 19 from the engine timing advance (SPN 7355) as a command to the ignition control module. Positive values command an increasingly advanced timing.";
CM_ SG_ 2364598270 EngCyl18TimingOffset "The ignition timing offset for Cylinder 18 from the engine timing advance (SPN 7355) as a command to the ignition control module. Positive values command an increasingly advanced timing.";
CM_ SG_ 2364598270 EngCyl17TimingOffset "The ignition timing offset for Cylinder 17 from the engine timing advance (SPN 7355) as a command to the ignition control module. Positive values command an increasingly advanced timing.";
CM_ BO_ 2364598014 "Engine Ignition Timing Offset 2
This PGN contains timing offsets for cylinders 9-16.

These timing offsets are relative to the commanded engine timing advance (SPN 7355).";
CM_ SG_ 2364598014 EngCyl16TimingOffset "The ignition timing offset for Cylinder 16 from the engine timing advance (SPN 7355) as a command to the ignition control module. Positive values command an increasingly advanced timing.";
CM_ SG_ 2364598014 EngCyl15TimingOffset "The ignition timing offset for Cylinder 15 from the engine timing advance (SPN 7355) as a command to the ignition control module. Positive values command an increasingly advanced timing.";
CM_ SG_ 2364598014 EngCyl14TimingOffset "The ignition timing offset for Cylinder 14 from the engine timing advance (SPN 7355) as a command to the ignition control module. Positive values command an increasingly advanced timing.";
CM_ SG_ 2364598014 EngCyl13TimingOffset "The ignition timing offset for Cylinder 13 from the engine timing advance (SPN 7355) as a command to the ignition control module. Positive values command an increasingly advanced timing.";
CM_ SG_ 2364598014 EngCyl12TimingOffset "The ignition timing offset for Cylinder 12 from the engine timing advance (SPN 7355) as a command to the ignition control module. Positive values command an increasingly advanced timing.";
CM_ SG_ 2364598014 EngCyl11TimingOffset "The ignition timing offset for Cylinder 11 from the engine timing advance (SPN 7355) as a command to the ignition control module. Positive values command an increasingly advanced timing.";
CM_ SG_ 2364598014 EngCyl10TimingOffset "The ignition timing offset for Cylinder 10 from the engine timing advance (SPN 7355) as a command to the ignition control module. Positive values command an increasingly advanced timing.";
CM_ SG_ 2364598014 EngCyl9TimingOffset "The ignition timing offset for Cylinder 9 from the engine timing advance (SPN 7355) as a command to the ignition control module. Positive values command an increasingly advanced timing.";
CM_ BO_ 2364597758 "Engine Ignition Timing Offset 1
This PGN contains timing offsets for cylinders 1-8.

These timing offsets are relative to the commanded engine timing advance (SPN 7355).";
CM_ SG_ 2364597758 EngCyl8TimingOffset "The ignition timing offset for Cylinder 8 from the engine timing advance (SPN 7355) as a command to the ignition control module. Positive values command an increasingly advanced timing.";
CM_ SG_ 2364597758 EngCyl7TimingOffset "The ignition timing offset for Cylinder 7 from the engine timing advance (SPN 7355) as a command to the ignition control module. Positive values command an increasingly advanced timing.";
CM_ SG_ 2364597758 EngCyl6TimingOffset "The ignition timing offset for Cylinder 6 from the engine timing advance (SPN 7355) as a command to the ignition control module. Positive values command an increasingly advanced timing.";
CM_ SG_ 2364597758 EngCyl5TimingOffset "The ignition timing offset for Cylinder 5 from the engine timing advance (SPN 7355) as a command to the ignition control module. Positive values command an increasingly advanced timing.";
CM_ SG_ 2364597758 EngCyl4TimingOffset "The ignition timing offset for Cylinder 4 from the engine timing advance (SPN 7355) as a command to the ignition control module. Positive values command an increasingly advanced timing.";
CM_ SG_ 2364597758 EngCyl3TimingOffset "The ignition timing offset for Cylinder 3 from the engine timing advance (SPN 7355) as a command to the ignition control module. Positive values command an increasingly advanced timing.";
CM_ SG_ 2364597758 EngCyl2TimingOffset "The ignition timing offset for Cylinder 2 from the engine timing advance (SPN 7355) as a command to the ignition control module. Positive values command an increasingly advanced timing.";
CM_ SG_ 2364597758 EngCyl1TimingOffset "The ignition timing offset for Cylinder 1 from the engine timing advance (SPN 7355) as a command to the ignition control module. Positive values command an increasingly advanced timing.";
CM_ BO_ 2364593150 "Predictive Cruise Control 1
Contains parameters related to predictive cruise control and roadway. Predictive cruise control is the process of varying the set point used by the cruise control algorithm based on external factors (e.g., anticipated ...";
CM_ SG_ 2364593150 RoadwayNextGradeDist "The distance from the current vehicle position to the grade indicated in SPN 7433.";
CM_ SG_ 2364593150 PrdctvCrsCtrlDrvlnDsnggInhibitRq "Request to temporarily inhibit a fuel saving feature that would normally open the driveline. Under certain conditions and with knowledge of the terrain, inhibiting this feature may improve fuel economy.
SPN 683 Disengage Driveline Request has ...";
CM_ SG_ 2364593150 VhclSpdCtrlOvrrideEventIndicator "Indicates to the operator that a Speed Control override event is active.  \"Speed Control\" refers to retarders or methods of automatically limiting vehicle speed, for instance on downhill grades.  An active event indicates that vehicle speed may ...";
CM_ SG_ 2364593150 PrdctvCrsCtrlSpeedEventIndicator "Indicates to the operator that a predictive cruise control (PCC) speed event is active. Typically, this will correspond to a Predictive Cruise Control Set Speed Offset (SPN 7316) request to increase or decrease vehicle speed from the nominal cruise ...";
CM_ SG_ 2364593150 PredictiveCruiseCtrlNextGrade "Road grade at an upcoming distance.  If SPN 9199 is supported, then this the road grade at the distance specified by SPN 9199. Positive numbers indicate uphill grade, negative are downhill for vehicle direction of travel.   For grades beyond the ...";
CM_ SG_ 2364593150 PredictiveCruiseCtrlPresentGrade "Road grade at present vehicle position. Positive numbers indicate uphill grade, negative are downhill for present vehicle direction of travel. For grades beyond the limits of the parameter, the limit value shall be reported.
Parameter Specific ...";
CM_ SG_ 2364593150 PredictiveCruiseCtrlEventInRange "Indicates that an event, such as a grade, is detected within the range of the predictive cruise control (PCC) look-ahead distance.
00 - No PCC event in range
01 - PCC event in range
10 - Error
11 - Not available
Note:  Intended to be sent ...";
CM_ SG_ 2364593150 VehicleSpeedCtrlOverrideRq "Speed control override requested. Indicates that the minimum restriction of speed is desired, for instance when travelling downhill towards an impending uphill grade. This is not a request to inhibit engine brakes (or other speed limiting device) ...";
CM_ SG_ 2364593150 PredictiveCruiseCtrlState "Indicates the state of the PCC controller.
If this parameter is 0001, the cruise control set point may be modified by the Predictive Cruise Control Set Speed Offset (SPN 7316) . For states other than 0001, the value in Predictive Cruise Control Set ...";
CM_ SG_ 2364593150 PrdctiveCruiseCtrlSetSpeedOffset "The amount by which the actual set point used by the cruise control algorithm should be changed as determined by external factors (e.g., anticipated road grade).
If SPN 7317 indicates Enabled (0001b) and if the cruise control algorithm determines ...";
CM_ BO_ 2364592894 "Engine Electronic Controller 18
Transmits command information for the actuators associated with engine.";
CM_ SG_ 2364592894 ExhGasRestrictionVlvPos "The position of the exhaust gas restriction valve expressed as a percentage of full travel. 0% means the valve is closed and no exhaust gas is flowing into the intake air stream. 100% means the valve is fully opened.";
CM_ SG_ 2364592894 InAirSourceVlv "Status of the actuator/valve in the airbox used to source engine intake air from either the engine compartment or external to the vehicle.

00 - Off
01 - On
10 - Error
11 - Not available";
CM_ SG_ 2364592894 EngCylHeadBypassActuator1Cmd "Command to cylinder head bypass actuator 1, normalized to percent, where 0% nominally represents fully closed (No Flow) and 100% represents fully open (Max Flow). The purpose of the cylinder bypass valve is to release the air at the high pressure ...";
CM_ BO_ 2364592638 "Engine Cylinder Head Bypass Actuator 1
Transmits information about Engine Cylinder Head Bypass Actuator. The cylinder head bypass
valve is used to release the air at the high pressure compressor outlet into turbocharger turbine inlet
when intake ...";
CM_ SG_ 2364592638 EngCylHdBypssActtr1OprtionStatus "Identifies the status of Engine Cylinder Head Bypass Actuator 1.
Cylinder head bypass valve is used to release the air at the high pressure compressor outlet into turbocharger turbine inlet when intake pressure exceeds exhaust pressure at lower ...";
CM_ SG_ 2364592638 EngCylHeadBypassActuator1Pos "Actual position of Engine Cylinder Head Bypass actuator, where 0% represents fully closed and 100% represents fully open.
Cylinder Head bypass valve is used to release the air at the high pressure compressor outlet into turbocharger turbine inlet ...";
CM_ SG_ 2364592638 EngCylHdBypssActuator1DesiredPos "Requested position of Engine Cylinder Head Bypass actuator by engine ECM, where 0% represents bypass fully closed and 100% represents fully open. This is the position that the device is attempting to achieve.
Cylinder Head bypass valve is used to ...";
CM_ SG_ 2364592638 EngCylHeadBypassActuator1Temp "Temperature of the Engine Cylinder Head Bypass Actuator 1 drive circuitry. Temperature excursions may affect the torque output.
Cylinder Head bypass valve is used to release the air at the high pressure compressor outlet into turbocharger turbine ...";
CM_ SG_ 2364592638 EngCylHdBypssActuator1TempStatus "Identifies the status of the Engine Cylinder Head Bypass Blowoff Actuator 1 drive circuitry temperature. Temperature excursions may affect the torque output.
Cylinder Head bypass valve is used to release the air at the high pressure compressor ...";
CM_ SG_ 2364592638 EngCylHdBypssActtr1PrliminaryFMI "Used to identify the applicable J1939-73 FMI detected in Engine Cylinder Head Bypass Actuator 1 by the manufacturer's software. When there are multiple failures, the most severe is transmitted.
A value of 31 is sent to indicate that no failure has ...";
CM_ BO_ 2364592382 "Engine Cylinder Combustion Request
Transmits combustion related requests";
CM_ SG_ 2364592382 EngCyl24ExcludeFromCombustionRq "Request to the engine ECU to exclude (skip or cut-out) cylinder 24 from combustion.

00 Exclude from Combustion
01 Include for Combustion
10 Reserved
11 Not available/Do not care";
CM_ SG_ 2364592382 EngCyl23ExcludeFromCombustionRq "Request to the engine ECU to exclude (skip or cut-out) cylinder 23 from combustion.

00 Exclude from Combustion
01 Include for Combustion
10 Reserved
11 Not available/Do not care";
CM_ SG_ 2364592382 EngCyl22ExcludeFromCombustionRq "Request to the engine ECU to exclude (skip or cut-out) cylinder 22 from combustion.

00 Exclude from Combustion
01 Include for Combustion
10 Reserved
11 Not available/Do not care";
CM_ SG_ 2364592382 EngCyl21ExcludeFromCombustionRq "Request to the engine ECU to exclude (skip or cut-out) cylinder 21 from combustion.

00 Exclude from Combustion
01 Include for Combustion
10 Reserved
11 Not available/Do not care";
CM_ SG_ 2364592382 EngCyl20ExcludeFromCombustionRq "Request to the engine ECU to exclude (skip or cut-out) cylinder 20 from combustion.

00 Exclude from Combustion
01 Include for Combustion
10 Reserved
11 Not available/Do not care";
CM_ SG_ 2364592382 EngCyl19ExcludeFromCombustionRq "Request to the engine ECU to exclude (skip or cut-out) cylinder 19 from combustion.

00 Exclude from Combustion
01 Include for Combustion
10 Reserved
11 Not available/Do not care";
CM_ SG_ 2364592382 EngCyl18ExcludeFromCombustionRq "Request to the engine ECU to exclude (skip or cut-out) cylinder 18 from combustion.

00 Exclude from Combustion
01 Include for Combustion
10 Reserved
11 Not available/Do not care";
CM_ SG_ 2364592382 EngCyl17ExcludeFromCombustionRq "Request to the engine ECU to exclude (skip or cut-out) cylinder 17 from combustion.

00 Exclude from Combustion
01 Include for Combustion
10 Reserved
11 Not available/Do not care";
CM_ SG_ 2364592382 EngCyl16ExcludeFromCombustionRq "Request to the engine ECU to exclude (skip or cut-out) cylinder 16 from combustion.

00 Exclude from Combustion
01 Include for Combustion
10 Reserved
11 Not available/Do not care";
CM_ SG_ 2364592382 EngCyl15ExcludeFromCombustionRq "Request to the engine ECU to exclude (skip or cut-out) cylinder 15 from combustion.

00 Exclude from Combustion
01 Include for Combustion
10 Reserved
11 Not available/Do not care";
CM_ SG_ 2364592382 EngCyl14ExcludeFromCombustionRq "Request to the engine ECU to exclude (skip or cut-out) cylinder 14 from combustion.

00 Exclude from Combustion
01 Include for Combustion
10 Reserved
11 Not available/Do not care";
CM_ SG_ 2364592382 EngCyl13ExcludeFromCombustionRq "Request to the engine ECU to exclude (skip or cut-out) cylinder 13 from combustion.

00 Exclude from Combustion
01 Include for Combustion
10 Reserved
11 Not available/Do not care";
CM_ SG_ 2364592382 EngCyl12ExcludeFromCombustionRq "Request to the engine ECU to exclude (skip or cut-out) cylinder 12 from combustion.

00 Exclude from Combustion
01 Include for Combustion
10 Reserved
11 Not available/Do not care";
CM_ SG_ 2364592382 EngCyl11ExcludeFromCombustionRq "Request to the engine ECU to exclude (skip or cut-out) cylinder 11 from combustion.

00 Exclude from Combustion
01 Include for Combustion
10 Reserved
11 Not available/Do not care";
CM_ SG_ 2364592382 EngCyl10ExcludeFromCombustionRq "Request to the engine ECU to exclude (skip or cut-out) cylinder 10 from combustion.

00 Exclude from Combustion
01 Include for Combustion
10 Reserved
11 Not available/Do not care";
CM_ SG_ 2364592382 EngCyl9ExcludeFromCombustionRq "Request to the engine ECU to exclude (skip or cut-out) cylinder 9 from combustion.

00 Exclude from Combustion
01 Include for Combustion
10 Reserved
11 Not available/Do not care";
CM_ SG_ 2364592382 EngCyl8ExcludeFromCombustionRq "Request to the engine ECU to exclude (skip or cut-out) cylinder 8 from combustion.

00 Exclude from Combustion
01 Include for Combustion
10 Reserved
11 Not available/Do not care";
CM_ SG_ 2364592382 EngCyl7ExcludeFromCombustionRq "Request to the engine ECU to exclude (skip or cut-out) cylinder 7 from combustion.

00 Exclude from Combustion
01 Include for Combustion
10 Reserved
11 Not available/Do not care";
CM_ SG_ 2364592382 EngCyl6ExcludeFromCombustionRq "Request to the engine ECU to exclude (skip or cut-out) cylinder 6 from combustion.

00 Exclude from Combustion
01 Include for Combustion
10 Reserved
11 Not available/Do not care";
CM_ SG_ 2364592382 EngCyl5ExcludeFromCombustionRq "Request to the engine ECU to exclude (skip or cut-out) cylinder 5 from combustion.

00 Exclude from Combustion
01 Include for Combustion
10 Reserved
11 Not available/Do not care";
CM_ SG_ 2364592382 EngCyl4ExcludeFromCombustionRq "Request to the engine ECU to exclude (skip or cut-out) cylinder 4 from combustion.

00 Exclude from Combustion
01 Include for Combustion
10 Reserved
11 Not available/Do not care";
CM_ SG_ 2364592382 EngCyl3ExcludeFromCombustionRq "Request to the engine ECU to exclude (skip or cut-out) cylinder 3 from combustion.

00 Exclude from Combustion
01 Include for Combustion
10 Reserved
11 Not available/Do not care";
CM_ SG_ 2364592382 EngCyl2ExcludeFromCombustionRq "Request to the engine ECU to exclude (skip or cut-out) cylinder 2 from combustion.

00 Exclude from Combustion
01 Include for Combustion
10 Reserved
11 Not available/Do not care";
CM_ SG_ 2364592382 EngCyl1ExcludeFromCombustionRq "Request to the engine ECU to exclude (skip or cut-out) cylinder 1 from combustion.

00 Exclude from Combustion
01 Include for Combustion
10 Reserved
11 Not available/Do not care";
CM_ SG_ 2364592382 NmbrOfEngCylndrsTExcldFrmCmbston "Request to the engine ECU for the number of cylinders to exclude from combustion (cut-out or skip) for a given instance in time.  The engine ECU can decide on the cylinders to exclude from combustion.  One of the use cases would be sending this ...";
CM_ BO_ 2364567294 "Fuel Pump Actuator Control Command
Used to transmit the commanded % position for the Fuel Pump control valve.";
CM_ SG_ 2364567294 EngFlInjctnPump2FuelCtrlValveCmd "The control command to fuel control valve in fuel pump 2, normalized to percent, where 0% represents fully closed and 100% represents fully open.";
CM_ SG_ 2364567294 EngFlInjctnPump1FuelCtrlValveCmd "The control command to fuel control valve in fuel pump 1, normalized to percent, where 0% represents fully closed and 100% represents fully open.";
CM_ BO_ 2558918398 "Cab Message 2
Message containing parameters originating from the vehicle cab.";
CM_ SG_ 2558918398 EngIdleMnmgtPendingEventOvrd "Command signal which allows the operator to override an impending engine idle management start-up or an impending engine idle management shutdown.
00b - Off (not requesting an override)
01b - On (requesting an override)
10b - Error
11b - Not ...";
CM_ SG_ 2558918398 ActiveShiftConsoleReq "Requests the shift console or shift selector that the operator desires to be active. See SPN 2945 (Active Shift Console Indicator) for feedback on which shift console is currently active.
00 - Use Primary Shift Console
01 - Use Secondary Shift ...";
CM_ SG_ 2558918398 AFTSysEnableCmd "Request to enable Aftertreatment system.
00 = De-activate Aftertreatment System
01 = Activate Aftertreatment System
10 = Reserved
11 = Don't care/Take no Action
Note: In some marine applications it may be desireable to enable or disable the ...";
CM_ SG_ 2558918398 EngStopStartDisCmd "Engine Stop-Start Disable Command indicates the desire to disable the engine stop-start functionality during propulsion modes. For momentary switches, this parameter does not indicate the state of the switch contacts, but the operator desired state.
 ...";
CM_ SG_ 2558918398 TransAutoNeutralEnableSw "This enable switch is for optional use with interfaces using SPN 7695 [Transmission Auto-Neutral (Manual Return) Request] or another vehicle input configured for Auto-Neutral (Manual Return) functionality. When supported by the vehicle system and ...";
CM_ SG_ 2558918398 AFTRegenEngSpdAllowedSw "If this parameter is 01, then the aftertreatment control system is permitted to perform an aftertreatment regeneration, but the aftertreatment control system is not allowed to take control of the engine speed for the purposes of regeneration. A ...";
CM_ SG_ 2558918398 ElevatedEngSpdAllowedSw "Indicates the state of a switch to indicate the control system is permitted to automatically elevate the engine speed as needed for strategies such as cold mode, aftertreatment regeneration, etc. This is not a direct command to increase the engine ...";
CM_ SG_ 2558918398 PrdctvCriseCtrlMaxNegativeOffset "Maximum speed decrease that the predictive cruise control (PCC) is allowed to request. This may be adjusted by the operator (either directly or indirectly) to tailor the performance of the PCC system.
This parameter is used in conjunction with ...";
CM_ SG_ 2558918398 PrdctvCriseCtrlMaxPositiveOffset "Maximum speed increase that the predictive cruise control (PCC) is allowed to request. This may be adjusted by the operator (either directly or indirectly) to tailor the performance of the PCC system.
This parameter is used in conjunction with ...";
CM_ SG_ 2558918398 PrdctiveCruiseCtrlDeactivationRq "Indicates that the operator has requested to deactivate the predictive cruise control (PCC) function.
If enabled, the PCC device may still provide notification of events in range, road grade, and other information. But if requested to be ...";
CM_ SG_ 2558918398 PredictiveCruiseCtrlEnableSwitch "Indicates whether predictive cruise control (PCC) is enabled. When not enabled, the predictive cruise control does not calculate a speed offset or identify predictive cruise events, and the predictive cruise control state (SPN 7317) shall not be ...";
CM_ SG_ 2558918398 HtExchngerDebrisPurgeForceSwitch "Indicates the state of a switch available to the operator that forces the system to purge the debris from the heat exchanger.
00   not active
01   active
10   error
11   not available
This SPN would be 뱊ot active� when purging the debris from ...";
CM_ SG_ 2558918398 HtExchngrDbrisPurgeInhibitSwitch "Indicates the state of a switch available to the operator that will inhibit the system from purging the debris from the heat exchanger.
00   not active
01   active
10   error
11   not available
This SPN would be 뱊ot active� when purging the ...";
CM_ SG_ 2558918398 SCROprtrInducementOverrideSwitch "The position of the operator inducement override switch. This switch function allows the operator to override an operator inducement derate.
See EU Commission directive 2012/46/EU. Appendix 1 Section 5.5 for more information.
00 Off
01 On
10 ...";
CM_ SG_ 2558918398 PerformanceBiasSelection "Indicates the operating bias toward performance of the power source.
0% Functionality is biased toward fuel economy as much as possible.
50% Functionality is biased toward neither fuel economy or performance.
100% Functionality is biased toward ...";
CM_ SG_ 2558918398 EngFan2RequestedPercentSpeed "Fan speed of the second fan in the system as a ratio of the actual fan drive (current speed) to the fully engaged fan drive (maximum fan speed). A two state fan (off/on) will use 0% and 100% respectively.  A three state fan (off/intermediate/on) ...";
CM_ BO_ 2558852862 "Aftertreatment 1 Particulate Sensor Control
This PGN contains parameters used to control the particulate sensor and to provide data that the particulate sensor needs to operate.";
CM_ SG_ 2558852862 ExhVelocity "Velocity of the exhaust gas near the particulate sensor.";
CM_ SG_ 2558852862 ExhTemp "This is the temperature in the exhaust stream that is closest to the particulate sensor. This could be a calculated value or read from another sensor. The ECU transmitting this message to the particulate sensor controller will be aware of the ...";
CM_ SG_ 2558852862 Dewpoint "Indicates that the temperature near the particulate sensor has exceeded the dew point.

00 - Dewpoint has not been reached
01 - Dewpoint has been reached
10 - SAE reserved
11 - Not available";
CM_ SG_ 2558852862 RegenReq "Another ECU would send this to request that the particulate sensor perform a regeneration of the sensor.  A request would be considered active when this parameter transitions from 00 to 01.
00 - Regeneration not requested
01 - Regeneration ...";
CM_ SG_ 2558852862 ShutdownReq "Aftertreatment 1 particulate sensor shutdown request.

00 - Shutdown request not active
01 - Shutdown request active
10 - SAE reserved
11 - Not available";
CM_ BO_ 2558787326 "Payload Calibration Information Command
Calibration setting commands for the Payload Measurement System.";
CM_ SG_ 2558787326 PayloadCorrectionFactorCmd "The payload correction factor is used to fine tune the sensor gain value.
Correction factor calibration of the Payload Measurement system is performed through a Payload Calibration Set Point SPN value of Correction Point and the Payload Correction ...";
CM_ SG_ 2558787326 PayloadCalibCommandedWeight "The true known mass of real load weight applicable for the calibration point specified in SPN 6871 and used for calibrating Payload system.
Multipoint calibration of the Payload Measurement system is perfomed by loading the machine with up to 10 ...";
CM_ SG_ 2558787326 PayloadCalibSetPointCmd "Specifies the current payload point being calibrated. The data specified in the 'Payload Calibration Commanded Weight' SPN (SPN 6872) or 'Payload Correction Factor Command' SPN (SPN 6873) shall be used for calibrating this specified payload point ...";
CM_ BO_ 2558721790 "Tire Configuration Command Information
Details the attributes for the tire monitoring settings for the tires.";
CM_ SG_ 2558721790 SnsrEnableSetting "Command signal used to enable/disable the tire sensor. On receipt of this command, the tire sensor may either be enabled or disabled.

00 Off / Isolate / Disable
01 On / Enable
10 Reserved / Not Defined
11 Don뭪 Care / Take No Action";
CM_ SG_ 2558721790 OverTempSetting "Configurable constant temperature above which an over temperature alert will trigger.";
CM_ SG_ 2558721790 OvrPrssPrcentageThresholdSetting "Configurable percentage deviation from the set cold inflation pressure, for the over tire pressure alert.";
CM_ SG_ 2558721790 ExtrmUndrPrssPrcntgThrshldStting "Configurable percent deviation from the set cold inflation pressure, for the extreme under tire pressure alert.";
CM_ SG_ 2558721790 UndrPrssPrcntageThresholdSetting "Configurable percent deviation from the set cold inflation pressure, for the under tire pressure alert.";
CM_ SG_ 2558721790 ColdInflationPressSetting "Configurable value of the cold inflation pressure of the tire. Cold inflation pressure is the default/reference inflation pressure suggested by the manufacturer for a specific tire.";
CM_ SG_ 2558721790 TireLocation "The location of monitored tire on the vehicle.
The high order 4 bits indicate the vehicle axle position of the tire, counting front to back on the vehicle, with the value 0 representing the front axle on the vehicle. If the upper 4 bits have a ...";
CM_ BO_ 2558656254 "Aftertreatment System Control
Used to request the aftertreatment system to perform or inhibit certain operations.";
CM_ SG_ 2558656254 DEFDoserReadyStatus "Indicates the aftertreatment systems operating conditions are appropriate for dosing.
Note: Operating conditions may include but not limited to Diesel Exhaust Fluid tank level and Diesel Exhaust Fluid tank temperature are within the operating ...";
CM_ SG_ 2558656254 EnableStatus "Indicates that the aftertreatment system is enabled or disabled.  Enabled indicates the system will dose at regular intervals.
00 - Aftertreatment System is Disabled
01 - Aftertreatment System is Enabled
10 - Error
11 - Not available
Note:  In ...";
CM_ SG_ 2558656254 RqToPermitDEFDosingTestInjection "A request to permit the DEF dosing test injection. The request continues to be broadcast until the test injection is finished or the corresponding permission status indicates an error.
000 = no request
001 = request to permit DEF Dosing Test ...";
CM_ SG_ 2558656254 RqToPermitDEFHydStiffnessCheck "A request to permit the DEF hydraulic stiffness check. The request continues to be broadcast until the stiffness check is finished or the corresponding permission status indicates an error.
00 = no request
01 = request to permit DEF hydraulic ...";
CM_ SG_ 2558656254 ThermalMnmgtInhReq "Provides state of inhibit request for Aftertreatment thermal management from external system.
Aftertreatment Thermal Management indicates that the exhaust temperatures have been controlled for expected functioning of the aftertreatment system - ...";
CM_ BO_ 2558590718 "Hybrid System Control 1
This messages is sent to the hybrid system to control hybrid related features.";
CM_ SG_ 2558590718 PropulsionModeReqDist "The requested distance to maintain a Hybrid Propulsion Mode (see SPN 7889) other than Mode 1 - Stored Energy Source Sustaining.
When the distance is met, or a protective mode is activated (e.g. HVES charge is depleted while in Mode 5 - Stored ...";
CM_ SG_ 2558590718 PropulsionModeReqMaxSpd "The requested maximum speed for the vehicle while in a Hybrid Propulsion Mode (see SPN 7889) other than Mode 1 - Stored Energy Source Sustaining.
This shall be the operating vehicle speed limit while in the range defined by Hybrid Propulsion Mode ...";
CM_ SG_ 2558590718 StoredESSetPointReq "Stored Energy Source Set Point Request is used to set the percentage that the Stored Energy Source should be managed to by the system.
A value of 0xFB indicates a request for the default set point.  In the case of a Diesel-Electric Hybrid, the ...";
CM_ SG_ 2558590718 StoredESCharge_DischargeRateReq "Stored Energy Source Charge/Discharge Rate Request is used to control the rate at which the stored energy is changed in Energy Increasing or Energy Depleting modes.
A value of 0xFB indicates a request for the default charge/discharge rate.  In a ...";
CM_ SG_ 2558590718 ExtlESConnectionDemand "External Energy Source Connection Demand indicates how the hybrid system should engage with the external energy source that is temporarily connected to the vehicle.
This parameter allows for two external energy source connections.  Propulsion may ...";
CM_ SG_ 2558590718 PropulsionModeReq "Hybrid Propulsion Mode Request is the operator intended propulsion mode.  This parameter can be from only one source on the vehicle.  Response to this request can be found in the Hybrid Propulsion Mode Status (SPN 7896) and Hybrid Propulsion Mode ...";
CM_ SG_ 2558590718 OpVehModeReq "Operator Vehicle Mode Request is the operator intended vehicle mode.  This parameter can be from only one source on the vehicle.  In the case of a Diesel-Electric Hybrid, the source of this parameter may be a vehicle controller that monitors the ...";
CM_ SG_ 2558590718 ShutdownCmd "Indicates the Hybrid System Shutdown Request state.  The signal gives network controllers the ability to disable all hybrid system functionality including propulsion, regenerative braking, and hybrid powered accessories.  For electric hybrids, the ...";
CM_ SG_ 2558590718 PropulsionDisableReq "Indicates the Hybrid System Disable Request state.  The signal gives network controllers the ability to disable the propulsion aspect of hybrid system operation when this request is on.  However, hybrid powered accessories may be on and the engine ...";
CM_ SG_ 2558590718 HybrdSystmRgnrtvBrakingDisableRq "Indicates the hybrid system regenerative braking disable request state.  This signal gives network controllers the ability to disable all regenerative braking.  This is not the operator controlled switch that performs regenerative braking disable ...";
CM_ SG_ 2558590718 HybridSystemProtectionOverrideRq "Indicates the hybrid system protection override request state.  This request allows overriding of hybrid system protection
features and failure modes allowing hybrid systems to continue to operate, if possible. This is not the physical switch that ...";
CM_ BO_ 2350776062 "Engine Ignition Controller
Commanded engine ignition timing advance";
CM_ SG_ 2350776062 EngTimingAdvance "Ignition timing as a command to the ignition control module.  Positive values command an increasingly advanced timing from TDC. The same timing applies to all cylinders. Use SPN 7356 - SPN 7379 for cylinder specific timing offsets from this timing.";
CM_ BO_ 2350710526 "Transmission Control 3
This message is used to control the output speed and/or torque of a transmission.
For example, this message could be directed toward a continuously variable transmission (CVT) where output speed and torque are not directly ...";
CM_ SG_ 2350710526 MessageChecksum "The message checksum is used to verify the signal path from the transmitting device to the receiving device.
The message checksum is calculated using the first 7 data bytes, the message counter and the bytes of the message identifier. It is ...";
CM_ SG_ 2350710526 TransRequestedTorque_TorqueLimit "Requested transmission output torque measured as a percentage of Transmission Reference Torque (SPN 7778). This is the output torque at which the transmission is expected to operate if the torque control mode is active or the output torque which the ...";
CM_ SG_ 2350710526 TransRequestedOutputShaftSpeed "Used to request output shaft speed of the transmission which has a output through a driveline to the wheels of a machine/vehicle.";
CM_ SG_ 2350710526 MessageCounter "The message counter is used to detect situations where the transmitting ECU malfunction repeats the same frame all the time.  The receiver of the information may use the counter parameter to detect this situation.
Note:  The initial value of the 4 ...";
CM_ SG_ 2350710526 TransOverrideCtrlModePriority "This field is used as an input to the transmission to determine the priority of the Override Control Mode received in the Torque/Speed Control message.  The default is 11 (Low priority).  It is not required to use the same priority during the entire ...";
CM_ SG_ 2350710526 TransOverrideCtrlMode "The override control mode defines the type of control mode used to control transmission operation.
00 = Override disabled - Disable any existing control commanded by the source of this command.
01 = Speed control - Control speed to the included ...";
CM_ BO_ 2582642430 "Proprietary A2
This proprietary PG uses the Destination Specific PDU Format allowing manufacturers to direct their proprietary communications to a specific destination node.";
CM_ BO_ 2566836734 "Oxygen Sensor Test Results
SAE J1939 will not specify an implementation for this DM.  Oxygen sensor test and results should be communicated using DM7 and DM8";
CM_ BO_ 2566801918 "Ground-based Speed and Distance
This message is normally sent by the Tractor ECU on the implement bus on construction and agricultural implements and provides to connected systems, the current measured ground speed.";
CM_ SG_ 2566801918 GroundBasedDirection "A measured signal indicating either forward or reverse as the direction of travel.  When speed is zero, indicate the last travel direction until a different direction is detected.

00 Reverse
01 Forward
10 Error indication
11 Not available";
CM_ SG_ 2566801918 GroundBasedImplementDistance "Actual distance travelled by a machine based on measurements from a sensor such as RADAR.  When distance exceeds 4 211 081.215 m, the value should be reset to zero and incremented as additional distance accrues.";
CM_ SG_ 2566801918 GroundBasedImplementSpeed "Actual ground speed of a machine, measured by a sensor such as RADAR.";
CM_ BO_ 2566801662 "Wheel-based Speed and Distance
This message is sent by the Tractor ECU on the implement bus on construction and agricultural implements and provides to connected systems, the current measured wheel-based speed.";
CM_ SG_ 2566801662 KeySwitchNOTOFF "Indicates the Key Switch of the tractor or power unit is NOT in the Off position. This does not indicate unforeseen power interruption such as those caused by starting the engine or due to connector intermittents.
00 Key Switch Off
01 Key Switch ...";
CM_ SG_ 2566801662 WheelBasedDirection "A measured signal indicating either forward or reverse as the direction of travel.  When speed is zero, indicate the last travel direction until a different direction is detected or selected and engaged.
00 Reverse
01 Forward
10 Error indication
 ...";
CM_ SG_ 2566801662 MaxTimeOfTractorPower "The maximum time of remaining tractor or power unit supplied electrical power at the current load.";
CM_ SG_ 2566801662 WheelBasedDistance "The distance travelled by a machine as calculated from wheel or tail shaft speed.  When distance exceeds 4211081,215 m, the value should be reset to zero and incremented as additional distance accrues.";
CM_ SG_ 2566801662 WheelBasedSpeed "A value of the speed of a machine as calculated from the measured wheel or tail shaft speed.";
CM_ BO_ 2566801406 "Maintain Power
This message is sent by any ECU connected to the implement bus requesting that the Tractor ECU not switch off the power for the next 2 seconds.";
CM_ SG_ 2566801406 ImplementInWorkState "Indicates that an implement is connected to a tractor or power unit and is 밿n-work�.

00   Implement is 뱋ut of work�
01   Implement is 밿n-work�
10   Error indication
11   Not available";
CM_ SG_ 2566801406 ImplementTransportState "Indicates the transport state of an implement connected to a tractor or power unit.

00 Implement may Not be transported 
01 Implement may be transported
10 Error indication
11 Not available";
CM_ SG_ 2566801406 ImplementParkState "Indicates the state of an implement where it may be disconnected from a tractor or power unit.

00 Implement may Not be disconnected 
01 Implement may be disconnected
10 Error indication
11 Not available";
CM_ SG_ 2566801406 ImplementWorkState "Indicates that an implement is connected to a tractor or power unit and is ready for work

00 Implement is Not ready for field work 
01 Implement is ready for field work
10 Error indication
11 Not available";
CM_ SG_ 2566801406 MaintainECUPower "Request to the Tractor ECU to maintain ECU_PWR power for the next 2 seconds.

00 No Further Requirement for ECU_PWR
01 Requirement for 2 more seconds of ECU_PWR
10 Reserved 
11 Don뭪 Care";
CM_ SG_ 2566801406 MaintainAcuatorPower "Request to the Tractor ECU to maintain PWR power for the next 2 seconds.

00 No Further Requirement for PWR
01 Requirement for 2 more seconds of PWR
10 Reserved 
11 Don뭪 Care";
CM_ BO_ 2566801150 "Secondary or Front Hitch Status
This message provides the measurement of the current front hitch parameters.";
CM_ SG_ 2566801150 FrontDraft "The apparent horizontal force applied to the front hitch by an implement.  A positive value indicates force applied to the tractor opposed to heading.";
CM_ SG_ 2566801150 FrontNominalLowerLinkForce "This measurement provides an indication of draft at the lower links of the front three point hitch. Nominal lower link force may be expected to be approximately linear with respect to draft and may be proportional to draft for a single hitch ...";
CM_ SG_ 2566801150 FrontHitchInworkIndication "A measured signal indicating that the front hitch is positioned below (in-work) or above (out-of-work) an adjustable switching threshold.

00 Hitch position is out-of-work 
01 Hitch position is in-work
10 Error indication
11 Not available";
CM_ SG_ 2566801150 FrontHitchPos "The measured position of the front three-point-hitch.  Expressed as a percentage of full travel.  Zero percent indicates the full down position, and 100%, the full up position.";
CM_ BO_ 2566800894 "Primary or Rear Hitch Status
This message provides the measurement of the current rear hitch parameters.";
CM_ SG_ 2566800894 RearHitchExit_reasonCode "This parameter indicates why the Rear Hitch cannot accept remote commands or has most recently stopped accepting remote commands.
0-No reason/all clear
1-Operator presence not detected
2-Implement released control of function
3-Operator override ...";
CM_ SG_ 2566800894 RearDraft "The apparent horizontal force applied to the rear hitch by an implement.  A positive value indicates force applied to the tractor opposed to heading.";
CM_ SG_ 2566800894 RearNominalLowerLinkForce "This measurement provides an indication of draft at the lower links of the rear three point hitch. Nominal lower link force may be expected to be approximately linear with respect to draft and may be proportional to draft for a single hitch ...";
CM_ SG_ 2566800894 RearHitchInworkIndication "A measured signal indicating that the rear hitch is positioned below (in-work) or above (out-of-work) an adjustable switching threshold.  The method of determining switching threshold is not standardise and will be determined by machine designers.
 ...";
CM_ SG_ 2566800894 RearHitchPos "The measured position of the rear three-point-hitch.  Expressed as a percentage of full travel.  Zero percent indicates the full down position, and 100%, the full up position.";
CM_ BO_ 2566800638 "Secondary or Front Power Take off Output Shaft
This message provides the measurement of the current secondary or front PTO output shaft parameters.";
CM_ SG_ 2566800638 FrontPTOExit_reasonCode "This parameter indicates why the Front PTO cannot accept remote commands or has most recently stopped accepting remote commands.
0-No reason/all clear
1-Operator presence not detected
2-Implement released control of function
3-Operator override ...";
CM_ SG_ 2566800638 FrontHitchExit_reasonCode "This parameter indicates why the Front Hitch cannot accept remote commands or has most recently stopped accepting remote commands.
0-No reason/all clear
1-Operator presence not detected
2-Implement released control of function
3-Operator ...";
CM_ SG_ 2566800638 FrontPowerTakeOffEngagement "A measured signal indicating that the front power take off is engaged or disengage.

00 Power take off disengaged
01 Power take off engaged
10 Error indication
11 Not available";
CM_ SG_ 2566800638 FrontPowerTakeOffMode "A measured signal indicating that the front power take off mode is either 540 or 1000 rpm. 

00 Power take off mode is 540
01 Power take off mode is 1000
10 Error indication
11 Not available";
CM_ SG_ 2566800638 FrontPowerTakeOffEconomyMode "A measured signal indicating that the front power take off economy mode is engaged or disengaged. Economy mode PTO operate at 540 or 1000 rpm at a lower engine rpm.
00 Power take off economy mode is disengaged
01 Power take off economy mode is ...";
CM_ SG_ 2566800638 FrontPTOOutputShaftSpeedSetPoint "The measured value of the set point of the rotational speed of the front power take off (PTO) output shaft.";
CM_ SG_ 2566800638 FrontPTOOutputShaftSpeed "The measured rotational speed of the front power take off (PTO) output shaft. For existing tractors that monitor PTO speed prior to the engagement clutch, the PTO speed would only be valid when PTO is engaged and not available when PTO disengaged.";
CM_ BO_ 2566800382 "Primary or Rear Power Take off Output Shaft
This message provides the measurement of the current primary or rear PTO output shaft parameters.";
CM_ SG_ 2566800382 RearPTOExit_reasonCode "This parameter indicates why the Rear PTO cannot accept remote commands or has most recently stopped accepting remote commands.
0-No reason/all clear
1-Operator presence not detected
2-Implement released control of function
3-Operator override ...";
CM_ SG_ 2566800382 RearPowerTakeOffEngagement "A measured signal indicating that the rear power take off is engaged or disengage.

00 Power take off disengaged
01 Power take off engaged
10 Error indication
11 Not available";
CM_ SG_ 2566800382 RearPowerTakeOffMode "A measured signal indicating that the rear power take off mode is either 540 or 1000 rpm. 

00 Power take off mode is 540
01 Power take off mode is 1000
10 Error indication
11 Not available";
CM_ SG_ 2566800382 RearPowerTakeOffEconomyMode "A measured signal indicating that the rear power take off economy mode is engaged or disengaged. Economy mode PTO operate at 540 or 1000 rpm at a lower engine rpm.
00 Power take off economy mode is disengaged
01 Power take off economy mode is ...";
CM_ SG_ 2566800382 RearPTOOutputShaftSpeedSetPoint "The measured value of the set point of the rotational speed of the rear power take off (PTO) output shaft.";
CM_ SG_ 2566800382 RearPTOOutputShaftSpeed "The measured rotational speed of the rear power take off (PTO) output shaft. For existing tractors that monitor PTO speed prior to the engagement clutch, the PTO speed would only be valid when PTO is engaged and not available when PTO disengaged.";
CM_ BO_ 2566800126 "Hitch and PTO Commands
This message provides control of the hitch position, PTO shaft set point speed and PTO engagement.";
CM_ SG_ 2566800126 FrontPowerTakeOffModeCmd "The command to select the mode of the front power take off .

00 Select 540 rpm mode
01 Select 1000 rpm mode 
10 Reserved
11 Don뭪 Care";
CM_ SG_ 2566800126 RearPowerTakeOffModeCmd "The command to select the mode of the rear power take off .

00 Select 540 rpm mode
01 Select 1000 rpm mode 
10 Reserved
11 Don뭪 Care";
CM_ SG_ 2566800126 FrontPowerTakeOffEconomyModeCmd "The command to engage or disengage the front power take off몊 economy mode.

00 Disengage Power take off몊 economy mode
01 Engage Power take off몊 economy mode
10 Reserved
11 Don뭪 Care";
CM_ SG_ 2566800126 RearPowerTakeOffEconomyModeCmd "The command to engage or disengage the rear power take off몊 economy mode.

00 Disengage Power take off몊 economy mode
01 Engage Power take off몊 economy mode
10 Reserved
11 Don뭪 Care";
CM_ SG_ 2566800126 FrontPowerTakeOffEngagementCmd "The command to engage or disengage the front power take off .

00 Disengage Power take off
01 Engage Power take off 
10 Reserved
11 Don뭪 Care";
CM_ SG_ 2566800126 RearPowerTakeOffEngagementCmd "The command to engage or disengage the rear power take off .

00 Disengage Power take off
01 Engage Power take off 
10 Reserved
11 Don뭪 Care";
CM_ SG_ 2566800126 RrPTOOutputShaftSpeedSetPointCmd "The command to set the rotational speed of the rear power take off (PTO) output shaft.";
CM_ SG_ 2566800126 FrntPTOOtptShaftSpeedSetPointCmd "The command to set the rotational speed of the front power take off (PTO) output shaft.";
CM_ SG_ 2566800126 RearHitchPosCmd "Command to allow the position of the rear three-point-hitch to be set.  Expressed as a percentage of full travel.  Zero percent indicates the full down position, and 100%, the full up position.";
CM_ SG_ 2566800126 FrontHitchPosCmd "Command to allow the position of the front three-point-hitch to be set.  Expressed as a percentage of full travel.  Zero percent indicates the full down position, and 100%, the full up position.";
CM_ BO_ 2566799358 "Auxiliary Valve Number 15 Command
This message provides control of the flow through the auxiliary valves.";
CM_ SG_ 2566799358 AuxValve15FailSafeModeCmd "Command for setting the fail safe mode of an auxiliary valve.

00 Block
01 Float
10 Reserved
11 Don뭪 Care";
CM_ SG_ 2566799358 AuxValve15StateCmd "Command for setting the auxiliary valve state.  With float enabled, hydraulic fluid may flow to or from the tractor as driven by the implement.

0000 Block
0001 Extend
0010 Retract
0011 Float
0100-1110 Reserved
1111 Don뭪 Care";
CM_ SG_ 2566799358 AuxValve15PortFlowCmd "The command to set the flow through the  extend or retract port of an auxiliary valve of a tractor, expressed as a percentage of full flow.  Zero percent indicates no flow, 100% indicates maximum flow, flow returns to the tractor through the ...";
CM_ BO_ 2566799102 "Auxiliary Valve Number 14 Command
This message provides control of the flow through the auxiliary valves.";
CM_ SG_ 2566799102 AuxValve14FailSafeModeCmd "Command for setting the fail safe mode of an auxiliary valve.

00 Block
01 Float
10 Reserved
11 Don뭪 Care";
CM_ SG_ 2566799102 AuxValve14StateCmd "Command for setting the auxiliary valve state.  With float enabled, hydraulic fluid may flow to or from the tractor as driven by the implement.

0000 Block
0001 Extend
0010 Retract
0011 Float
0100-1110 Reserved
1111 Don뭪 Care";
CM_ SG_ 2566799102 AuxValve14PortFlowCmd "The command to set the flow through the  extend or retract port of an auxiliary valve of a tractor, expressed as a percentage of full flow.  Zero percent indicates no flow, 100% indicates maximum flow, flow returns to the tractor through the ...";
CM_ BO_ 2566798846 "Auxiliary Valve Number 13 Command
This message provides control of the flow through the auxiliary valves.";
CM_ SG_ 2566798846 AuxValve13FailSafeModeCmd "Command for setting the fail safe mode of an auxiliary valve.

00 Block
01 Float
10 Reserved
11 Don뭪 Care";
CM_ SG_ 2566798846 AuxValve13StateCmd "Command for setting the auxiliary valve state.  With float enabled, hydraulic fluid may flow to or from the tractor as driven by the implement.

0000 Block
0001 Extend
0010 Retract
0011 Float
0100-1110 Reserved
1111 Don뭪 Care";
CM_ SG_ 2566798846 AuxValve13PortFlowCmd "The command to set the flow through the  extend or retract port of an auxiliary valve of a tractor, expressed as a percentage of full flow.  Zero percent indicates no flow, 100% indicates maximum flow, flow returns to the tractor through the ...";
CM_ BO_ 2566798590 "Auxiliary Valve Number 12 Command
This message provides control of the flow through the auxiliary valves.";
CM_ SG_ 2566798590 AuxValve12FailSafeModeCmd "Command for setting the fail safe mode of an auxiliary valve.

00 Block
01 Float
10 Reserved
11 Don뭪 Care";
CM_ SG_ 2566798590 AuxValve12StateCmd "Command for setting the auxiliary valve state.  With float enabled, hydraulic fluid may flow to or from the tractor as driven by the implement.

0000 Block
0001 Extend
0010 Retract
0011 Float
0100-1110 Reserved
1111 Don뭪 Care";
CM_ SG_ 2566798590 AuxValve12PortFlowCmd "The command to set the flow through the  extend or retract port of an auxiliary valve of a tractor, expressed as a percentage of full flow.  Zero percent indicates no flow, 100% indicates maximum flow, flow returns to the tractor through the ...";
CM_ BO_ 2566798334 "Auxiliary Valve Number 11 Command
This message provides control of the flow through the auxiliary valves.";
CM_ SG_ 2566798334 AuxValve11FailSafeModeCmd "Command for setting the fail safe mode of an auxiliary valve.

00 Block
01 Float
10 Reserved
11 Don뭪 Care";
CM_ SG_ 2566798334 AuxValve11StateCmd "Command for setting the auxiliary valve state.  With float enabled, hydraulic fluid may flow to or from the tractor as driven by the implement.

0000 Block
0001 Extend
0010 Retract
0011 Float
0100-1110 Reserved
1111 Don뭪 Care";
CM_ SG_ 2566798334 AuxValve11PortFlowCmd "The command to set the flow through the  extend or retract port of an auxiliary valve of a tractor, expressed as a percentage of full flow.  Zero percent indicates no flow, 100% indicates maximum flow, flow returns to the tractor through the ...";
CM_ BO_ 2566798078 "Auxiliary Valve Number 10 Command
This message provides control of the flow through the auxiliary valves.";
CM_ SG_ 2566798078 AuxValve10FailSafeModeCmd "Command for setting the fail safe mode of an auxiliary valve.

00 Block
01 Float
10 Reserved
11 Don뭪 Care";
CM_ SG_ 2566798078 AuxValve10StateCmd "Command for setting the auxiliary valve state.  With float enabled, hydraulic fluid may flow to or from the tractor as driven by the implement.

0000 Block
0001 Extend
0010 Retract
0011 Float
0100-1110 Reserved
1111 Don뭪 Care";
CM_ SG_ 2566798078 AuxValve10PortFlowCmd "The command to set the flow through the  extend or retract port of an auxiliary valve of a tractor, expressed as a percentage of full flow.  Zero percent indicates no flow, 100% indicates maximum flow, flow returns to the tractor through the ...";
CM_ BO_ 2566797822 "Auxiliary Valve Number 9 Command
This message provides control of the flow through the auxiliary valves.";
CM_ SG_ 2566797822 AuxValve9FailSafeModeCmd "Command for setting the fail safe mode of an auxiliary valve.

00 Block
01 Float
10 Reserved
11 Don뭪 Care";
CM_ SG_ 2566797822 AuxValve9StateCmd "Command for setting the auxiliary valve state.  With float enabled, hydraulic fluid may flow to or from the tractor as driven by the implement.

0000 Block
0001 Extend
0010 Retract
0011 Float
0100-1110 Reserved
1111 Don뭪 Care";
CM_ SG_ 2566797822 AuxValve9PortFlowCmd "The command to set the flow through the  extend or retract port of an auxiliary valve of a tractor, expressed as a percentage of full flow.  Zero percent indicates no flow, 100% indicates maximum flow, flow returns to the tractor through the ...";
CM_ BO_ 2566797566 "Auxiliary Valve Number 8 Command
This message provides control of the flow through the auxiliary valves.";
CM_ SG_ 2566797566 AuxValve8FailSafeModeCmd "Command for setting the fail safe mode of an auxiliary valve.

00 Block
01 Float
10 Reserved
11 Don뭪 Care";
CM_ SG_ 2566797566 AuxValve8StateCmd "Command for setting the auxiliary valve state.  With float enabled, hydraulic fluid may flow to or from the tractor as driven by the implement.

0000 Block
0001 Extend
0010 Retract
0011 Float
0100-1110 Reserved
1111 Don뭪 Care";
CM_ SG_ 2566797566 AuxValve8PortFlowCmd "The command to set the flow through the  extend or retract port of an auxiliary valve of a tractor, expressed as a percentage of full flow.  Zero percent indicates no flow, 100% indicates maximum flow, flow returns to the tractor through the ...";
BA_DEF_ SG_  "SigType" ENUM  "Default","Range","RangeSigned","ASCII","Discrete","Control","ReferencePGN","DTC","StringDelimiter","StringLength","StringLengthControl","MessageCounter","MessageChecksum";
BA_DEF_ SG_  "GenSigStartValue" INT 0 2147483647;
BA_DEF_ SG_  "GenSigSendType" ENUM  "Cyclic","OnWrite","OnWriteWithRepetition","OnChange","OnChangeWithRepetition","IfActive","IfActiveWithRepetition","NoSigSendType";
BA_DEF_ SG_  "GenSigILSupport" ENUM  "No","Yes";
BA_DEF_ SG_  "GenSigEVName" STRING ;
BA_DEF_ SG_  "SPN" INT 0 524287;
BA_DEF_ BO_  "TpJ1939VarDlc" ENUM  "No","Yes";
BA_DEF_ BO_  "GenMsgStartDelayTime" INT 0 100000;
BA_DEF_ BO_  "GenMsgILSupport" ENUM  "No","Yes";
BA_DEF_ BO_  "GenMsgDelayTime" INT 0 1000;
BA_DEF_ BO_  "GenMsgRequestable" INT 0 1;
BA_DEF_ BO_  "GenMsgSendType" ENUM  "cyclic","NotUsed","NotUsed","NotUsed","NotUsed","NotUsed","NotUsed","IfActive","noMsgSendType";
BA_DEF_ BO_  "VFrameFormat" ENUM  "StandardCAN","ExtendedCAN","reserved","J1939PG";
BA_DEF_ BO_  "GenMsgCycleTime" INT 0 3600000;
BA_DEF_ SG_  "SystemSignalLongSymbol" STRING ;
BA_DEF_DEF_  "SigType" "Default";
BA_DEF_DEF_  "GenSigStartValue" 0;
BA_DEF_DEF_  "GenSigSendType" "NoSigSendType";
BA_DEF_DEF_  "GenSigILSupport" "Yes";
BA_DEF_DEF_  "GenSigEVName" "Env@Nodename_@Signame";
BA_DEF_DEF_  "SPN" 0;
BA_DEF_DEF_  "TpJ1939VarDlc" "No";
BA_DEF_DEF_  "GenMsgStartDelayTime" 0;
BA_DEF_DEF_  "GenMsgILSupport" "Yes";
BA_DEF_DEF_  "GenMsgDelayTime" 0;
BA_DEF_DEF_  "GenMsgRequestable" 1;
BA_DEF_DEF_  "GenMsgSendType" "noMsgSendType";
BA_DEF_DEF_  "VFrameFormat" "J1939PG";
BA_DEF_DEF_  "GenMsgCycleTime" 0;
BA_DEF_DEF_  "SystemSignalLongSymbol" "";
BA_ "TpJ1939VarDlc" BO_ 2566670078 1;
BA_ "GenMsgCycleTime" BO_ 2566669054 10000;
BA_ "GenMsgSendType" BO_ 2566669054 0;
BA_ "GenMsgCycleTime" BO_ 2566668798 500;
BA_ "GenMsgSendType" BO_ 2566668798 0;
BA_ "GenMsgCycleTime" BO_ 2566668542 500;
BA_ "GenMsgSendType" BO_ 2566668542 0;
BA_ "GenMsgCycleTime" BO_ 2566668030 1000;
BA_ "GenMsgSendType" BO_ 2566668030 0;
BA_ "GenMsgCycleTime" BO_ 2566667774 1000;
BA_ "GenMsgSendType" BO_ 2566667774 0;
BA_ "GenMsgCycleTime" BO_ 2566667518 1000;
BA_ "GenMsgSendType" BO_ 2566667518 0;
BA_ "GenMsgCycleTime" BO_ 2566667262 1000;
BA_ "GenMsgSendType" BO_ 2566667262 0;
BA_ "GenMsgCycleTime" BO_ 2499558142 500;
BA_ "GenMsgSendType" BO_ 2499558142 0;
BA_ "GenMsgCycleTime" BO_ 2499557886 500;
BA_ "GenMsgSendType" BO_ 2499557886 0;
BA_ "GenMsgCycleTime" BO_ 2499557630 500;
BA_ "GenMsgSendType" BO_ 2499557630 0;
BA_ "GenMsgCycleTime" BO_ 2499557374 500;
BA_ "GenMsgSendType" BO_ 2499557374 0;
BA_ "GenMsgCycleTime" BO_ 2499557118 500;
BA_ "GenMsgSendType" BO_ 2499557118 0;
BA_ "GenMsgCycleTime" BO_ 2566665726 500;
BA_ "GenMsgSendType" BO_ 2566665726 0;
BA_ "GenMsgCycleTime" BO_ 2499556606 500;
BA_ "GenMsgSendType" BO_ 2499556606 0;
BA_ "GenMsgCycleTime" BO_ 2499556350 500;
BA_ "GenMsgSendType" BO_ 2499556350 0;
BA_ "GenMsgCycleTime" BO_ 2499556094 250;
BA_ "GenMsgSendType" BO_ 2499556094 0;
BA_ "GenMsgCycleTime" BO_ 2566664702 1000;
BA_ "GenMsgSendType" BO_ 2566664702 0;
BA_ "GenMsgDelayTime" BO_ 2566664702 100;
BA_ "GenMsgCycleTime" BO_ 2633773054 1000;
BA_ "GenMsgSendType" BO_ 2633773054 0;
BA_ "GenMsgCycleTime" BO_ 2566663934 500;
BA_ "GenMsgSendType" BO_ 2566663934 0;
BA_ "GenMsgCycleTime" BO_ 2566663678 500;
BA_ "GenMsgSendType" BO_ 2566663678 0;
BA_ "GenMsgCycleTime" BO_ 2566663422 1000;
BA_ "GenMsgSendType" BO_ 2566663422 0;
BA_ "GenMsgCycleTime" BO_ 2566663166 1000;
BA_ "GenMsgSendType" BO_ 2566663166 0;
BA_ "GenMsgCycleTime" BO_ 2566662910 10000;
BA_ "GenMsgSendType" BO_ 2566662910 0;
BA_ "GenMsgCycleTime" BO_ 2566662654 100;
BA_ "GenMsgSendType" BO_ 2566662654 0;
BA_ "GenMsgCycleTime" BO_ 2566662142 1000;
BA_ "GenMsgSendType" BO_ 2566662142 0;
BA_ "GenMsgCycleTime" BO_ 2566661630 1000;
BA_ "GenMsgSendType" BO_ 2566661630 0;
BA_ "GenMsgCycleTime" BO_ 2566661374 1000;
BA_ "GenMsgSendType" BO_ 2566661374 0;
BA_ "GenMsgCycleTime" BO_ 2364598270 100;
BA_ "GenMsgSendType" BO_ 2364598270 0;
BA_ "GenMsgCycleTime" BO_ 2364598014 100;
BA_ "GenMsgSendType" BO_ 2364598014 0;
BA_ "GenMsgCycleTime" BO_ 2364597758 100;
BA_ "GenMsgSendType" BO_ 2364597758 0;
BA_ "GenMsgCycleTime" BO_ 2364593150 100;
BA_ "GenMsgSendType" BO_ 2364593150 0;
BA_ "GenMsgCycleTime" BO_ 2364592894 100;
BA_ "GenMsgSendType" BO_ 2364592894 0;
BA_ "GenMsgCycleTime" BO_ 2364592638 100;
BA_ "GenMsgSendType" BO_ 2364592638 0;
BA_ "GenMsgCycleTime" BO_ 2364592382 1000;
BA_ "GenMsgSendType" BO_ 2364592382 0;
BA_ "GenMsgCycleTime" BO_ 2364567294 50;
BA_ "GenMsgSendType" BO_ 2364567294 0;
BA_ "GenMsgCycleTime" BO_ 2558918398 1000;
BA_ "GenMsgSendType" BO_ 2558918398 0;
BA_ "GenMsgDelayTime" BO_ 2558918398 100;
BA_ "GenMsgCycleTime" BO_ 2558852862 200;
BA_ "GenMsgSendType" BO_ 2558852862 0;
BA_ "GenMsgCycleTime" BO_ 2558656254 1000;
BA_ "GenMsgSendType" BO_ 2558656254 0;
BA_ "GenMsgDelayTime" BO_ 2558656254 100;
BA_ "GenMsgCycleTime" BO_ 2558590718 1000;
BA_ "GenMsgSendType" BO_ 2558590718 0;
BA_ "GenMsgDelayTime" BO_ 2558590718 100;
BA_ "GenMsgCycleTime" BO_ 2350710526 100;
BA_ "GenMsgSendType" BO_ 2350710526 0;
BA_ "GenMsgDelayTime" BO_ 2350710526 10;
BA_ "TpJ1939VarDlc" BO_ 2582642430 1;
BA_ "SPN" SG_ 2566670334 Axle12MonitoredTireCount 6962;
BA_ "SPN" SG_ 2566670334 Axle11MonitoredTireCount 6961;
BA_ "SPN" SG_ 2566670334 Axle10MonitoredTireCount 6960;
BA_ "SPN" SG_ 2566670334 Axle9MonitoredTireCount 6959;
BA_ "SPN" SG_ 2566670334 Axle8MonitoredTireCount 6958;
BA_ "SPN" SG_ 2566670334 Axle7MonitoredTireCount 6957;
BA_ "SPN" SG_ 2566670334 Axle6MonitoredTireCount 6956;
BA_ "SPN" SG_ 2566670334 Axle5MonitoredTireCount 6955;
BA_ "SPN" SG_ 2566670334 Axle4MonitoredTireCount 6954;
BA_ "SPN" SG_ 2566670334 Axle3MonitoredTireCount 6953;
BA_ "SPN" SG_ 2566670334 Axle2MonitoredTireCount 6952;
BA_ "SPN" SG_ 2566670334 Axle1MonitoredTireCount 6951;
BA_ "SPN" SG_ 2566670334 NumberOfTiresOnTheVehicle 6950;
BA_ "SigType" SG_ 2566670334 NumberOfTiresOnTheVehicle 1;
BA_ "SPN" SG_ 2566670334 NumberOfAxlesOnTheVehicle 6949;
BA_ "SPN" SG_ 2566670078 TireSensorIdentificationNumber 6966;
BA_ "SigType" SG_ 2566670078 TireSensorIdentificationNumber 8;
BA_ "SPN" SG_ 2566670078 TireSensorLocation 6965;
BA_ "SPN" SG_ 2566670078 TireSensorTireNumber 6964;
BA_ "SigType" SG_ 2566670078 TireSensorTireNumber 1;
BA_ "SPN" SG_ 2566670078 NumberOfTireSensors 6963;
BA_ "SigType" SG_ 2566670078 NumberOfTireSensors 1;
BA_ "SPN" SG_ 2566669822 TrWrelessSignalStrengthIndicator 6972;
BA_ "SigType" SG_ 2566669822 TrWrelessSignalStrengthIndicator 1;
BA_ "SPN" SG_ 2566669822 TireLocation 6971;
BA_ "SPN" SG_ 2566669822 TireSensorNumber 6970;
BA_ "SigType" SG_ 2566669822 TireSensorNumber 1;
BA_ "SPN" SG_ 2566669822 TtalNumberOfTireSensorsMonitored 6969;
BA_ "SigType" SG_ 2566669822 TtalNumberOfTireSensorsMonitored 1;
BA_ "SPN" SG_ 2566669822 AntennaNumber 6968;
BA_ "SigType" SG_ 2566669822 AntennaNumber 1;
BA_ "SPN" SG_ 2566669822 TotalNumberOfAntennasUsed 6967;
BA_ "SigType" SG_ 2566669822 TotalNumberOfAntennasUsed 1;
BA_ "SPN" SG_ 2566669310 OverTemp 6984;
BA_ "SigType" SG_ 2566669310 OverTemp 1;
BA_ "SPN" SG_ 2566669310 OverPressPercentageThreshold 6983;
BA_ "SigType" SG_ 2566669310 OverPressPercentageThreshold 1;
BA_ "SPN" SG_ 2566669310 ExtrmUndrPrssPercentageThreshold 6982;
BA_ "SigType" SG_ 2566669310 ExtrmUndrPrssPercentageThreshold 1;
BA_ "SPN" SG_ 2566669310 UnderPressPercentageThreshold 6981;
BA_ "SigType" SG_ 2566669310 UnderPressPercentageThreshold 1;
BA_ "SPN" SG_ 2566669310 ColdInflationPress 6980;
BA_ "SigType" SG_ 2566669310 ColdInflationPress 1;
BA_ "SPN" SG_ 2566669310 TireLocation 6979;
BA_ "SPN" SG_ 2566669054 RequiredTirePress 6989;
BA_ "SigType" SG_ 2566669054 RequiredTirePress 1;
BA_ "SPN" SG_ 2566669054 TirePress 6988;
BA_ "SigType" SG_ 2566669054 TirePress 1;
BA_ "SPN" SG_ 2566669054 TireLocation 6987;
BA_ "SPN" SG_ 2566668798 EngFl2InjctorMeteringRail1Press2 7513;
BA_ "SigType" SG_ 2566668798 EngFl2InjctorMeteringRail1Press2 1;
BA_ "SPN" SG_ 2566668798 EngFel2InjectorMeteringRail2Temp 7024;
BA_ "SigType" SG_ 2566668798 EngFel2InjectorMeteringRail2Temp 1;
BA_ "SPN" SG_ 2566668798 EngFel2InjectorMeteringRail1Temp 7023;
BA_ "SigType" SG_ 2566668798 EngFel2InjectorMeteringRail1Temp 1;
BA_ "SPN" SG_ 2566668798 EngFl2InjectorMeteringRail2Press 7022;
BA_ "SigType" SG_ 2566668798 EngFl2InjectorMeteringRail2Press 1;
BA_ "SPN" SG_ 2566668798 EngFl2InjectorMeteringRail1Press 7021;
BA_ "SigType" SG_ 2566668798 EngFl2InjectorMeteringRail1Press 1;
BA_ "SPN" SG_ 2566668542 EngFuel2PumpHydPress 7019;
BA_ "SigType" SG_ 2566668542 EngFuel2PumpHydPress 1;
BA_ "SPN" SG_ 2566668542 EngFuel2PumpHydDirectionalValve 7018;
BA_ "SigType" SG_ 2566668542 EngFuel2PumpHydDirectionalValve 1;
BA_ "SPN" SG_ 2566668542 EngFuel2PumpHydSwashPlateAngle 7017;
BA_ "SigType" SG_ 2566668542 EngFuel2PumpHydSwashPlateAngle 1;
BA_ "SPN" SG_ 2566668542 EngFuel2PumpHydFlowCtrlValve 7016;
BA_ "SigType" SG_ 2566668542 EngFuel2PumpHydFlowCtrlValve 1;
BA_ "SPN" SG_ 2566668286 EngStagedTurboSolenoidStatus 7025;
BA_ "SigType" SG_ 2566668286 EngStagedTurboSolenoidStatus 1;
BA_ "SPN" SG_ 2566668030 HtExchngerDebrisPurgeApproaching 7036;
BA_ "SigType" SG_ 2566668030 HtExchngerDebrisPurgeApproaching 5;
BA_ "SPN" SG_ 2566668030 HeatExchangerDebrisPurgeStatus 7035;
BA_ "SigType" SG_ 2566668030 HeatExchangerDebrisPurgeStatus 5;
BA_ "SPN" SG_ 2566667774 EngEndBearing8Temp 7050;
BA_ "SigType" SG_ 2566667774 EngEndBearing8Temp 1;
BA_ "SPN" SG_ 2566667774 EngEndBearing7Temp 7049;
BA_ "SigType" SG_ 2566667774 EngEndBearing7Temp 1;
BA_ "SPN" SG_ 2566667774 EngEndBearing6Temp 7048;
BA_ "SigType" SG_ 2566667774 EngEndBearing6Temp 1;
BA_ "SPN" SG_ 2566667774 EngEndBearing5Temp 7047;
BA_ "SigType" SG_ 2566667774 EngEndBearing5Temp 1;
BA_ "SPN" SG_ 2566667774 EngEndBearing4Temp 7046;
BA_ "SigType" SG_ 2566667774 EngEndBearing4Temp 1;
BA_ "SPN" SG_ 2566667774 EngEndBearing3Temp 7045;
BA_ "SigType" SG_ 2566667774 EngEndBearing3Temp 1;
BA_ "SPN" SG_ 2566667774 EngEndBearing2Temp 7044;
BA_ "SigType" SG_ 2566667774 EngEndBearing2Temp 1;
BA_ "SPN" SG_ 2566667774 EngEndBearing1Temp 7043;
BA_ "SigType" SG_ 2566667774 EngEndBearing1Temp 1;
BA_ "SPN" SG_ 2566667518 EngEndBearing16Temp 7058;
BA_ "SigType" SG_ 2566667518 EngEndBearing16Temp 1;
BA_ "SPN" SG_ 2566667518 EngEndBearing15Temp 7057;
BA_ "SigType" SG_ 2566667518 EngEndBearing15Temp 1;
BA_ "SPN" SG_ 2566667518 EngEndBearing14Temp 7056;
BA_ "SigType" SG_ 2566667518 EngEndBearing14Temp 1;
BA_ "SPN" SG_ 2566667518 EngEndBearing13Temp 7055;
BA_ "SigType" SG_ 2566667518 EngEndBearing13Temp 1;
BA_ "SPN" SG_ 2566667518 EngEndBearing12Temp 7054;
BA_ "SigType" SG_ 2566667518 EngEndBearing12Temp 1;
BA_ "SPN" SG_ 2566667518 EngEndBearing11Temp 7053;
BA_ "SigType" SG_ 2566667518 EngEndBearing11Temp 1;
BA_ "SPN" SG_ 2566667518 EngEndBearing10Temp 7052;
BA_ "SigType" SG_ 2566667518 EngEndBearing10Temp 1;
BA_ "SPN" SG_ 2566667518 EngEndBearing9Temp 7051;
BA_ "SigType" SG_ 2566667518 EngEndBearing9Temp 1;
BA_ "SPN" SG_ 2566667262 EngEndBearing20Temp 7062;
BA_ "SigType" SG_ 2566667262 EngEndBearing20Temp 1;
BA_ "SPN" SG_ 2566667262 EngEndBearing19Temp 7061;
BA_ "SigType" SG_ 2566667262 EngEndBearing19Temp 1;
BA_ "SPN" SG_ 2566667262 EngEndBearing18Temp 7060;
BA_ "SigType" SG_ 2566667262 EngEndBearing18Temp 1;
BA_ "SPN" SG_ 2566667262 EngEndBearing17Temp 7059;
BA_ "SigType" SG_ 2566667262 EngEndBearing17Temp 1;
BA_ "SPN" SG_ 2499558142 GsFlSpplyShtoffValve2IntakePress 7066;
BA_ "SigType" SG_ 2499558142 GsFlSpplyShtoffValve2IntakePress 1;
BA_ "SPN" SG_ 2499558142 GsFlSpplyShtoffValve1IntakePress 7065;
BA_ "SigType" SG_ 2499558142 GsFlSpplyShtoffValve1IntakePress 1;
BA_ "SPN" SG_ 2499558142 GasFuelSupplyUnitIntakePress 7064;
BA_ "SigType" SG_ 2499558142 GasFuelSupplyUnitIntakePress 1;
BA_ "SPN" SG_ 2499558142 EngGasFuelSupplyPress2 7063;
BA_ "SigType" SG_ 2499558142 EngGasFuelSupplyPress2 1;
BA_ "SPN" SG_ 2499557886 PlantInertGasSupplyOutletPress 7068;
BA_ "SigType" SG_ 2499557886 PlantInertGasSupplyOutletPress 1;
BA_ "SPN" SG_ 2499557886 PlantGasFuelSupplyOutletPress 7067;
BA_ "SigType" SG_ 2499557886 PlantGasFuelSupplyOutletPress 1;
BA_ "SPN" SG_ 2499557630 EngOilMist8Concentration 7078;
BA_ "SigType" SG_ 2499557630 EngOilMist8Concentration 1;
BA_ "SPN" SG_ 2499557630 EngOilMist7Concentration 7077;
BA_ "SigType" SG_ 2499557630 EngOilMist7Concentration 1;
BA_ "SPN" SG_ 2499557630 EngOilMist6Concentration 7076;
BA_ "SigType" SG_ 2499557630 EngOilMist6Concentration 1;
BA_ "SPN" SG_ 2499557630 EngOilMist5Concentration 7075;
BA_ "SigType" SG_ 2499557630 EngOilMist5Concentration 1;
BA_ "SPN" SG_ 2499557630 EngOilMist4Concentration 7074;
BA_ "SigType" SG_ 2499557630 EngOilMist4Concentration 1;
BA_ "SPN" SG_ 2499557630 EngOilMist3Concentration 7073;
BA_ "SigType" SG_ 2499557630 EngOilMist3Concentration 1;
BA_ "SPN" SG_ 2499557630 EngOilMist2Concentration 7072;
BA_ "SigType" SG_ 2499557630 EngOilMist2Concentration 1;
BA_ "SPN" SG_ 2499557630 EngOilMist1Concentration 7071;
BA_ "SigType" SG_ 2499557630 EngOilMist1Concentration 1;
BA_ "SPN" SG_ 2499557374 EngOilMist10Concentration 7080;
BA_ "SigType" SG_ 2499557374 EngOilMist10Concentration 1;
BA_ "SPN" SG_ 2499557374 EngOilMist9Concentration 7079;
BA_ "SigType" SG_ 2499557374 EngOilMist9Concentration 1;
BA_ "SPN" SG_ 2499557118 InertGasSupplyValvePos 7442;
BA_ "SigType" SG_ 2499557118 InertGasSupplyValvePos 1;
BA_ "SPN" SG_ 2499557118 GasFuelSupplyBleedValve3Pos 7085;
BA_ "SigType" SG_ 2499557118 GasFuelSupplyBleedValve3Pos 1;
BA_ "SPN" SG_ 2499557118 GasFuelSupplyBleedValve2Pos 7084;
BA_ "SigType" SG_ 2499557118 GasFuelSupplyBleedValve2Pos 1;
BA_ "SPN" SG_ 2499557118 GasFuelSupplyBleedValve1Pos 7083;
BA_ "SigType" SG_ 2499557118 GasFuelSupplyBleedValve1Pos 1;
BA_ "SPN" SG_ 2499557118 GasFuelSupplyShutoffValve2Pos 7082;
BA_ "SigType" SG_ 2499557118 GasFuelSupplyShutoffValve2Pos 1;
BA_ "SPN" SG_ 2499557118 GasFuelSupplyShutoffValve1Pos 7081;
BA_ "SigType" SG_ 2499557118 GasFuelSupplyShutoffValve1Pos 1;
BA_ "SPN" SG_ 2566665726 TwoMotorSpd 7466;
BA_ "SigType" SG_ 2566665726 TwoMotorSpd 1;
BA_ "SPN" SG_ 2566665726 Htr 7086;
BA_ "SigType" SG_ 2566665726 Htr 1;
BA_ "SPN" SG_ 2499556606 EngInjectorMeteringRail2Press2 7099;
BA_ "SigType" SG_ 2499556606 EngInjectorMeteringRail2Press2 1;
BA_ "SPN" SG_ 2499556606 EngInjectorMeteringRail2Press1 7098;
BA_ "SigType" SG_ 2499556606 EngInjectorMeteringRail2Press1 1;
BA_ "SPN" SG_ 2499556606 EngInjectorMeteringRail1Press2 7097;
BA_ "SigType" SG_ 2499556606 EngInjectorMeteringRail1Press2 1;
BA_ "SPN" SG_ 2499556606 EngInjectorMeteringRail1Press1 7096;
BA_ "SigType" SG_ 2499556606 EngInjectorMeteringRail1Press1 1;
BA_ "SPN" SG_ 2499556350 EngInjctrMtringRail2DesiredPress 7101;
BA_ "SigType" SG_ 2499556350 EngInjctrMtringRail2DesiredPress 1;
BA_ "SPN" SG_ 2499556350 EngInjctrMtringRail1DesiredPress 7100;
BA_ "SigType" SG_ 2499556350 EngInjctrMtringRail1DesiredPress 1;
BA_ "SPN" SG_ 2499556094 HtrPwrSupplyDiagStatus 7330;
BA_ "SPN" SG_ 2499556094 HtrPwrSupplyPreliminaryFMI 7329;
BA_ "SPN" SG_ 2499556094 PwrSupplyDiagStatus 7328;
BA_ "SPN" SG_ 2499556094 PwrSupplyPreliminaryFMI 7327;
BA_ "SPN" SG_ 2499556094 InputDiagStatus 7326;
BA_ "SPN" SG_ 2499556094 InputPreliminaryFMI 7325;
BA_ "SPN" SG_ 2499556094 HtrLowSideDriverDiagStatus 7324;
BA_ "SPN" SG_ 2499556094 HtrLowSideDriverPreliminaryFMI 7323;
BA_ "SPN" SG_ 2499556094 HtrHiSideDriverDiagStatus 7322;
BA_ "SPN" SG_ 2499556094 HtrHiSideDriverPreliminaryFMI 7321;
BA_ "SPN" SG_ 2566664702 DEFDosingModeStatus 9176;
BA_ "SPN" SG_ 2566664702 DEFQualityMalfunctionEPActive 7899;
BA_ "SigType" SG_ 2566664702 DEFQualityMalfunctionEPActive 5;
BA_ "SPN" SG_ 2566664702 DEFTankTemp 7607;
BA_ "SigType" SG_ 2566664702 DEFTankTemp 1;
BA_ "SPN" SG_ 2566664702 DEFTankVolume 7606;
BA_ "SigType" SG_ 2566664702 DEFTankVolume 1;
BA_ "SPN" SG_ 2566664702 DEFHtrCircuitBreaker 7588;
BA_ "SigType" SG_ 2566664702 DEFHtrCircuitBreaker 5;
BA_ "SPN" SG_ 2566664702 AAT 7441;
BA_ "SigType" SG_ 2566664702 AAT 1;
BA_ "SPN" SG_ 2566664702 EngLoadReq 7503;
BA_ "SigType" SG_ 2566664702 EngLoadReq 5;
BA_ "SPN" SG_ 2566664702 EngSpdIncreaseReq 7502;
BA_ "SigType" SG_ 2566664702 EngSpdIncreaseReq 5;
BA_ "SPN" SG_ 2566664702 ActiveRegenInhibitedDueToLowEP 7440;
BA_ "SigType" SG_ 2566664702 ActiveRegenInhibitedDueToLowEP 5;
BA_ "SPN" SG_ 2566664702 ThermalMnmgtStatus 7332;
BA_ "SigType" SG_ 2566664702 ThermalMnmgtStatus 5;
BA_ "SPN" SG_ 2633773310 SCROprtrIndcmntOvrrdTmeRemaining 7344;
BA_ "SigType" SG_ 2633773310 SCROprtrIndcmntOvrrdTmeRemaining 1;
BA_ "SPN" SG_ 2633773310 SCROprtrIndcmntOvrrdRnwlRequired 7343;
BA_ "SigType" SG_ 2633773310 SCROprtrIndcmntOvrrdRnwlRequired 5;
BA_ "SPN" SG_ 2633773310 SCROpratorInducementOverrideMode 7342;
BA_ "SPN" SG_ 2633773310 SCROprtrIndcmntEmrgncyOvrrdTtlRs 7341;
BA_ "SigType" SG_ 2633773310 SCROprtrIndcmntEmrgncyOvrrdTtlRs 1;
BA_ "SPN" SG_ 2633773054 FrSpprssnCmprssdArFmSystmArPress 7350;
BA_ "SigType" SG_ 2633773054 FrSpprssnCmprssdArFmSystmArPress 1;
BA_ "SPN" SG_ 2633773054 FrSuppressionClassBFoamTankLevel 7349;
BA_ "SigType" SG_ 2633773054 FrSuppressionClassBFoamTankLevel 1;
BA_ "SPN" SG_ 2633773054 FrSuppressionClassAFoamTankLevel 7348;
BA_ "SigType" SG_ 2633773054 FrSuppressionClassAFoamTankLevel 1;
BA_ "SPN" SG_ 2633773054 FireSuppressionWaterTankLevel 7347;
BA_ "SigType" SG_ 2633773054 FireSuppressionWaterTankLevel 1;
BA_ "SPN" SG_ 2566663934 WastegateAct2MotorCurDis 7710;
BA_ "SigType" SG_ 2566663934 WastegateAct2MotorCurDis 5;
BA_ "SPN" SG_ 2566663934 CompressorBypassAct2MotorCurDis 7709;
BA_ "SigType" SG_ 2566663934 CompressorBypassAct2MotorCurDis 5;
BA_ "SPN" SG_ 2566663934 CompressorBypassAct1MotorCurDis 7708;
BA_ "SigType" SG_ 2566663934 CompressorBypassAct1MotorCurDis 5;
BA_ "SPN" SG_ 2566663934 EngThrttlVlv1MotorCurrentDisable 7383;
BA_ "SigType" SG_ 2566663934 EngThrttlVlv1MotorCurrentDisable 5;
BA_ "SPN" SG_ 2566663934 EngCylHdBypssActtr1MtrCrrntDsble 7382;
BA_ "SigType" SG_ 2566663934 EngCylHdBypssActtr1MtrCrrntDsble 5;
BA_ "SPN" SG_ 2566663934 EngTrbWstgtActtr1MtrCrrntDisable 7381;
BA_ "SigType" SG_ 2566663934 EngTrbWstgtActtr1MtrCrrntDisable 5;
BA_ "SPN" SG_ 2566663934 EngTrbCmprssrBlwffActtr1MtrCrrnt 7380;
BA_ "SigType" SG_ 2566663934 EngTrbCmprssrBlwffActtr1MtrCrrnt 5;
BA_ "SPN" SG_ 2566663678 EngFl2InjectorMeteringRail1Temp2 7514;
BA_ "SigType" SG_ 2566663678 EngFl2InjectorMeteringRail1Temp2 1;
BA_ "SPN" SG_ 2566663678 LNGTank2VaporPress 6788;
BA_ "SigType" SG_ 2566663678 LNGTank2VaporPress 1;
BA_ "SPN" SG_ 2566663678 LNGTank1VaporPress 6787;
BA_ "SigType" SG_ 2566663678 LNGTank1VaporPress 1;
BA_ "SPN" SG_ 2566663422 TrlrBrkClprLnngClranceAxle5Right 7415;
BA_ "SigType" SG_ 2566663422 TrlrBrkClprLnngClranceAxle5Right 4;
BA_ "SPN" SG_ 2566663422 TrlrBrkClprLnngClaranceAxle5Left 7414;
BA_ "SigType" SG_ 2566663422 TrlrBrkClprLnngClaranceAxle5Left 4;
BA_ "SPN" SG_ 2566663422 TrlrBrkClprLnngClranceAxle4Right 7413;
BA_ "SigType" SG_ 2566663422 TrlrBrkClprLnngClranceAxle4Right 4;
BA_ "SPN" SG_ 2566663422 TrlrBrkClprLnngClaranceAxle4Left 7412;
BA_ "SigType" SG_ 2566663422 TrlrBrkClprLnngClaranceAxle4Left 4;
BA_ "SPN" SG_ 2566663422 TrlrBrkClprLnngClranceAxle3Right 7411;
BA_ "SigType" SG_ 2566663422 TrlrBrkClprLnngClranceAxle3Right 4;
BA_ "SPN" SG_ 2566663422 TrlrBrkClprLnngClaranceAxle3Left 7410;
BA_ "SigType" SG_ 2566663422 TrlrBrkClprLnngClaranceAxle3Left 4;
BA_ "SPN" SG_ 2566663422 TrlrBrkClprLnngClranceAxle2Right 7409;
BA_ "SigType" SG_ 2566663422 TrlrBrkClprLnngClranceAxle2Right 4;
BA_ "SPN" SG_ 2566663422 TrlrBrkClprLnngClaranceAxle2Left 7408;
BA_ "SigType" SG_ 2566663422 TrlrBrkClprLnngClaranceAxle2Left 4;
BA_ "SPN" SG_ 2566663422 TrlrBrkClprLnngClranceAxle1Right 7407;
BA_ "SigType" SG_ 2566663422 TrlrBrkClprLnngClranceAxle1Right 4;
BA_ "SPN" SG_ 2566663422 TrlrBrkClprLnngClaranceAxle1Left 7406;
BA_ "SigType" SG_ 2566663422 TrlrBrkClprLnngClaranceAxle1Left 4;
BA_ "SPN" SG_ 2566663422 TrctrBrkClprLnngClrnceAxle5Right 7405;
BA_ "SigType" SG_ 2566663422 TrctrBrkClprLnngClrnceAxle5Right 4;
BA_ "SPN" SG_ 2566663422 TrctrBrkClprLnngClranceAxle5Left 7404;
BA_ "SigType" SG_ 2566663422 TrctrBrkClprLnngClranceAxle5Left 4;
BA_ "SPN" SG_ 2566663422 TrctrBrkClprLnngClrnceAxle4Right 7403;
BA_ "SigType" SG_ 2566663422 TrctrBrkClprLnngClrnceAxle4Right 4;
BA_ "SPN" SG_ 2566663422 TrctrBrkClprLnngClranceAxle4Left 7402;
BA_ "SigType" SG_ 2566663422 TrctrBrkClprLnngClranceAxle4Left 4;
BA_ "SPN" SG_ 2566663422 TrctrBrkClprLnngClrnceAxle3Right 7401;
BA_ "SigType" SG_ 2566663422 TrctrBrkClprLnngClrnceAxle3Right 4;
BA_ "SPN" SG_ 2566663422 TrctrBrkClprLnngClranceAxle3Left 7400;
BA_ "SigType" SG_ 2566663422 TrctrBrkClprLnngClranceAxle3Left 4;
BA_ "SPN" SG_ 2566663422 TrctrBrkClprLnngClrnceAxle2Right 7399;
BA_ "SigType" SG_ 2566663422 TrctrBrkClprLnngClrnceAxle2Right 4;
BA_ "SPN" SG_ 2566663422 TrctrBrkClprLnngClranceAxle2Left 7398;
BA_ "SigType" SG_ 2566663422 TrctrBrkClprLnngClranceAxle2Left 4;
BA_ "SPN" SG_ 2566663422 TrctrBrkClprLnngClrnceAxle1Right 7397;
BA_ "SigType" SG_ 2566663422 TrctrBrkClprLnngClrnceAxle1Right 4;
BA_ "SPN" SG_ 2566663422 TrctrBrkClprLnngClranceAxle1Left 7396;
BA_ "SigType" SG_ 2566663422 TrctrBrkClprLnngClranceAxle1Left 4;
BA_ "SPN" SG_ 2566663166 EngExtlIdleReqFeedback 8441;
BA_ "SigType" SG_ 2566663166 EngExtlIdleReqFeedback 4;
BA_ "SPN" SG_ 2566663166 CruiseCtrlAdjustedMaxSpeed 7495;
BA_ "SigType" SG_ 2566663166 CruiseCtrlAdjustedMaxSpeed 1;
BA_ "SPN" SG_ 2566663166 AppliedVehicleSpeedLimit 7420;
BA_ "SigType" SG_ 2566663166 AppliedVehicleSpeedLimit 1;
BA_ "SPN" SG_ 2566662910 TimeToFinalIndAction 7719;
BA_ "SigType" SG_ 2566662910 TimeToFinalIndAction 1;
BA_ "SPN" SG_ 2566662910 OprtrIndcmntTmTTrqueDerateLevel2 7428;
BA_ "SigType" SG_ 2566662910 OprtrIndcmntTmTTrqueDerateLevel2 1;
BA_ "SPN" SG_ 2566662910 OprtrIndcementTorqueDerateLevel2 7427;
BA_ "SigType" SG_ 2566662910 OprtrIndcementTorqueDerateLevel2 1;
BA_ "SPN" SG_ 2566662910 OprtrIndcmntTmTTrqueDerateLevel1 7426;
BA_ "SigType" SG_ 2566662910 OprtrIndcmntTmTTrqueDerateLevel1 1;
BA_ "SPN" SG_ 2566662910 OprtrIndcementTorqueDerateLevel1 7425;
BA_ "SigType" SG_ 2566662910 OprtrIndcementTorqueDerateLevel1 1;
BA_ "SPN" SG_ 2566662654 LeftLaneMarkerType 8144;
BA_ "SPN" SG_ 2566662654 RightLaneMarkerType 8143;
BA_ "SPN" SG_ 2566662654 LaneMarkQualityOnTheRightSide 7482;
BA_ "SPN" SG_ 2566662654 LaneMarkQualityOnTheLeftSide 7481;
BA_ "SPN" SG_ 2566662654 LaneDepartureAngleRight 7480;
BA_ "SigType" SG_ 2566662654 LaneDepartureAngleRight 1;
BA_ "SPN" SG_ 2566662654 LaneDepartureAngleLeft 7479;
BA_ "SigType" SG_ 2566662654 LaneDepartureAngleLeft 1;
BA_ "SPN" SG_ 2566662654 RoadCurvatureBasedOnLaneMarks 7478;
BA_ "SigType" SG_ 2566662654 RoadCurvatureBasedOnLaneMarks 1;
BA_ "SPN" SG_ 2566662654 RghtDstncTLnMrkFrmVehiclesMiddle 7477;
BA_ "SigType" SG_ 2566662654 RghtDstncTLnMrkFrmVehiclesMiddle 1;
BA_ "SPN" SG_ 2566662654 LftDstncTLnMrkFromVehiclesMiddle 7476;
BA_ "SigType" SG_ 2566662654 LftDstncTLnMrkFromVehiclesMiddle 1;
BA_ "SPN" SG_ 2566662142 Ctrl2Temp 7528;
BA_ "SigType" SG_ 2566662142 Ctrl2Temp 1;
BA_ "SPN" SG_ 2566662142 Ctrl1Temp 5480;
BA_ "SigType" SG_ 2566662142 Ctrl1Temp 1;
BA_ "SPN" SG_ 2566661630 Htr2 7573;
BA_ "SigType" SG_ 2566661630 Htr2 1;
BA_ "SPN" SG_ 2566661630 Temp2 7572;
BA_ "SigType" SG_ 2566661630 Temp2 1;
BA_ "SPN" SG_ 2566661630 Volume2 7530;
BA_ "SigType" SG_ 2566661630 Volume2 1;
BA_ "SPN" SG_ 2566661374 Htr2 7575;
BA_ "SigType" SG_ 2566661374 Htr2 1;
BA_ "SPN" SG_ 2566661374 Temp2 7574;
BA_ "SigType" SG_ 2566661374 Temp2 1;
BA_ "SPN" SG_ 2566661374 Volume2 7531;
BA_ "SigType" SG_ 2566661374 Volume2 1;
BA_ "SPN" SG_ 2364598270 EngCyl24TimingOffset 7379;
BA_ "SigType" SG_ 2364598270 EngCyl24TimingOffset 1;
BA_ "SPN" SG_ 2364598270 EngCyl23TimingOffset 7378;
BA_ "SigType" SG_ 2364598270 EngCyl23TimingOffset 1;
BA_ "SPN" SG_ 2364598270 EngCyl22TimingOffset 7377;
BA_ "SigType" SG_ 2364598270 EngCyl22TimingOffset 1;
BA_ "SPN" SG_ 2364598270 EngCyl21TimingOffset 7376;
BA_ "SigType" SG_ 2364598270 EngCyl21TimingOffset 1;
BA_ "SPN" SG_ 2364598270 EngCyl20TimingOffset 7375;
BA_ "SigType" SG_ 2364598270 EngCyl20TimingOffset 1;
BA_ "SPN" SG_ 2364598270 EngCyl19TimingOffset 7374;
BA_ "SigType" SG_ 2364598270 EngCyl19TimingOffset 1;
BA_ "SPN" SG_ 2364598270 EngCyl18TimingOffset 7373;
BA_ "SigType" SG_ 2364598270 EngCyl18TimingOffset 1;
BA_ "SPN" SG_ 2364598270 EngCyl17TimingOffset 7372;
BA_ "SigType" SG_ 2364598270 EngCyl17TimingOffset 1;
BA_ "SPN" SG_ 2364598014 EngCyl16TimingOffset 7371;
BA_ "SigType" SG_ 2364598014 EngCyl16TimingOffset 1;
BA_ "SPN" SG_ 2364598014 EngCyl15TimingOffset 7370;
BA_ "SigType" SG_ 2364598014 EngCyl15TimingOffset 1;
BA_ "SPN" SG_ 2364598014 EngCyl14TimingOffset 7369;
BA_ "SigType" SG_ 2364598014 EngCyl14TimingOffset 1;
BA_ "SPN" SG_ 2364598014 EngCyl13TimingOffset 7368;
BA_ "SigType" SG_ 2364598014 EngCyl13TimingOffset 1;
BA_ "SPN" SG_ 2364598014 EngCyl12TimingOffset 7367;
BA_ "SigType" SG_ 2364598014 EngCyl12TimingOffset 1;
BA_ "SPN" SG_ 2364598014 EngCyl11TimingOffset 7366;
BA_ "SigType" SG_ 2364598014 EngCyl11TimingOffset 1;
BA_ "SPN" SG_ 2364598014 EngCyl10TimingOffset 7365;
BA_ "SigType" SG_ 2364598014 EngCyl10TimingOffset 1;
BA_ "SPN" SG_ 2364598014 EngCyl9TimingOffset 7364;
BA_ "SigType" SG_ 2364598014 EngCyl9TimingOffset 1;
BA_ "SPN" SG_ 2364597758 EngCyl8TimingOffset 7363;
BA_ "SigType" SG_ 2364597758 EngCyl8TimingOffset 1;
BA_ "SPN" SG_ 2364597758 EngCyl7TimingOffset 7362;
BA_ "SigType" SG_ 2364597758 EngCyl7TimingOffset 1;
BA_ "SPN" SG_ 2364597758 EngCyl6TimingOffset 7361;
BA_ "SigType" SG_ 2364597758 EngCyl6TimingOffset 1;
BA_ "SPN" SG_ 2364597758 EngCyl5TimingOffset 7360;
BA_ "SigType" SG_ 2364597758 EngCyl5TimingOffset 1;
BA_ "SPN" SG_ 2364597758 EngCyl4TimingOffset 7359;
BA_ "SigType" SG_ 2364597758 EngCyl4TimingOffset 1;
BA_ "SPN" SG_ 2364597758 EngCyl3TimingOffset 7358;
BA_ "SigType" SG_ 2364597758 EngCyl3TimingOffset 1;
BA_ "SPN" SG_ 2364597758 EngCyl2TimingOffset 7357;
BA_ "SigType" SG_ 2364597758 EngCyl2TimingOffset 1;
BA_ "SPN" SG_ 2364597758 EngCyl1TimingOffset 7356;
BA_ "SigType" SG_ 2364597758 EngCyl1TimingOffset 1;
BA_ "SPN" SG_ 2364593150 RoadwayNextGradeDist 9199;
BA_ "SigType" SG_ 2364593150 RoadwayNextGradeDist 1;
BA_ "SPN" SG_ 2364593150 PrdctvCrsCtrlDrvlnDsnggInhibitRq 7430;
BA_ "SigType" SG_ 2364593150 PrdctvCrsCtrlDrvlnDsnggInhibitRq 5;
BA_ "SPN" SG_ 2364593150 VhclSpdCtrlOvrrideEventIndicator 7435;
BA_ "SigType" SG_ 2364593150 VhclSpdCtrlOvrrideEventIndicator 5;
BA_ "SPN" SG_ 2364593150 PrdctvCrsCtrlSpeedEventIndicator 7434;
BA_ "SigType" SG_ 2364593150 PrdctvCrsCtrlSpeedEventIndicator 5;
BA_ "SPN" SG_ 2364593150 PredictiveCruiseCtrlNextGrade 7433;
BA_ "SigType" SG_ 2364593150 PredictiveCruiseCtrlNextGrade 1;
BA_ "SPN" SG_ 2364593150 PredictiveCruiseCtrlPresentGrade 7432;
BA_ "SigType" SG_ 2364593150 PredictiveCruiseCtrlPresentGrade 1;
BA_ "SPN" SG_ 2364593150 PredictiveCruiseCtrlEventInRange 7431;
BA_ "SigType" SG_ 2364593150 PredictiveCruiseCtrlEventInRange 4;
BA_ "SPN" SG_ 2364593150 VehicleSpeedCtrlOverrideRq 7429;
BA_ "SigType" SG_ 2364593150 VehicleSpeedCtrlOverrideRq 5;
BA_ "SPN" SG_ 2364593150 PredictiveCruiseCtrlState 7317;
BA_ "SPN" SG_ 2364593150 PrdctiveCruiseCtrlSetSpeedOffset 7316;
BA_ "SigType" SG_ 2364593150 PrdctiveCruiseCtrlSetSpeedOffset 1;
BA_ "SPN" SG_ 2364592894 ExhGasRestrictionVlvPos 8151;
BA_ "SigType" SG_ 2364592894 ExhGasRestrictionVlvPos 1;
BA_ "SPN" SG_ 2364592894 InAirSourceVlv 6330;
BA_ "SigType" SG_ 2364592894 InAirSourceVlv 4;
BA_ "SPN" SG_ 2364592894 EngCylHeadBypassActuator1Cmd 7094;
BA_ "SigType" SG_ 2364592894 EngCylHeadBypassActuator1Cmd 1;
BA_ "SPN" SG_ 2364592638 EngCylHdBypssActtr1OprtionStatus 7093;
BA_ "SPN" SG_ 2364592638 EngCylHeadBypassActuator1Pos 7092;
BA_ "SigType" SG_ 2364592638 EngCylHeadBypassActuator1Pos 1;
BA_ "SPN" SG_ 2364592638 EngCylHdBypssActuator1DesiredPos 7091;
BA_ "SigType" SG_ 2364592638 EngCylHdBypssActuator1DesiredPos 1;
BA_ "SPN" SG_ 2364592638 EngCylHeadBypassActuator1Temp 7090;
BA_ "SigType" SG_ 2364592638 EngCylHeadBypassActuator1Temp 1;
BA_ "SPN" SG_ 2364592638 EngCylHdBypssActuator1TempStatus 7089;
BA_ "SPN" SG_ 2364592638 EngCylHdBypssActtr1PrliminaryFMI 7088;
BA_ "SPN" SG_ 2364592382 EngCyl24ExcludeFromCombustionRq 7015;
BA_ "SigType" SG_ 2364592382 EngCyl24ExcludeFromCombustionRq 5;
BA_ "SPN" SG_ 2364592382 EngCyl23ExcludeFromCombustionRq 7014;
BA_ "SigType" SG_ 2364592382 EngCyl23ExcludeFromCombustionRq 5;
BA_ "SPN" SG_ 2364592382 EngCyl22ExcludeFromCombustionRq 7013;
BA_ "SigType" SG_ 2364592382 EngCyl22ExcludeFromCombustionRq 5;
BA_ "SPN" SG_ 2364592382 EngCyl21ExcludeFromCombustionRq 7012;
BA_ "SigType" SG_ 2364592382 EngCyl21ExcludeFromCombustionRq 5;
BA_ "SPN" SG_ 2364592382 EngCyl20ExcludeFromCombustionRq 7011;
BA_ "SigType" SG_ 2364592382 EngCyl20ExcludeFromCombustionRq 5;
BA_ "SPN" SG_ 2364592382 EngCyl19ExcludeFromCombustionRq 7010;
BA_ "SigType" SG_ 2364592382 EngCyl19ExcludeFromCombustionRq 5;
BA_ "SPN" SG_ 2364592382 EngCyl18ExcludeFromCombustionRq 7009;
BA_ "SigType" SG_ 2364592382 EngCyl18ExcludeFromCombustionRq 5;
BA_ "SPN" SG_ 2364592382 EngCyl17ExcludeFromCombustionRq 7008;
BA_ "SigType" SG_ 2364592382 EngCyl17ExcludeFromCombustionRq 5;
BA_ "SPN" SG_ 2364592382 EngCyl16ExcludeFromCombustionRq 7007;
BA_ "SigType" SG_ 2364592382 EngCyl16ExcludeFromCombustionRq 5;
BA_ "SPN" SG_ 2364592382 EngCyl15ExcludeFromCombustionRq 7006;
BA_ "SigType" SG_ 2364592382 EngCyl15ExcludeFromCombustionRq 5;
BA_ "SPN" SG_ 2364592382 EngCyl14ExcludeFromCombustionRq 7005;
BA_ "SigType" SG_ 2364592382 EngCyl14ExcludeFromCombustionRq 5;
BA_ "SPN" SG_ 2364592382 EngCyl13ExcludeFromCombustionRq 7004;
BA_ "SigType" SG_ 2364592382 EngCyl13ExcludeFromCombustionRq 5;
BA_ "SPN" SG_ 2364592382 EngCyl12ExcludeFromCombustionRq 7003;
BA_ "SigType" SG_ 2364592382 EngCyl12ExcludeFromCombustionRq 5;
BA_ "SPN" SG_ 2364592382 EngCyl11ExcludeFromCombustionRq 7002;
BA_ "SigType" SG_ 2364592382 EngCyl11ExcludeFromCombustionRq 5;
BA_ "SPN" SG_ 2364592382 EngCyl10ExcludeFromCombustionRq 7001;
BA_ "SigType" SG_ 2364592382 EngCyl10ExcludeFromCombustionRq 5;
BA_ "SPN" SG_ 2364592382 EngCyl9ExcludeFromCombustionRq 7000;
BA_ "SigType" SG_ 2364592382 EngCyl9ExcludeFromCombustionRq 5;
BA_ "SPN" SG_ 2364592382 EngCyl8ExcludeFromCombustionRq 6999;
BA_ "SigType" SG_ 2364592382 EngCyl8ExcludeFromCombustionRq 5;
BA_ "SPN" SG_ 2364592382 EngCyl7ExcludeFromCombustionRq 6998;
BA_ "SigType" SG_ 2364592382 EngCyl7ExcludeFromCombustionRq 5;
BA_ "SPN" SG_ 2364592382 EngCyl6ExcludeFromCombustionRq 6997;
BA_ "SigType" SG_ 2364592382 EngCyl6ExcludeFromCombustionRq 5;
BA_ "SPN" SG_ 2364592382 EngCyl5ExcludeFromCombustionRq 6996;
BA_ "SigType" SG_ 2364592382 EngCyl5ExcludeFromCombustionRq 5;
BA_ "SPN" SG_ 2364592382 EngCyl4ExcludeFromCombustionRq 6995;
BA_ "SigType" SG_ 2364592382 EngCyl4ExcludeFromCombustionRq 5;
BA_ "SPN" SG_ 2364592382 EngCyl3ExcludeFromCombustionRq 6994;
BA_ "SigType" SG_ 2364592382 EngCyl3ExcludeFromCombustionRq 5;
BA_ "SPN" SG_ 2364592382 EngCyl2ExcludeFromCombustionRq 6993;
BA_ "SigType" SG_ 2364592382 EngCyl2ExcludeFromCombustionRq 5;
BA_ "SPN" SG_ 2364592382 EngCyl1ExcludeFromCombustionRq 6992;
BA_ "SigType" SG_ 2364592382 EngCyl1ExcludeFromCombustionRq 5;
BA_ "SPN" SG_ 2364592382 NmbrOfEngCylndrsTExcldFrmCmbston 6991;
BA_ "SigType" SG_ 2364592382 NmbrOfEngCylndrsTExcldFrmCmbston 1;
BA_ "SPN" SG_ 2364567294 EngFlInjctnPump2FuelCtrlValveCmd 6720;
BA_ "SigType" SG_ 2364567294 EngFlInjctnPump2FuelCtrlValveCmd 1;
BA_ "SPN" SG_ 2364567294 EngFlInjctnPump1FuelCtrlValveCmd 6719;
BA_ "SigType" SG_ 2364567294 EngFlInjctnPump1FuelCtrlValveCmd 1;
BA_ "SPN" SG_ 2558918398 EngIdleMnmgtPendingEventOvrd 9374;
BA_ "SigType" SG_ 2558918398 EngIdleMnmgtPendingEventOvrd 5;
BA_ "SPN" SG_ 2558918398 ActiveShiftConsoleReq 8855;
BA_ "SigType" SG_ 2558918398 ActiveShiftConsoleReq 5;
BA_ "SPN" SG_ 2558918398 AFTSysEnableCmd 8148;
BA_ "SigType" SG_ 2558918398 AFTSysEnableCmd 5;
BA_ "SPN" SG_ 2558918398 EngStopStartDisCmd 7759;
BA_ "SigType" SG_ 2558918398 EngStopStartDisCmd 5;
BA_ "SPN" SG_ 2558918398 TransAutoNeutralEnableSw 7694;
BA_ "SigType" SG_ 2558918398 TransAutoNeutralEnableSw 5;
BA_ "SPN" SG_ 2558918398 AFTRegenEngSpdAllowedSw 7580;
BA_ "SigType" SG_ 2558918398 AFTRegenEngSpdAllowedSw 4;
BA_ "SPN" SG_ 2558918398 ElevatedEngSpdAllowedSw 7579;
BA_ "SigType" SG_ 2558918398 ElevatedEngSpdAllowedSw 4;
BA_ "SPN" SG_ 2558918398 PrdctvCriseCtrlMaxNegativeOffset 7439;
BA_ "SigType" SG_ 2558918398 PrdctvCriseCtrlMaxNegativeOffset 1;
BA_ "SPN" SG_ 2558918398 PrdctvCriseCtrlMaxPositiveOffset 7438;
BA_ "SigType" SG_ 2558918398 PrdctvCriseCtrlMaxPositiveOffset 1;
BA_ "SPN" SG_ 2558918398 PrdctiveCruiseCtrlDeactivationRq 7437;
BA_ "SigType" SG_ 2558918398 PrdctiveCruiseCtrlDeactivationRq 4;
BA_ "SPN" SG_ 2558918398 PredictiveCruiseCtrlEnableSwitch 7436;
BA_ "SigType" SG_ 2558918398 PredictiveCruiseCtrlEnableSwitch 4;
BA_ "SPN" SG_ 2558918398 HtExchngerDebrisPurgeForceSwitch 7034;
BA_ "SigType" SG_ 2558918398 HtExchngerDebrisPurgeForceSwitch 4;
BA_ "SPN" SG_ 2558918398 HtExchngrDbrisPurgeInhibitSwitch 7033;
BA_ "SigType" SG_ 2558918398 HtExchngrDbrisPurgeInhibitSwitch 4;
BA_ "SPN" SG_ 2558918398 SCROprtrInducementOverrideSwitch 6881;
BA_ "SigType" SG_ 2558918398 SCROprtrInducementOverrideSwitch 5;
BA_ "SPN" SG_ 2558918398 PerformanceBiasSelection 6874;
BA_ "SigType" SG_ 2558918398 PerformanceBiasSelection 1;
BA_ "SPN" SG_ 2558918398 EngFan2RequestedPercentSpeed 6730;
BA_ "SigType" SG_ 2558918398 EngFan2RequestedPercentSpeed 1;
BA_ "SPN" SG_ 2558852862 ExhVelocity 6829;
BA_ "SigType" SG_ 2558852862 ExhVelocity 1;
BA_ "SPN" SG_ 2558852862 ExhTemp 6785;
BA_ "SigType" SG_ 2558852862 ExhTemp 1;
BA_ "SPN" SG_ 2558852862 Dewpoint 6784;
BA_ "SigType" SG_ 2558852862 Dewpoint 5;
BA_ "SPN" SG_ 2558852862 RegenReq 6783;
BA_ "SigType" SG_ 2558852862 RegenReq 5;
BA_ "SPN" SG_ 2558852862 ShutdownReq 6782;
BA_ "SigType" SG_ 2558852862 ShutdownReq 5;
BA_ "SPN" SG_ 2558787326 PayloadCorrectionFactorCmd 6873;
BA_ "SigType" SG_ 2558787326 PayloadCorrectionFactorCmd 1;
BA_ "SPN" SG_ 2558787326 PayloadCalibCommandedWeight 6872;
BA_ "SigType" SG_ 2558787326 PayloadCalibCommandedWeight 1;
BA_ "SPN" SG_ 2558787326 PayloadCalibSetPointCmd 6871;
BA_ "SPN" SG_ 2558721790 SnsrEnableSetting 7587;
BA_ "SigType" SG_ 2558721790 SnsrEnableSetting 5;
BA_ "SPN" SG_ 2558721790 OverTempSetting 6978;
BA_ "SigType" SG_ 2558721790 OverTempSetting 1;
BA_ "SPN" SG_ 2558721790 OvrPrssPrcentageThresholdSetting 6977;
BA_ "SigType" SG_ 2558721790 OvrPrssPrcentageThresholdSetting 1;
BA_ "SPN" SG_ 2558721790 ExtrmUndrPrssPrcntgThrshldStting 6976;
BA_ "SigType" SG_ 2558721790 ExtrmUndrPrssPrcntgThrshldStting 1;
BA_ "SPN" SG_ 2558721790 UndrPrssPrcntageThresholdSetting 6975;
BA_ "SigType" SG_ 2558721790 UndrPrssPrcntageThresholdSetting 1;
BA_ "SPN" SG_ 2558721790 ColdInflationPressSetting 6974;
BA_ "SigType" SG_ 2558721790 ColdInflationPressSetting 1;
BA_ "SPN" SG_ 2558721790 TireLocation 6973;
BA_ "SPN" SG_ 2558656254 DEFDoserReadyStatus 8149;
BA_ "SigType" SG_ 2558656254 DEFDoserReadyStatus 5;
BA_ "SPN" SG_ 2558656254 EnableStatus 7851;
BA_ "SigType" SG_ 2558656254 EnableStatus 5;
BA_ "SPN" SG_ 2558656254 RqToPermitDEFDosingTestInjection 7516;
BA_ "SPN" SG_ 2558656254 RqToPermitDEFHydStiffnessCheck 7515;
BA_ "SigType" SG_ 2558656254 RqToPermitDEFHydStiffnessCheck 5;
BA_ "SPN" SG_ 2558656254 ThermalMnmgtInhReq 7331;
BA_ "SigType" SG_ 2558656254 ThermalMnmgtInhReq 5;
BA_ "SPN" SG_ 2558590718 PropulsionModeReqDist 9707;
BA_ "SigType" SG_ 2558590718 PropulsionModeReqDist 1;
BA_ "SPN" SG_ 2558590718 PropulsionModeReqMaxSpd 9706;
BA_ "SigType" SG_ 2558590718 PropulsionModeReqMaxSpd 1;
BA_ "SPN" SG_ 2558590718 StoredESSetPointReq 7892;
BA_ "SigType" SG_ 2558590718 StoredESSetPointReq 1;
BA_ "SPN" SG_ 2558590718 StoredESCharge_DischargeRateReq 7891;
BA_ "SigType" SG_ 2558590718 StoredESCharge_DischargeRateReq 1;
BA_ "SPN" SG_ 2558590718 ExtlESConnectionDemand 7890;
BA_ "SPN" SG_ 2558590718 PropulsionModeReq 7889;
BA_ "SPN" SG_ 2558590718 OpVehModeReq 7888;
BA_ "SPN" SG_ 2558590718 ShutdownCmd 7560;
BA_ "SigType" SG_ 2558590718 ShutdownCmd 5;
BA_ "SPN" SG_ 2558590718 PropulsionDisableReq 7558;
BA_ "SigType" SG_ 2558590718 PropulsionDisableReq 5;
BA_ "SPN" SG_ 2558590718 HybrdSystmRgnrtvBrakingDisableRq 7559;
BA_ "SigType" SG_ 2558590718 HybrdSystmRgnrtvBrakingDisableRq 5;
BA_ "SPN" SG_ 2558590718 HybridSystemProtectionOverrideRq 7557;
BA_ "SigType" SG_ 2558590718 HybridSystemProtectionOverrideRq 5;
BA_ "SPN" SG_ 2350776062 EngTimingAdvance 7355;
BA_ "SigType" SG_ 2350776062 EngTimingAdvance 1;
BA_ "SPN" SG_ 2350710526 MessageChecksum 7042;
BA_ "SPN" SG_ 2350710526 TransRequestedTorque_TorqueLimit 7040;
BA_ "SigType" SG_ 2350710526 TransRequestedTorque_TorqueLimit 1;
BA_ "SPN" SG_ 2350710526 TransRequestedOutputShaftSpeed 7039;
BA_ "GenSigStartValue" SG_ 2350710526 TransRequestedOutputShaftSpeed 2;
BA_ "SigType" SG_ 2350710526 TransRequestedOutputShaftSpeed 1;
BA_ "SPN" SG_ 2350710526 MessageCounter 7041;
BA_ "SPN" SG_ 2350710526 TransOverrideCtrlModePriority 7038;
BA_ "SigType" SG_ 2350710526 TransOverrideCtrlModePriority 5;
BA_ "SPN" SG_ 2350710526 TransOverrideCtrlMode 7037;
BA_ "SigType" SG_ 2350710526 TransOverrideCtrlMode 5;
BA_ "SPN" SG_ 2582642430 ManufacturerSpecificInformation 3328;
BA_ "SPN" SG_ 2566801918 GroundBasedDirection 1861;
BA_ "SigType" SG_ 2566801918 GroundBasedDirection 4;
BA_ "SPN" SG_ 2566801918 GroundBasedImplementDistance 1860;
BA_ "SPN" SG_ 2566801918 GroundBasedImplementSpeed 1859;
BA_ "SPN" SG_ 2566801662 KeySwitchNOTOFF 1865;
BA_ "SigType" SG_ 2566801662 KeySwitchNOTOFF 4;
BA_ "SPN" SG_ 2566801662 WheelBasedDirection 1864;
BA_ "SigType" SG_ 2566801662 WheelBasedDirection 4;
BA_ "SPN" SG_ 2566801662 MaxTimeOfTractorPower 1866;
BA_ "SPN" SG_ 2566801662 WheelBasedDistance 1863;
BA_ "SPN" SG_ 2566801662 WheelBasedSpeed 1862;
BA_ "SPN" SG_ 2566801406 ImplementInWorkState 7447;
BA_ "SigType" SG_ 2566801406 ImplementInWorkState 4;
BA_ "SPN" SG_ 2566801406 ImplementTransportState 1869;
BA_ "SigType" SG_ 2566801406 ImplementTransportState 4;
BA_ "SPN" SG_ 2566801406 ImplementParkState 1870;
BA_ "SigType" SG_ 2566801406 ImplementParkState 4;
BA_ "SPN" SG_ 2566801406 ImplementWorkState 1871;
BA_ "SigType" SG_ 2566801406 ImplementWorkState 4;
BA_ "SPN" SG_ 2566801406 MaintainECUPower 1867;
BA_ "SigType" SG_ 2566801406 MaintainECUPower 4;
BA_ "SPN" SG_ 2566801406 MaintainAcuatorPower 1868;
BA_ "SigType" SG_ 2566801406 MaintainAcuatorPower 4;
BA_ "SPN" SG_ 2566801150 FrontDraft 1878;
BA_ "SPN" SG_ 2566801150 FrontNominalLowerLinkForce 1880;
BA_ "SPN" SG_ 2566801150 FrontHitchInworkIndication 1876;
BA_ "SigType" SG_ 2566801150 FrontHitchInworkIndication 4;
BA_ "SPN" SG_ 2566801150 FrontHitchPos 1872;
BA_ "SPN" SG_ 2566800894 RearHitchExit_reasonCode 5819;
BA_ "SPN" SG_ 2566800894 RearDraft 1879;
BA_ "SPN" SG_ 2566800894 RearNominalLowerLinkForce 1881;
BA_ "SPN" SG_ 2566800894 RearHitchInworkIndication 1877;
BA_ "SigType" SG_ 2566800894 RearHitchInworkIndication 4;
BA_ "SPN" SG_ 2566800894 RearHitchPos 1873;
BA_ "SPN" SG_ 2566800638 FrontPTOExit_reasonCode 5817;
BA_ "SPN" SG_ 2566800638 FrontHitchExit_reasonCode 5816;
BA_ "SPN" SG_ 2566800638 FrontPowerTakeOffEngagement 1888;
BA_ "SigType" SG_ 2566800638 FrontPowerTakeOffEngagement 4;
BA_ "SPN" SG_ 2566800638 FrontPowerTakeOffMode 1889;
BA_ "SigType" SG_ 2566800638 FrontPowerTakeOffMode 4;
BA_ "SPN" SG_ 2566800638 FrontPowerTakeOffEconomyMode 1891;
BA_ "SigType" SG_ 2566800638 FrontPowerTakeOffEconomyMode 4;
BA_ "SPN" SG_ 2566800638 FrontPTOOutputShaftSpeedSetPoint 1884;
BA_ "SPN" SG_ 2566800638 FrontPTOOutputShaftSpeed 1882;
BA_ "SPN" SG_ 2566800382 RearPTOExit_reasonCode 5820;
BA_ "SPN" SG_ 2566800382 RearPowerTakeOffEngagement 2408;
BA_ "SigType" SG_ 2566800382 RearPowerTakeOffEngagement 4;
BA_ "SPN" SG_ 2566800382 RearPowerTakeOffMode 1890;
BA_ "SigType" SG_ 2566800382 RearPowerTakeOffMode 4;
BA_ "SPN" SG_ 2566800382 RearPowerTakeOffEconomyMode 1892;
BA_ "SigType" SG_ 2566800382 RearPowerTakeOffEconomyMode 4;
BA_ "SPN" SG_ 2566800382 RearPTOOutputShaftSpeedSetPoint 1885;
BA_ "SPN" SG_ 2566800382 RearPTOOutputShaftSpeed 1883;
BA_ "SPN" SG_ 2566800126 FrontPowerTakeOffModeCmd 1895;
BA_ "SigType" SG_ 2566800126 FrontPowerTakeOffModeCmd 4;
BA_ "SPN" SG_ 2566800126 RearPowerTakeOffModeCmd 1896;
BA_ "SigType" SG_ 2566800126 RearPowerTakeOffModeCmd 4;
BA_ "SPN" SG_ 2566800126 FrontPowerTakeOffEconomyModeCmd 1897;
BA_ "SigType" SG_ 2566800126 FrontPowerTakeOffEconomyModeCmd 4;
BA_ "SPN" SG_ 2566800126 RearPowerTakeOffEconomyModeCmd 1898;
BA_ "SigType" SG_ 2566800126 RearPowerTakeOffEconomyModeCmd 4;
BA_ "SPN" SG_ 2566800126 FrontPowerTakeOffEngagementCmd 1893;
BA_ "SigType" SG_ 2566800126 FrontPowerTakeOffEngagementCmd 4;
BA_ "SPN" SG_ 2566800126 RearPowerTakeOffEngagementCmd 1894;
BA_ "SigType" SG_ 2566800126 RearPowerTakeOffEngagementCmd 4;
BA_ "SPN" SG_ 2566800126 RrPTOOutputShaftSpeedSetPointCmd 1887;
BA_ "SPN" SG_ 2566800126 FrntPTOOtptShaftSpeedSetPointCmd 1886;
BA_ "SPN" SG_ 2566800126 RearHitchPosCmd 1875;
BA_ "SPN" SG_ 2566800126 FrontHitchPosCmd 1874;
BA_ "SPN" SG_ 2566799358 AuxValve15FailSafeModeCmd 2345;
BA_ "SigType" SG_ 2566799358 AuxValve15FailSafeModeCmd 4;
BA_ "SPN" SG_ 2566799358 AuxValve15StateCmd 2344;
BA_ "SPN" SG_ 2566799358 AuxValve15PortFlowCmd 2343;
BA_ "SPN" SG_ 2566799102 AuxValve14FailSafeModeCmd 2333;
BA_ "SigType" SG_ 2566799102 AuxValve14FailSafeModeCmd 4;
BA_ "SPN" SG_ 2566799102 AuxValve14StateCmd 2332;
BA_ "SPN" SG_ 2566799102 AuxValve14PortFlowCmd 2331;
BA_ "SPN" SG_ 2566798846 AuxValve13FailSafeModeCmd 2321;
BA_ "SigType" SG_ 2566798846 AuxValve13FailSafeModeCmd 4;
BA_ "SPN" SG_ 2566798846 AuxValve13StateCmd 2320;
BA_ "SPN" SG_ 2566798846 AuxValve13PortFlowCmd 2319;
BA_ "SPN" SG_ 2566798590 AuxValve12FailSafeModeCmd 2309;
BA_ "SigType" SG_ 2566798590 AuxValve12FailSafeModeCmd 4;
BA_ "SPN" SG_ 2566798590 AuxValve12StateCmd 2308;
BA_ "SPN" SG_ 2566798590 AuxValve12PortFlowCmd 2307;
BA_ "SPN" SG_ 2566798334 AuxValve11FailSafeModeCmd 2297;
BA_ "SigType" SG_ 2566798334 AuxValve11FailSafeModeCmd 4;
BA_ "SPN" SG_ 2566798334 AuxValve11StateCmd 2296;
BA_ "SPN" SG_ 2566798334 AuxValve11PortFlowCmd 2295;
BA_ "SPN" SG_ 2566798078 AuxValve10FailSafeModeCmd 2285;
BA_ "SigType" SG_ 2566798078 AuxValve10FailSafeModeCmd 4;
BA_ "SPN" SG_ 2566798078 AuxValve10StateCmd 2284;
BA_ "SPN" SG_ 2566798078 AuxValve10PortFlowCmd 2283;
BA_ "SPN" SG_ 2566797822 AuxValve9FailSafeModeCmd 2273;
BA_ "SigType" SG_ 2566797822 AuxValve9FailSafeModeCmd 4;
BA_ "SPN" SG_ 2566797822 AuxValve9StateCmd 2272;
BA_ "SPN" SG_ 2566797822 AuxValve9PortFlowCmd 2271;
BA_ "SPN" SG_ 2566797566 AuxValve8FailSafeModeCmd 2261;
BA_ "SigType" SG_ 2566797566 AuxValve8FailSafeModeCmd 4;
BA_ "SPN" SG_ 2566797566 AuxValve8StateCmd 2260;
BA_ "SPN" SG_ 2566797566 AuxValve8PortFlowCmd 2259;
VAL_ 2566668030 HtExchngerDebrisPurgeApproaching 3 "Not available" 2 "SAE reserved" 1 "Approaching" 0 "Not approaching" ;
VAL_ 2566668030 HeatExchangerDebrisPurgeStatus 3 "Not available" 2 "SAE reserved" 1 "Active" 0 "Inactive" ;
VAL_ 2499556094 HtrPwrSupplyDiagStatus 7 "Not Available" 3 "Enable or pause conditions have allowed tests to execute this power cycle" 2 "Enable or pause conditions have allowed tests to execute this power cycle" 1 "Tests supported but not completed this power cycle" 0 "Tests monitored continuously" ;
VAL_ 2499556094 PwrSupplyDiagStatus 7 "Not Available" 3 "Enable or pause conditions have allowed tests to execute this power cycle" 2 "Enable or pause conditions have allowed tests to execute this power cycle" 1 "Tests supported but not completed this power cycle" 0 "Tests monitored continuously" ;
VAL_ 2499556094 InputDiagStatus 7 "Not Available" 3 "Enable or pause conditions have allowed tests to execute this power cycle" 2 "Enable or pause conditions have allowed tests to execute this power cycle" 1 "Tests supported but not completed this power cycle" 0 "Tests monitored continuously" ;
VAL_ 2499556094 HtrLowSideDriverDiagStatus 7 "Not Available" 3 "Enable or pause conditions have allowed tests to execute this power cycle" 2 "Enable or pause conditions have allowed tests to execute this power cycle" 1 "Tests supported but not completed this power cycle" 0 "Tests monitored continuously" ;
VAL_ 2499556094 HtrHiSideDriverDiagStatus 7 "Not Available" 3 "Enable or pause conditions have allowed tests to execute this power cycle" 2 "Enable or pause conditions have allowed tests to execute this power cycle" 1 "Tests supported but not completed this power cycle" 0 "Tests monitored continuously" ;
VAL_ 2566664702 DEFDosingModeStatus 7 "Not Available" 6 "Error" 5 "Reserved" 4 "Reserved" 3 "Reserved" 2 "Reserved" 1 "Reduced DEF Dosing Mode" 0 "Standard DEF Dosing Mode" ;
VAL_ 2566664702 DEFQualityMalfunctionEPActive 3 "Not supported" 2 "SAE reserved" 1 "Active" 0 "Not active" ;
VAL_ 2566664702 DEFHtrCircuitBreaker 3 "not available" 2 "error" 1 "on" 0 "off" ;
VAL_ 2566664702 EngLoadReq 3 "Not Available" 2 "Urgent Aftertreatment Engine Load Desired" 1 "Aftertreatment Engine Load Desired" 0 "No Request" ;
VAL_ 2566664702 EngSpdIncreaseReq 3 "Not Available" 2 "Urgent Aftertreatment Engine Speed Control Desired" 1 "Aftertreatment Engine Speed Control Desired" 0 "No Request" ;
VAL_ 2566664702 ActiveRegenInhibitedDueToLowEP 3 "Not Available" 2 "Reserved for SAE assignment" 1 "Inhibited" 0 "Not Inhibited" ;
VAL_ 2566664702 ThermalMnmgtStatus 3 "Not available" 2 "Reserved for SAE assignment" 1 "Active" 0 "Not active" ;
VAL_ 2633773310 SCROprtrIndcmntOvrrdRnwlRequired 3 "Not Available" 2 "Error" 1 "Required" 0 "Not Required" ;
VAL_ 2633773310 SCROpratorInducementOverrideMode 4 "Expired" 3 "Active Extended" 2 "Active" 1 "Available" 0 "Not Available" 7 "Not Available" ;
VAL_ 2566663934 WastegateAct2MotorCurDis 3 "Don't Care/Take No Action" 2 "Reserved" 1 "Disable" 0 "Do Not Disable" ;
VAL_ 2566663934 CompressorBypassAct2MotorCurDis 3 "Don't Care/Take No Action" 2 "Reserved" 1 "Disable" 0 "Do Not Disable" ;
VAL_ 2566663934 CompressorBypassAct1MotorCurDis 3 "Don't Care/Take No Action" 2 "Reserved" 1 "Disable" 0 "Do Not Disable" ;
VAL_ 2566663934 EngThrttlVlv1MotorCurrentDisable 3 "Don't Care/Take No Action" 2 "Reserved" 1 "Disable" 0 "Do Not Disable" ;
VAL_ 2566663934 EngCylHdBypssActtr1MtrCrrntDsble 3 "Don't Care/Take No Action" 2 "Reserved" 1 "Disable" 0 "Do Not Disable" ;
VAL_ 2566663934 EngTrbWstgtActtr1MtrCrrntDisable 3 "Don't Care/Take No Action" 2 "Reserved" 1 "Disable" 0 "Do Not Disable" ;
VAL_ 2566663934 EngTrbCmprssrBlwffActtr1MtrCrrnt 3 "Don't Care/Take No Action" 2 "Reserved" 1 "Disable" 0 "Do Not Disable" ;
VAL_ 2566663422 TrlrBrkClprLnngClranceAxle5Right 3 "Not available / not applicable" 2 "Error" 1 "Caliper lining clearance is low" 0 "Caliper lining clearance is adequate" ;
VAL_ 2566663422 TrlrBrkClprLnngClaranceAxle5Left 3 "Not available / not applicable" 2 "Error" 1 "Caliper lining clearance is low" 0 "Caliper lining clearance is adequate" ;
VAL_ 2566663422 TrlrBrkClprLnngClranceAxle4Right 3 "Not available / not applicable" 2 "Error" 1 "Caliper lining clearance is low" 0 "Caliper lining clearance is adequate" ;
VAL_ 2566663422 TrlrBrkClprLnngClaranceAxle4Left 3 "Not available / not applicable" 2 "Error" 1 "Caliper lining clearance is low" 0 "Caliper lining clearance is adequate" ;
VAL_ 2566663422 TrlrBrkClprLnngClranceAxle3Right 3 "Not available / not applicable" 2 "Error" 1 "Caliper lining clearance is low" 0 "Caliper lining clearance is adequate" ;
VAL_ 2566663422 TrlrBrkClprLnngClaranceAxle3Left 3 "Not available / not applicable" 2 "Error" 1 "Caliper lining clearance is low" 0 "Caliper lining clearance is adequate" ;
VAL_ 2566663422 TrlrBrkClprLnngClranceAxle2Right 3 "Not available / not applicable" 2 "Error" 1 "Caliper lining clearance is low" 0 "Caliper lining clearance is adequate" ;
VAL_ 2566663422 TrlrBrkClprLnngClaranceAxle2Left 3 "Not available / not applicable" 2 "Error" 1 "Caliper lining clearance is low" 0 "Caliper lining clearance is adequate" ;
VAL_ 2566663422 TrlrBrkClprLnngClranceAxle1Right 3 "Not available / not applicable" 2 "Error" 1 "Caliper lining clearance is low" 0 "Caliper lining clearance is adequate" ;
VAL_ 2566663422 TrlrBrkClprLnngClaranceAxle1Left 3 "Not available / not applicable" 2 "Error" 1 "Caliper lining clearance is low" 0 "Caliper lining clearance is adequate" ;
VAL_ 2566663422 TrctrBrkClprLnngClrnceAxle5Right 3 "Not available / not applicable" 2 "Error" 1 "Caliper lining clearance is low" 0 "Caliper lining clearance is adequate" ;
VAL_ 2566663422 TrctrBrkClprLnngClranceAxle5Left 3 "Not available / not applicable" 2 "Error" 1 "Caliper lining clearance is low" 0 "Caliper lining clearance is adequate" ;
VAL_ 2566663422 TrctrBrkClprLnngClrnceAxle4Right 3 "Not available / not applicable" 2 "Error" 1 "Caliper lining clearance is low" 0 "Caliper lining clearance is adequate" ;
VAL_ 2566663422 TrctrBrkClprLnngClranceAxle4Left 3 "Not available / not applicable" 2 "Error" 1 "Caliper lining clearance is low" 0 "Caliper lining clearance is adequate" ;
VAL_ 2566663422 TrctrBrkClprLnngClrnceAxle3Right 3 "Not available / not applicable" 2 "Error" 1 "Caliper lining clearance is low" 0 "Caliper lining clearance is adequate" ;
VAL_ 2566663422 TrctrBrkClprLnngClranceAxle3Left 3 "Not available / not applicable" 2 "Error" 1 "Caliper lining clearance is low" 0 "Caliper lining clearance is adequate" ;
VAL_ 2566663422 TrctrBrkClprLnngClrnceAxle2Right 3 "Not available / not applicable" 2 "Error" 1 "Caliper lining clearance is low" 0 "Caliper lining clearance is adequate" ;
VAL_ 2566663422 TrctrBrkClprLnngClranceAxle2Left 3 "Not available / not applicable" 2 "Error" 1 "Caliper lining clearance is low" 0 "Caliper lining clearance is adequate" ;
VAL_ 2566663422 TrctrBrkClprLnngClrnceAxle1Right 3 "Not available / not applicable" 2 "Error" 1 "Caliper lining clearance is low" 0 "Caliper lining clearance is adequate" ;
VAL_ 2566663422 TrctrBrkClprLnngClranceAxle1Left 3 "Not available / not applicable" 2 "Error" 1 "Caliper lining clearance is low" 0 "Caliper lining clearance is adequate" ;
VAL_ 2566663166 EngExtlIdleReqFeedback 3 "Not available" 2 "Error" 1 "Idle Alteration Active" 0 "No Idle Alteration Active" ;
VAL_ 2566662654 LeftLaneMarkerType 15 "Not available" 14 "Error" 5 "Raised lane marker" 4 "Double lane marker" 3 "Dashed" 2 "Road edge" 1 "Solid" 0 "Processing or not identified" ;
VAL_ 2566662654 RightLaneMarkerType 15 "Not available" 14 "Error" 5 "Raised lane marker" 4 "Double lane marker" 3 "Dashed" 2 "Road edge" 1 "Solid" 0 "Processing or not identified" ;
VAL_ 2566662654 LaneMarkQualityOnTheRightSide 7 "not available or not installed" 6 "error" 3 "perfect recognition of lane marks" 2 "good reliablity of detected lane marks" 1 "low reliablity of detected lane marks" 0 "no lane marks detected" ;
VAL_ 2566662654 LaneMarkQualityOnTheLeftSide 7 "not available or not installed" 6 "error" 3 "perfect recognition of lane marks" 2 "good reliablity of detected lane marks" 1 "low reliablity of detected lane marks" 0 "no lane marks detected" ;
VAL_ 2566662654 LaneDepartureAngleRight 255 "not available or not installed" 254 "error" 253 "reserved / not used" 252 "not reliable" 251 "not in range" ;
VAL_ 2566662654 LaneDepartureAngleLeft 255 "not available or not installed" 254 "error" 253 "reserved / not used" 252 "not reliable" 251 "not in range" ;
VAL_ 2566662654 RghtDstncTLnMrkFrmVehiclesMiddle 255 "not available or not installed" 254 "error" 253 "reserved / not used" 252 "not reliable" 251 "not in range" ;
VAL_ 2566662654 LftDstncTLnMrkFromVehiclesMiddle 255 "not available or not installed" 254 "error" 253 "reserved / not used" 252 "not reliable" 251 "not in range" ;
VAL_ 2364593150 PrdctvCrsCtrlDrvlnDsnggInhibitRq 2 "Reserved" 1 "Driveline Disengage Inhibit Request" 0 "No Inhibit Request" 3 "Don't care/take no action" ;
VAL_ 2364593150 VhclSpdCtrlOvrrideEventIndicator 3 "Not available" 2 "Reserved" 1 "Speed Control event is active" 0 "Speed Control event is not active" ;
VAL_ 2364593150 PrdctvCrsCtrlSpeedEventIndicator 3 "Not available" 2 "Decreased speed event is active" 1 "Increased speed event is active" 0 "No speed event is active" ;
VAL_ 2364593150 PredictiveCruiseCtrlEventInRange 3 "Not available" 2 "Error" 1 "PCC event in range" 0 "No PCC event in range" ;
VAL_ 2364593150 VehicleSpeedCtrlOverrideRq 3 "Don't care/take no action" 2 "Reserved" 1 "Speed control override requested" 0 "No speed control override requested" ;
VAL_ 2364593150 PredictiveCruiseCtrlState 15 "Not Available" 14 "Error" 8 "Enabled,  but not functional due to self test" 7 "Enabled,  but not functional due to inhibited by driver" 6 "Enabled,  but not functional due to vehicle speed below speed threshold" 5 "Enabled,  but not functional due to predicted path not available" 4 "Enabled,  but not functional due to road grade info not available" 3 "Enabled,  but not functional due to map position not available" 2 "Enabled,  but not functional due to vehicle position not available" 1 "Enabled" 0 "Disabled" ;
VAL_ 2364592894 InAirSourceVlv 3 "Not available" 2 "Error" 1 "On" 0 "Off" ;
VAL_ 2364592638 EngCylHdBypssActtr1OprtionStatus 15 "Not available" 14 "Error" 6 "Calibration in Progress" 5 "Uncontrolled Shutdown Active" 4 "Controlled Shutdown Active" 3 "Derate Active" 2 "Alarm High Severity" 1 "Alarm" 0 "Normal" ;
VAL_ 2364592638 EngCylHdBypssActuator1TempStatus 7 "Not available" 6 "Error" 5 "Not Defined" 4 "Low Most severe" 3 "Low Least severe" 2 "In Range" 1 "High Least severe" 0 "High Most severe" ;
VAL_ 2364592382 EngCyl24ExcludeFromCombustionRq 1 "Include for Combustion" 0 "Exclude from Combustion" 3 "Not available/Do not care" 2 "Reserved" ;
VAL_ 2364592382 EngCyl23ExcludeFromCombustionRq 3 "Not available/Do not care" 2 "Reserved" 1 "Include for Combustion" 0 "Exclude from Combustion" ;
VAL_ 2364592382 EngCyl22ExcludeFromCombustionRq 3 "Not available/Do not care" 2 "Reserved" 1 "Include for Combustion" 0 "Exclude from Combustion" ;
VAL_ 2364592382 EngCyl21ExcludeFromCombustionRq 3 "Not available/Do not care" 2 "Reserved" 1 "Include for Combustion" 0 "Exclude from Combustion" ;
VAL_ 2364592382 EngCyl20ExcludeFromCombustionRq 3 "Not available/Do not care" 2 "Reserved" 1 "Include for Combustion" 0 "Exclude from Combustion" ;
VAL_ 2364592382 EngCyl19ExcludeFromCombustionRq 3 "Not available/Do not care" 2 "Reserved" 1 "Include for Combustion" 0 "Exclude from Combustion" ;
VAL_ 2364592382 EngCyl18ExcludeFromCombustionRq 3 "Not available/Do not care" 2 "Reserved" 1 "Include for Combustion" 0 "Exclude from Combustion" ;
VAL_ 2364592382 EngCyl17ExcludeFromCombustionRq 3 "Not available/Do not care" 2 "Reserved" 1 "Include for Combustion" 0 "Exclude from Combustion" ;
VAL_ 2364592382 EngCyl16ExcludeFromCombustionRq 3 "Not available/Do not care" 2 "Reserved" 1 "Include for Combustion" 0 "Exclude from Combustion" ;
VAL_ 2364592382 EngCyl15ExcludeFromCombustionRq 3 "Not available/Do not care" 2 "Reserved" 1 "Include for Combustion" 0 "Exclude from Combustion" ;
VAL_ 2364592382 EngCyl14ExcludeFromCombustionRq 3 "Not available/Do not care" 2 "Reserved" 1 "Include for Combustion" 0 "Exclude from Combustion" ;
VAL_ 2364592382 EngCyl13ExcludeFromCombustionRq 3 "Not available/Do not care" 2 "Reserved" 1 "Include for Combustion" 0 "Exclude from Combustion" ;
VAL_ 2364592382 EngCyl12ExcludeFromCombustionRq 3 "Not available/Do not care" 2 "Reserved" 1 "Include for Combustion" 0 "Exclude from Combustion" ;
VAL_ 2364592382 EngCyl11ExcludeFromCombustionRq 3 "Not available/Do not care" 2 "Reserved" 1 "Include for Combustion" 0 "Exclude from Combustion" ;
VAL_ 2364592382 EngCyl10ExcludeFromCombustionRq 3 "Not available/Do not care" 2 "Reserved" 1 "Include for Combustion" 0 "Exclude from Combustion" ;
VAL_ 2364592382 EngCyl9ExcludeFromCombustionRq 3 "Not available/Do not care" 2 "Reserved" 1 "Include for Combustion" 0 "Exclude from Combustion" ;
VAL_ 2364592382 EngCyl8ExcludeFromCombustionRq 3 "Not available/Do not care" 2 "Reserved" 1 "Include for Combustion" 0 "Exclude from Combustion" ;
VAL_ 2364592382 EngCyl7ExcludeFromCombustionRq 3 "Not available/Do not care" 2 "Reserved" 1 "Include for Combustion" 0 "Exclude from Combustion" ;
VAL_ 2364592382 EngCyl6ExcludeFromCombustionRq 3 "Not available/Do not care" 2 "Reserved" 1 "Include for Combustion" 0 "Exclude from Combustion" ;
VAL_ 2364592382 EngCyl5ExcludeFromCombustionRq 3 "Not available/Do not care" 2 "Reserved" 1 "Include for Combustion" 0 "Exclude from Combustion" ;
VAL_ 2364592382 EngCyl4ExcludeFromCombustionRq 3 "Not available/Do not care" 2 "Reserved" 1 "Include for Combustion" 0 "Exclude from Combustion" ;
VAL_ 2364592382 EngCyl3ExcludeFromCombustionRq 3 "Not available/Do not care" 2 "Reserved" 1 "Include for Combustion" 0 "Exclude from Combustion" ;
VAL_ 2364592382 EngCyl2ExcludeFromCombustionRq 3 "Not available/Do not care" 2 "Reserved" 1 "Include for Combustion" 0 "Exclude from Combustion" ;
VAL_ 2364592382 EngCyl1ExcludeFromCombustionRq 3 "Not available/Do not care" 2 "Reserved" 1 "Include for Combustion" 0 "Exclude from Combustion" ;
VAL_ 2558918398 EngIdleMnmgtPendingEventOvrd 3 "Not available" 2 "Error" 1 "On" 0 "Off" ;
VAL_ 2558918398 ActiveShiftConsoleReq 3 "Don't Care / Take No Action" 2 "Reserved" 1 "Use Secondary Shift Console" 0 "Use Primary Shift Console" ;
VAL_ 2558918398 AFTSysEnableCmd 3 "Don't care/Take no Action" 2 "Reserved" 1 "Activate Aftertreatment System" 0 "De-activate Aftertreatment System" ;
VAL_ 2558918398 EngStopStartDisCmd 3 "Don뭪 care/Take no action" 2 "Reserved" 1 "Automatic engine stop-start shall be disabled" 0 "Automatic engine stop-start may be allowed" ;
VAL_ 2558918398 TransAutoNeutralEnableSw 3 "Not Available" 2 "Error" 1 "On" 0 "Off" ;
VAL_ 2558918398 AFTRegenEngSpdAllowedSw 3 "Not Available" 2 "Error" 1 "Aftertreatment regeneration is allowed when engine speed exceeds regeneration threshold" 0 "Aftertreatment regeneration is not allowed when engine speed exceeds regeneration threshold" ;
VAL_ 2558918398 ElevatedEngSpdAllowedSw 3 "Not Available" 2 "Error" 1 "Allowed to elevate engine speed" 0 "Not allowed to elevate engine speed" ;
VAL_ 2558918398 PrdctiveCruiseCtrlDeactivationRq 3 "Not available" 2 "Error" 1 "Predictive cruise control is requested to be deactived" 0 "Predictive cruise control is not requested to be deactived" ;
VAL_ 2558918398 PredictiveCruiseCtrlEnableSwitch 3 "Not available" 2 "Error" 1 "Predictive cruise control is enabled" 0 "Predictive cruise control is not enabled" ;
VAL_ 2558918398 HtExchngerDebrisPurgeForceSwitch 3 "not available" 2 "error" 1 "active" 0 "not active" ;
VAL_ 2558918398 HtExchngrDbrisPurgeInhibitSwitch 3 "not available" 2 "error" 1 "active" 0 "not active" ;
VAL_ 2558918398 SCROprtrInducementOverrideSwitch 3 "Not available" 2 "Error" 1 "On" 0 "Off" ;
VAL_ 2558852862 Dewpoint 3 "Not available" 2 "SAE reserved" 1 "Dewpoint has been reached" 0 "Dewpoint has not been reached" ;
VAL_ 2558852862 RegenReq 3 "Not available" 2 "SAE reserved" 1 "Regeneration requested" 0 "Regeneration not requested" ;
VAL_ 2558852862 ShutdownReq 3 "Not available" 2 "SAE reserved" 1 "Shutdown request active" 0 "Shutdown request not active" ;
VAL_ 2558787326 PayloadCalibSetPointCmd 15 "Not Available" 14 "Error" 13 "Reserved" 12 "Reset Calibration" 11 "Correction Point" 10 "End Point" 9 "Calibration Reference Point 9" 8 "Calibration Reference Point 8" 7 "Calibration Reference Point 7" 6 "Calibration Reference Point 6" 5 "Calibration Reference Point 5" 4 "Calibration Reference Point 4" 3 "Calibration Reference Point 3" 2 "Calibration Reference Point 2" 1 "Calibration Reference Point 1" 0 "Zero Point" ;
VAL_ 2558721790 SnsrEnableSetting 3 "Don뭪 Care / Take No Action" 2 "Reserved / Not Defined" 1 "On / Enable" 0 "Off / Isolate / Disable" ;
VAL_ 2558656254 DEFDoserReadyStatus 3 "Not available" 2 "Error" 1 "Aftertreatment Ready to Dose" 0 "Aftertreatment Not Ready to Dose" ;
VAL_ 2558656254 EnableStatus 3 "Not available" 2 "Error" 1 "Aftertreatment System is Enabled" 0 "Aftertreatment System is Disabled" ;
VAL_ 2558656254 RqToPermitDEFDosingTestInjection 7 "don't care" 2 "urgent request to permit DEF Dosing Test Injection or test injection is running" 1 "request to permit DEF Dosing Test Injection or test injection is running" 0 "no request" ;
VAL_ 2558656254 RqToPermitDEFHydStiffnessCheck 3 "don't care" 2 "reserved" 1 "request to permit DEF hydraulic stiffness check or stiffness check is running" 0 "no request" ;
VAL_ 2558656254 ThermalMnmgtInhReq 3 "Not Available" 2 "Reserved for SAE assignment" 1 "Inhibit" 0 "Do not inhibit" ;
VAL_ 2558590718 ExtlESConnectionDemand 15 "No Request/Take no action" 14 "Disconnect Request" 8 "Energy Drain Connection 2" 7 "Energy Source Connection 2" 6 "Energy Drain or Source Connection 2" 5 "Perform Connection 2 Verification" 4 "Energy Drain Connection 1" 3 "Energy Source Connection 1" 2 "Energy Drain or Source Connection 1" 1 "Perform Connection 1 Verification" 0 "No Connection" ;
VAL_ 2558590718 PropulsionModeReq 15 "Not Available" 14 "Error" 5 "Stored Energy Source Only" 4 "Stored Energy Source Offline" 3 "Stored Energy Source Depleting" 2 "Stored Energy Source Increasing" 1 "Stored Energy Source Sustaining" 0 "No mode requested" ;
VAL_ 2558590718 OpVehModeReq 15 "Not Available" 14 "Error" 3 "Propulsion Active" 2 "Stored Energy Source Active" 1 "Low Voltage Accessory" 0 "Off" ;
VAL_ 2558590718 ShutdownCmd 3 "Don't Care / Take No Action" 2 "Reserved" 1 "On" 0 "Off" ;
VAL_ 2558590718 PropulsionDisableReq 3 "Don't Care / Take No Action" 2 "Reserved" 1 "On" 0 "Off" ;
VAL_ 2558590718 HybrdSystmRgnrtvBrakingDisableRq 3 "Don't care / take no action" 2 "Reserved" 1 "Regenerative braking disable request is active" 0 "Regenerative braking disable request is not active" ;
VAL_ 2558590718 HybridSystemProtectionOverrideRq 3 "Don't care / take no action" 2 "Reserved" 1 "Active" 0 "Not active" ;
VAL_ 2350710526 TransOverrideCtrlModePriority 3 "Low priority" 2 "Medium priority" 1 "High priority" 0 "Highest priority" ;
VAL_ 2350710526 TransOverrideCtrlMode 3 "Speed/torque limit control" 2 "Torque control" 1 "Speed control" 0 "Override disabled" ;
VAL_ 2566801918 GroundBasedDirection 3 "Not available" 2 "Error indication" 1 "Forward" 0 "Reverse" ;
VAL_ 2566801662 KeySwitchNOTOFF 3 "Not available" 2 "Error indication" 1 "Key Switch Not Off" 0 "Key Switch Off" ;
VAL_ 2566801662 WheelBasedDirection 3 "Not available" 2 "Error indication" 1 "Forward" 0 "Reverse" ;
VAL_ 2566801406 ImplementInWorkState 3 "Not available" 2 "Error indication" 1 "Implement is 밿n-work�" 0 "Implement is 뱋ut of work�" ;
VAL_ 2566801406 ImplementTransportState 3 "Not available" 2 "Error indication" 1 "Implement may be transported" 0 "Implement may Not be transported " ;
VAL_ 2566801406 ImplementParkState 3 "Not available" 2 "Error indication" 1 "Implement may be disconnected" 0 "Implement may Not be disconnected " ;
VAL_ 2566801406 ImplementWorkState 3 "Not available" 2 "Error indication" 1 "Implement is ready for field work" 0 "Implement is Not ready for field work " ;
VAL_ 2566801406 MaintainECUPower 3 "Don뭪 Care" 2 "Reserved " 1 "Requirement for 2 more seconds of ECU_PWR" 0 "No Further Requirement for ECU_PWR" ;
VAL_ 2566801406 MaintainAcuatorPower 3 "Don뭪 Care" 2 "Reserved " 1 "Requirement for 2 more seconds of PWR" 0 "No Further Requirement for PWR" ;
VAL_ 2566801150 FrontHitchInworkIndication 3 "Not available" 2 "Error indication" 1 "Hitch position is in-work" 0 "Hitch position is out-of-work " ;
VAL_ 2566800894 RearHitchInworkIndication 3 "Not available" 2 "Error indication" 1 "Hitch position is in-work" 0 "Hitch position is out-of-work " ;
VAL_ 2566800638 FrontPowerTakeOffEngagement 3 "Not available" 2 "Error indication" 1 "Power take off engaged" 0 "Power take off disengaged" ;
VAL_ 2566800638 FrontPowerTakeOffMode 3 "Not available" 2 "Error indication" 1 "Power take off mode is 1000" 0 "Power take off mode is 540" ;
VAL_ 2566800638 FrontPowerTakeOffEconomyMode 3 "Not available" 2 "Error indication" 1 "Power take off economy mode is engaged" 0 "Power take off economy mode is disengaged" ;
VAL_ 2566800382 RearPowerTakeOffEngagement 3 "Not available" 2 "Error indication" 1 "Power take off engaged" 0 "Power take off disengaged" ;
VAL_ 2566800382 RearPowerTakeOffMode 3 "Not available" 2 "Error indication" 1 "Power take off mode is 1000" 0 "Power take off mode is 540" ;
VAL_ 2566800382 RearPowerTakeOffEconomyMode 3 "Not available" 2 "Error indication" 1 "Power take off economy mode is engaged" 0 "Power take off economy mode is disengaged" ;
VAL_ 2566800126 FrontPowerTakeOffModeCmd 3 "Don뭪 Care" 2 "Reserved" 1 "Select 1000 rpm mode " 0 "Select 540 rpm mode" ;
VAL_ 2566800126 RearPowerTakeOffModeCmd 3 "Don뭪 Care" 2 "Reserved" 1 "Select 1000 rpm mode " 0 "Select 540 rpm mode" ;
VAL_ 2566800126 FrontPowerTakeOffEconomyModeCmd 3 "Don뭪 Care" 2 "Reserved" 1 "Engage Power take off몊 economy mode" 0 "Disengage Power take off몊 economy mode" ;
VAL_ 2566800126 RearPowerTakeOffEconomyModeCmd 3 "Don뭪 Care" 2 "Reserved" 1 "Engage Power take off몊 economy mode" 0 "Disengage Power take off몊 economy mode" ;
VAL_ 2566800126 FrontPowerTakeOffEngagementCmd 3 "Don뭪 Care" 2 "Reserved" 1 "Engage Power take off " 0 "Disengage Power take off" ;
VAL_ 2566800126 RearPowerTakeOffEngagementCmd 3 "Don뭪 Care" 2 "Reserved" 1 "Engage Power take off " 0 "Disengage Power take off" ;
VAL_ 2566799358 AuxValve15FailSafeModeCmd 3 "Don뭪 Care" 2 "Reserved" 1 "Float" 0 "Block" ;
VAL_ 2566799358 AuxValve15StateCmd 15 "Don뭪 Care" 3 "Float" 2 "Retract" 1 "Extend" 0 "Block" ;
VAL_ 2566799102 AuxValve14FailSafeModeCmd 3 "Don뭪 Care" 2 "Reserved" 1 "Float" 0 "Block" ;
VAL_ 2566799102 AuxValve14StateCmd 3 "Float" 2 "Retract" 1 "Extend" 0 "Block" 15 "Don뭪 Care" ;
VAL_ 2566798846 AuxValve13FailSafeModeCmd 3 "Don뭪 Care" 2 "Reserved" 1 "Float" 0 "Block" ;
VAL_ 2566798846 AuxValve13StateCmd 15 "Don뭪 Care" 3 "Float" 2 "Retract" 1 "Extend" 0 "Block" ;
VAL_ 2566798590 AuxValve12FailSafeModeCmd 3 "Don뭪 Care" 2 "Reserved" 1 "Float" 0 "Block" ;
VAL_ 2566798590 AuxValve12StateCmd 15 "Don뭪 Care" 3 "Float" 2 "Retract" 1 "Extend" 0 "Block" ;
VAL_ 2566798334 AuxValve11FailSafeModeCmd 3 "Don뭪 Care" 2 "Reserved" 1 "Float" 0 "Block" ;
VAL_ 2566798334 AuxValve11StateCmd 15 "Don뭪 Care" 3 "Float" 2 "Retract" 1 "Extend" 0 "Block" ;
VAL_ 2566798078 AuxValve10FailSafeModeCmd 3 "Don뭪 Care" 2 "Reserved" 1 "Float" 0 "Block" ;
VAL_ 2566798078 AuxValve10StateCmd 15 "Don뭪 Care" 3 "Float" 2 "Retract" 1 "Extend" 0 "Block" ;
VAL_ 2566797822 AuxValve9FailSafeModeCmd 3 "Don뭪 Care" 2 "Reserved" 1 "Float" 0 "Block" ;
VAL_ 2566797822 AuxValve9StateCmd 15 "Don뭪 Care" 3 "Float" 2 "Retract" 1 "Extend" 0 "Block" ;
VAL_ 2566797566 AuxValve8FailSafeModeCmd 3 "Don뭪 Care" 2 "Reserved" 1 "Float" 0 "Block" ;
VAL_ 2566797566 AuxValve8StateCmd 15 "Don뭪 Care" 3 "Float" 2 "Retract" 1 "Extend" 0 "Block" ;
